VERSION ""

NS_ :

BS_:
BU_: GW IP HU TBOX AVM
BO_ 839 GW_347: 8 GW
 SG_ BCM_TirePresureSignalStatus : 55|1@0+ (1.0000000000,0.0000000000) [0.0000000000|1.0000000000] ""  GW,TBOX
 SG_ TPMS_SystemFailureWarning : 56|1@0+ (1.0000000000,0.0000000000) [0.0000000000|1.0000000000] ""  GW,IP
 SG_ TPMS_LRPressureWarning : 60|3@0+ (1.0000000000,0.0000000000) [0.0000000000|7.0000000000] ""  GW,TBOX,IP
 SG_ TPMS_RRPressureWarning : 63|3@0+ (1.0000000000,0.0000000000) [0.0000000000|7.0000000000] ""  GW,TBOX,IP
 SG_ TPMS_RFPressureWarning : 50|3@0+ (1.0000000000,0.0000000000) [0.0000000000|7.0000000000] ""  GW,TBOX,IP
 SG_ TPMS_LFPressureWarning : 54|3@0+ (1.0000000000,0.0000000000) [0.0000000000|7.0000000000] ""  GW,TBOX,IP
 SG_ TPMS_TireTemperature : 47|8@0+ (1.0000000000,-40.0000000000) [-40.0000000000|214.0000000000] "°C"  GW
 SG_ TPMS_LRTyrePressure : 39|8@0+ (1.3730000000,0.0000000000) [0.0000000000|350.0000000000] "KPa"  GW,TBOX,IP
 SG_ TPMS_RRTyrePressure : 31|8@0+ (1.3730000000,0.0000000000) [0.0000000000|350.0000000000] "KPa"  GW,TBOX,IP
 SG_ TPMS_RFTyrePressure : 23|8@0+ (1.3730000000,0.0000000000) [0.0000000000|350.0000000000] "KPa"  GW,TBOX,IP
 SG_ TPMS_LFTyrePressure : 15|8@0+ (1.3730000000,0.0000000000) [0.0000000000|350.0000000000] "KPa"  GW,TBOX,IP
 SG_ TPMS_TirePosition : 2|3@0+ (1.0000000000,0.0000000000) [0.0000000000|3.0000000000] ""  GW
 SG_ TPMS_LRTemperatureWarning : 3|1@0+ (1.0000000000,0.0000000000) [0.0000000000|1.0000000000] ""  GW,IP
 SG_ TPMS_RRTemperatureWarning : 4|1@0+ (1.0000000000,0.0000000000) [0.0000000000|1.0000000000] ""  GW,IP
 SG_ TPMS_RFTemperatureWarning : 5|1@0+ (1.0000000000,0.0000000000) [0.0000000000|1.0000000000] ""  GW,IP
 SG_ TPMS_LFTemperatureWarning : 6|1@0+ (1.0000000000,0.0000000000) [0.0000000000|1.0000000000] ""  GW,IP
 SG_ TPMS_SignalStatus : 7|1@0+ (1.0000000000,0.0000000000) [0.0000000000|1.0000000000] ""  GW,IP
 SG_ BCM_TirePresureSignalStatus : 55|1@0+ (1.0000000000,0.0000000000) [0.0000000000|1.0000000000] ""  IP,GW

BO_ 1025 IP_401: 8 IP

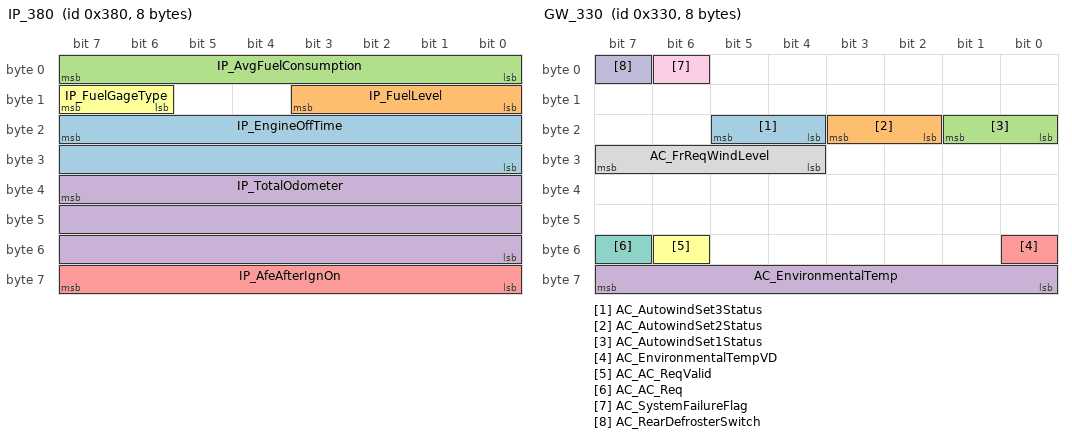
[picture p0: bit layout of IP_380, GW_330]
BO_ 896 IP_380: 8 IP
 SG_ IP_EngineOffTime : 23|16@0+ (1.0000000000,0.0000000000) [0.0000000000|65535.0000000000] "s"  GW,IP
 SG_ IP_FuelLevel : 11|4@0+ (1.0000000000,0.0000000000) [0.0000000000|15.0000000000] ""  HU,GW,IP
 SG_ IP_AvgFuelConsumption : 7|8@0+ (0.1000000000,0.0000000000) [0.0000000000|25.4000000000] "L/100Km"  GW,TBOX,HU,IP
 SG_ IP_TotalOdometer : 39|24@0+ (0.1000000000,0.0000000000) [0.0000000000|999999.0000000000] "Km"  GW,TBOX,HU,IP
 SG_ IP_AfeAfterIgnOn : 63|8@0+ (0.1000000000,0.0000000000) [0.0000000000|25.4000000000] "L/100Km"  GW,TBOX,IP
 SG_ IP_FuelGageType : 15|2@0+ (1.0000000000,0.0000000000) [0.0000000000|3.0000000000] ""  IP,GW

BO_ 614 GW_266: 8 GW
 SG_ PEPS_Easy_open : 48|1@0+ (1.0000000000,0.0000000000) [0.0000000000|1.0000000000] ""  GW
 SG_ PEPS_KeyNumber : 53|3@0+ (1.0000000000,0.0000000000) [0.0000000000|6.0000000000] ""  GW,HU
 SG_ PEPS_PEPSFailStatus : 54|1@0+ (1.0000000000,0.0000000000) [0.0000000000|1.0000000000] ""  GW,TBOX,IP
 SG_ PEPS_PowerDistributionFaultBit : 55|1@0+ (1.0000000000,0.0000000000) [0.0000000000|1.0000000000] ""  IP,GW
 SG_ PEPS_EngineStartupInhibitFb : 42|1@0+ (1.0000000000,0.0000000000) [0.0000000000|1.0000000000] ""  GW,TBOX
 SG_ PEPS_ImmoFeedback : 44|2@0+ (1.0000000000,0.0000000000) [0.0000000000|3.0000000000] ""  GW
 SG_ PEPS_KeyAuthenticationStatus : 47|2@0+ (1.0000000000,0.0000000000) [0.0000000000|3.0000000000] ""  GW
 SG_ PEPS_EngineStartupInhibitSts : 32|1@0+ (1.0000000000,0.0000000000) [0.0000000000|1.0000000000] ""  GW,TBOX
 SG_ PEPS_RemoteStartFeedback : 37|5@0+ (1.0000000000,0.0000000000) [0.0000000000|31.0000000000] ""  GW,TBOX
 SG_ PEPS_RemoteStartReq : 39|2@0+ (1.0000000000,0.0000000000) [0.0000000000|1.0000000000] ""  IP,GW,TBOX,HU
 SG_ PEPS_StartupButtonSignal : 25|2@0+ (1.0000000000,0.0000000000) [0.0000000000|3.0000000000] ""  GW
 SG_ PEPS_TrunkRequestSignal : 28|1@0+ (1.0000000000,0.0000000000) [0.0000000000|1.0000000000] ""  GW
 SG_ PEPS_DoorHandleButtonSignal : 29|1@0+ (1.0000000000,0.0000000000) [0.0000000000|1.0000000000] ""  GW
 SG_ PEPS_PowerDistributionStatus : 31|2@0+ (1.0000000000,0.0000000000) [0.0000000000|3.0000000000] ""  IP,GW
 SG_ PEPS_StartControlsignal : 17|2@0+ (1.0000000000,0.0000000000) [0.0000000000|3.0000000000] ""  GW
 SG_ PEPS_StartIndicatorSignal : 18|1@0+ (1.0000000000,0.0000000000) [0.0000000000|1.0000000000] ""  IP,GW
 SG_ PEPS_UnallowStart_ESCL_Error : 19|1@0+ (1.0000000000,0.0000000000) [0.0000000000|1.0000000000] ""  IP,GW
 SG_ PEPS_UnallowStart_ESCL_LOCK : 20|1@0+ (1.0000000000,0.0000000000) [0.0000000000|1.0000000000] ""  IP,GW
 SG_ PEPS_IMMOFailedAlarmsignal : 21|1@0+ (1.0000000000,0.0000000000) [0.0000000000|1.0000000000] ""  IP,GW
 SG_ PEPS_RemoteFailedAlarmSignal : 22|1@0+ (1.0000000000,0.0000000000) [0.0000000000|1.0000000000] ""  GW
 SG_ PEPS_UnallowStartSignal_Not_PN : 23|1@0+ (1.0000000000,0.0000000000) [0.0000000000|1.0000000000] ""  IP,GW
 SG_ PEPS_KeyUndetectedAlarmSignal : 8|1@0+ (1.0000000000,0.0000000000) [0.0000000000|1.0000000000] ""  IP,GW
 SG_ PEPS_KeyInCarAlarmSignal : 9|1@0+ (1.0000000000,0.0000000000) [0.0000000000|1.0000000000] ""  IP,GW
 SG_ PEPS_UnlockModeTransitionSignal : 10|1@0+ (1.0000000000,0.0000000000) [0.0000000000|1.0000000000] ""  GW
 SG_ PEPS_LuggageUnlockSignal : 12|2@0+ (1.0000000000,0.0000000000) [0.0000000000|3.0000000000] ""  GW
 SG_ PEPS_SearchCarSignal : 13|1@0+ (1.0000000000,0.0000000000) [0.0000000000|1.0000000000] ""  GW
 SG_ PEPS_RemoteWindowDownSignal : 14|1@0+ (1.0000000000,0.0000000000) [0.0000000000|1.0000000000] ""  GW
 SG_ PEPS_RemoteWindowUpSignal : 15|1@0+ (1.0000000000,0.0000000000) [0.0000000000|1.0000000000] ""  GW
 SG_ PEPS_LockSignal : 1|2@0+ (1.0000000000,0.0000000000) [0.0000000000|3.0000000000] ""  GW,HU,IP
 SG_ PEPS_UnlockSignal : 3|2@0+ (1.0000000000,0.0000000000) [0.0000000000|3.0000000000] ""  IP,HU,GW
 SG_ PEPS_KeyBatteryStatus : 4|1@0+ (1.0000000000,0.0000000000) [0.0000000000|1.0000000000] ""  IP,GW
 SG_ PEPS_KeyPositionStatus : 7|3@0+ (1.0000000000,0.0000000000) [0.0000000000|7.0000000000] ""  GW

BO_ 816 GW_330: 8 GW
 SG_ AC_AutowindSet3Status : 21|2@0+ (1.0000000000,0.0000000000) [0.0000000000|3.0000000000] ""  GW,HU
 SG_ AC_AutowindSet2Status : 19|2@0+ (1.0000000000,0.0000000000) [0.0000000000|3.0000000000] ""  GW,HU
 SG_ AC_AutowindSet1Status : 17|2@0+ (1.0000000000,0.0000000000) [0.0000000000|3.0000000000] ""  GW,HU
 SG_ AC_EnvironmentalTemp : 63|8@0+ (0.5000000000,-40.0000000000) [-40.0000000000|87.0000000000] "degree C"  GW,HU,IP
 SG_ AC_EnvironmentalTempVD : 48|1@0+ (1.0000000000,0.0000000000) [0.0000000000|1.0000000000] ""  GW,HU,IP
 SG_ AC_AC_ReqValid : 54|1@0+ (1.0000000000,0.0000000000) [0.0000000000|1.0000000000] ""  GW
 SG_ AC_AC_Req : 55|1@0+ (1.0000000000,0.0000000000) [0.0000000000|1.0000000000] ""  GW
 SG_ AC_FrReqWindLevel : 31|4@0+ (1.0000000000,0.0000000000) [0.0000000000|8.0000000000] ""  GW,HU
 SG_ AC_SystemFailureFlag : 6|1@0+ (1.0000000000,0.0000000000) [0.0000000000|1.0000000000] ""  GW,HU
 SG_ AC_RearDefrosterSwitch : 7|1@0+ (1.0000000000,0.0000000000) [0.0000000000|1.0000000000] ""  GW

BO_ 648 GW_288: 8 GW
 SG_ BCM_DriverDoorStatus : 23|1@0+ (1.0000000000,0.0000000000) [0.0000000000|1.0000000000] ""  GW,TBOX,HU,IP
 SG_ BCM_BuzzerWarningMode : 60|5@0+ (1.0000000000,0.0000000000) [0.0000000000|31.0000000000] ""  GW
 SG_ BCM_SystemFailureFlag : 61|1@0+ (1.0000000000,0.0000000000) [0.0000000000|1.0000000000] ""  GW
 SG_ BCM_LatchOverheatProtect : 62|1@0+ (1.0000000000,0.0000000000) [0.0000000000|1.0000000000] ""  GW
 SG_ BCM_FollowMeTurnon : 63|1@0+ (1.0000000000,0.0000000000) [0.0000000000|1.0000000000] ""  GW
 SG_ BCM_ReversePosition : 48|1@0+ (1.0000000000,0.0000000000) [0.0000000000|1.0000000000] ""  GW,HU
 SG_ BCM_TurnLightSwitchSts : 51|2@0+ (1.0000000000,0.0000000000) [0.0000000000|3.0000000000] ""  GW,HU
 SG_ BCM_KeyAlarmStatus : 53|2@0+ (1.0000000000,0.0000000000) [0.0000000000|3.0000000000] ""  GW,TBOX,HU
 SG_ BCM_Statusrainsensor : 54|1@0+ (1.0000000000,0.0000000000) [0.0000000000|1.0000000000] ""  GW
 SG_ BCM_KeyInSignal : 55|1@0+ (1.0000000000,0.0000000000) [0.0000000000|1.0000000000] ""  GW
 SG_ BCM_DriverDoorLockStatus : 41|2@0+ (1.0000000000,0.0000000000) [0.0000000000|3.0000000000] ""  GW,TBOX
 SG_ BCM_PowerStatusFeedback : 43|2@0+ (1.0000000000,0.0000000000) [0.0000000000|3.0000000000] ""  GW,TBOX,HU
 SG_ BCM_RearWiperStatus : 44|1@0+ (1.0000000000,0.0000000000) [0.0000000000|1.0000000000] ""  GW
 SG_ BCM_Statuslowbeam : 45|1@0+ (1.0000000000,0.0000000000) [0.0000000000|1.0000000000] ""  GW
 SG_ BCM_FrontWiperStatus : 47|2@0+ (1.0000000000,0.0000000000) [0.0000000000|3.0000000000] ""  GW
 SG_ BCM_RearDefrosterstatus : 33|2@0+ (1.0000000000,0.0000000000) [0.0000000000|3.0000000000] ""  GW,HU
 SG_ BCM_emergencylightstatus : 37|2@0+ (1.0000000000,0.0000000000) [0.0000000000|3.0000000000] ""  GW
 SG_ BCM_SunroofMotor : 39|2@0+ (1.0000000000,0.0000000000) [0.0000000000|3.0000000000] ""  GW
 SG_ BCM_RightRearWinMotor : 25|2@0+ (1.0000000000,0.0000000000) [0.0000000000|3.0000000000] ""  GW
 SG_ BCM_LeftRearWinMotor : 27|2@0+ (1.0000000000,0.0000000000) [0.0000000000|3.0000000000] ""  GW
 SG_ BCM_PassengerWinMotor : 29|2@0+ (1.0000000000,0.0000000000) [0.0000000000|3.0000000000] ""  GW
 SG_ BCM_DriverWinMotor : 31|2@0+ (1.0000000000,0.0000000000) [0.0000000000|3.0000000000] ""  GW
 SG_ BCM_AutoHeadlightSts : 16|1@0+ (1.0000000000,0.0000000000) [0.0000000000|1.0000000000] ""  GW
 SG_ BCM_SunroofStatus : 17|1@0+ (1.0000000000,0.0000000000) [0.0000000000|1.0000000000] ""  GW,TBOX
 SG_ BCM_HoodStatus : 18|1@0+ (1.0000000000,0.0000000000) [0.0000000000|1.0000000000] ""  GW,TBOX,HU
 SG_ BCM_TrunkDoorStatus : 19|1@0+ (1.0000000000,0.0000000000) [0.0000000000|1.0000000000] ""  GW,TBOX,HU
 SG_ BCM_RightRearDoorStatus : 20|1@0+ (1.0000000000,0.0000000000) [0.0000000000|1.0000000000] ""  GW,TBOX,HU
 SG_ BCM_LeftRearDoorStatus : 21|1@0+ (1.0000000000,0.0000000000) [0.0000000000|1.0000000000] ""  GW,TBOX,HU
 SG_ BCM_PassengerDoorStatus : 22|1@0+ (1.0000000000,0.0000000000) [0.0000000000|1.0000000000] ""  GW,TBOX,HU
 SG_ BCM_DriverDoorStatus : 23|1@0+ (1.0000000000,0.0000000000) [0.0000000000|1.0000000000] ""  GW,TBOX,HU
 SG_ BCM_FrontWashStatus : 9|2@0+ (1.0000000000,0.0000000000) [0.0000000000|3.0000000000] ""  GW
 SG_ BCM_PositionLampStatus : 11|2@0+ (1.0000000000,0.0000000000) [0.0000000000|3.0000000000] ""  GW,TBOX
 SG_ BCM_TurnIndicatorRight : 13|2@0+ (1.0000000000,0.0000000000) [0.0000000000|3.0000000000] ""  GW,TBOX
 SG_ BCM_TurnIndicatorLeft : 15|2@0+ (1.0000000000,0.0000000000) [0.0000000000|3.0000000000] ""  GW,TBOX
 SG_ BCM_RearFoglampStatus : 1|2@0+ (1.0000000000,0.0000000000) [0.0000000000|3.0000000000] ""  GW,TBOX
 SG_ BCM_FrontFoglampStatus : 3|2@0+ (1.0000000000,0.0000000000) [0.0000000000|3.0000000000] ""  GW,TBOX
 SG_ BCM_HighBeamStatus : 5|2@0+ (1.0000000000,0.0000000000) [0.0000000000|3.0000000000] ""  GW,TBOX,HU
 SG_ BCM_LowBeamStatus : 7|2@0+ (1.0000000000,0.0000000000) [0.0000000000|3.0000000000] ""  GW,TBOX,HU
 SG_ BCM_BuzzerWarningMode : 60|5@0+ (1.0000000000,0.0000000000) [0.0000000000|31.0000000000] ""  IP,GW
 SG_ BCM_FollowMeTurnon : 63|1@0+ (1.0000000000,0.0000000000) [0.0000000000|1.0000000000] ""  IP,GW
 SG_ BCM_ReversePosition : 48|1@0+ (1.0000000000,0.0000000000) [0.0000000000|1.0000000000] ""  GW,IP
 SG_ BCM_TurnLightSwitchSts : 51|2@0+ (1.0000000000,0.0000000000) [0.0000000000|3.0000000000] ""  GW,AVM,IP
 SG_ BCM_KeyAlarmStatus : 53|2@0+ (1.0000000000,0.0000000000) [0.0000000000|3.0000000000] ""  GW,IP
 SG_ BCM_Statusrainsensor : 54|1@0+ (1.0000000000,0.0000000000) [0.0000000000|1.0000000000] ""  IP,GW
 SG_ BCM_KeyInSignal : 55|1@0+ (1.0000000000,0.0000000000) [0.0000000000|1.0000000000] ""  IP,GW
 SG_ BCM_PowerStatusFeedback : 43|2@0+ (1.0000000000,0.0000000000) [0.0000000000|3.0000000000] ""  GW,IP,AVM
 SG_ BCM_Statuslowbeam : 45|1@0+ (1.0000000000,0.0000000000) [0.0000000000|1.0000000000] ""  IP,GW
 SG_ BCM_RearWiperStatus : 44|1@0+ (1.0000000000,0.0000000000) [0.0000000000|1.0000000000] ""  IP,GW
 SG_ BCM_SunroofStatus : 17|1@0+ (1.0000000000,0.0000000000) [0.0000000000|1.0000000000] ""  IP,GW
 SG_ BCM_HoodStatus : 18|1@0+ (1.0000000000,0.0000000000) [0.0000000000|1.0000000000] ""  GW,IP
 SG_ BCM_TrunkDoorStatus : 19|1@0+ (1.0000000000,0.0000000000) [0.0000000000|1.0000000000] ""  IP,GW
 SG_ BCM_RightRearDoorStatus : 20|1@0+ (1.0000000000,0.0000000000) [0.0000000000|1.0000000000] ""  IP,GW
 SG_ BCM_LeftRearDoorStatus : 21|1@0+ (1.0000000000,0.0000000000) [0.0000000000|1.0000000000] ""  IP,GW
 SG_ BCM_PassengerDoorStatus : 22|1@0+ (1.0000000000,0.0000000000) [0.0000000000|1.0000000000] ""  IP,GW
 SG_ BCM_DriverDoorStatus : 23|1@0+ (1.0000000000,0.0000000000) [0.0000000000|1.0000000000] ""  IP,GW
 SG_ BCM_PositionLampStatus : 11|2@0+ (1.0000000000,0.0000000000) [0.0000000000|3.0000000000] ""  IP,GW
 SG_ BCM_TurnIndicatorRight : 13|2@0+ (1.0000000000,0.0000000000) [0.0000000000|3.0000000000] ""  IP,GW,AVM
 SG_ BCM_TurnIndicatorLeft : 15|2@0+ (1.0000000000,0.0000000000) [0.0000000000|3.0000000000] ""  IP,GW,AVM
 SG_ BCM_RearFoglampStatus : 1|2@0+ (1.0000000000,0.0000000000) [0.0000000000|3.0000000000] ""  GW,IP
 SG_ BCM_FrontFoglampStatus : 3|2@0+ (1.0000000000,0.0000000000) [0.0000000000|3.0000000000] ""  GW,IP
 SG_ BCM_HighBeamStatus : 5|2@0+ (1.0000000000,0.0000000000) [0.0000000000|3.0000000000] ""  GW,IP
 SG_ BCM_LowBeamStatus : 7|2@0+ (1.0000000000,0.0000000000) [0.0000000000|3.0000000000] ""  GW,IP

BO_ 841 GW_349: 8 GW
 SG_ BCM_CarMode : 11|2@0+ (1.0000000000,0.0000000000) [0.0000000000|3.0000000000] ""  GW,HU
 SG_ BCM_PMSErrorFlag : 13|2@0+ (1.0000000000,0.0000000000) [0.0000000000|3.0000000000] ""  GW
 SG_ BCM_LowPowerWarning : 2|3@0+ (1.0000000000,0.0000000000) [0.0000000000|7.0000000000] ""  GW,HU
 SG_ BCM_PMSLevel : 5|3@0+ (1.0000000000,0.0000000000) [0.0000000000|7.0000000000] ""  GW,HU
 SG_ BCM_CarMode : 11|2@0+ (1.0000000000,0.0000000000) [0.0000000000|3.0000000000] ""  GW,IP
 SG_ BCM_LowPowerWarning : 2|3@0+ (1.0000000000,0.0000000000) [0.0000000000|7.0000000000] ""  GW,IP
 SG_ BCM_PMSLevel : 5|3@0+ (1.0000000000,0.0000000000) [0.0000000000|7.0000000000] ""  GW,IP

BO_ 640 IP_280: 8 IP
 SG_ IP_FuelLowVoiceAlarm : 8|1@0+ (1.0000000000,0.0000000000) [0.0000000000|1.0000000000] ""  IP,HU
 SG_ IP_WelcomeSoundAlarm : 22|1@0+ (1.0000000000,0.0000000000) [0.0000000000|1.0000000000] ""  IP,HU
 SG_ IP_SteeringReturnVoiceAlarm : 63|1@0+ (1.0000000000,0.0000000000) [0.0000000000|1.0000000000] ""  IP,HU
 SG_ IP_120kmVoiceAlarm : 32|1@0+ (1.0000000000,0.0000000000) [0.0000000000|1.0000000000] ""  IP,HU
 SG_ IP_DisAfterIgnOn : 21|14@0+ (0.1000000000,0.0000000000) [0.0000000000|999.9000000000] "Km"  GW,TBOX,IP
 SG_ IP_FuelLevelPercent : 62|7@0+ (1.0000000000,0.0000000000) [0.0000000000|100.0000000000] ""  GW,TBOX,IP
 SG_ IP_MaintainReset : 23|1@0+ (1.0000000000,0.0000000000) [0.0000000000|1.0000000000] ""  GW,HU,IP
 SG_ IP_FuelLeftover : 47|7@0+ (1.0000000000,0.0000000000) [0.0000000000|127.0000000000] "L"  GW,TBOX,HU,IP
 SG_ IP_FuelLow : 11|1@0+ (1.0000000000,0.0000000000) [0.0000000000|1.0000000000] ""  GW,TBOX,IP
 SG_ IP_ModeSeting : 39|2@0+ (1.0000000000,0.0000000000) [0.0000000000|3.0000000000] ""  GW,IP
 SG_ IP_FuelLeftover_AD : 40|9@0+ (1.0000000000,0.0000000000) [0.0000000000|300.0000000000] "欧姆"  IP,GW
 SG_ IP_PassengerLCDALEDSts : 34|1@0+ (1.0000000000,0.0000000000) [0.0000000000|1.0000000000] ""  IP,GW
 SG_ IP_DriverLCDALEDSts : 35|1@0+ (1.0000000000,0.0000000000) [0.0000000000|1.0000000000] ""  IP,GW
 SG_ EngineCoolanTemperatureHigh : 9|1@0+ (1.0000000000,0.0000000000) [0.0000000000|1.0000000000] ""  IP,GW
 SG_ IP_EngineOilPressureLowSts : 10|1@0+ (1.0000000000,0.0000000000) [0.0000000000|1.0000000000] ""  IP,GW
 SG_ IP_AirBagSysWarningLampSts : 15|2@0+ (1.0000000000,0.0000000000) [0.0000000000|3.0000000000] ""  IP,GW
 SG_ IP_DISFail : 2|1@0+ (1.0000000000,0.0000000000) [0.0000000000|1.0000000000] ""  IP,GW
 SG_ IP_QDashACCFail : 1|2@0+ (1.0000000000,0.0000000000) [0.0000000000|3.0000000000] ""  IP,GW

BO_ 608 IP_260: 8 IP
 SG_ IP_DTE : 25|10@0+ (1.0000000000,0.0000000000) [0.0000000000|999.0000000000] "KM"  HU,GW,TBOX,IP

BO_ 901 IP_385: 8 IP
 SG_ IP_RearSeatbeltWarningEnableFB : 9|2@0+ (1.0000000000,0.0000000000) [0.0000000000|3.0000000000] ""  HU,GW,IP
 SG_ IP_WarningVolumeSettingFB : 12|3@0+ (1.0000000000,0.0000000000) [0.0000000000|7.0000000000] ""  HU,GW,IP

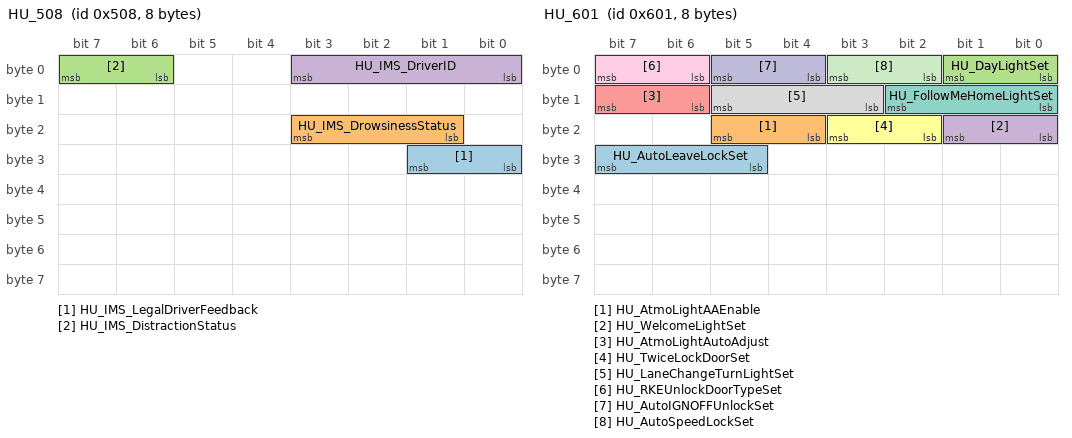
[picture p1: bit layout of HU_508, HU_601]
BO_ 1288 HU_508: 8 HU
 SG_ HU_IMS_LegalDriverFeedback : 25|2@0+ (1.0000000000,0.0000000000) [0.0000000000|3.0000000000] ""  HU,GW
 SG_ HU_IMS_DrowsinessStatus : 19|3@0+ (1.0000000000,0.0000000000) [0.0000000000|7.0000000000] ""  HU,GW,IP
 SG_ HU_IMS_DistractionStatus : 7|2@0+ (1.0000000000,0.0000000000) [0.0000000000|3.0000000000] ""  HU,GW,IP
 SG_ HU_IMS_DriverID : 3|4@0+ (1.0000000000,0.0000000000) [0.0000000000|15.0000000000] ""  HU,GW

BO_ 1537 HU_601: 8 HU
 SG_ HU_AutoLeaveLockSet : 31|3@0+ (1.0000000000,0.0000000000) [0.0000000000|7.0000000000] ""  HU,GW
 SG_ HU_AtmoLightAAEnable : 21|2@0+ (1.0000000000,0.0000000000) [0.0000000000|3.0000000000] ""  HU,GW
 SG_ HU_DayLightSet : 1|2@0+ (1.0000000000,0.0000000000) [0.0000000000|3.0000000000] ""  HU,GW
 SG_ HU_WelcomeLightSet : 17|2@0+ (1.0000000000,0.0000000000) [0.0000000000|3.0000000000] ""  HU,GW
 SG_ HU_AtmoLightAutoAdjust : 15|2@0+ (1.0000000000,0.0000000000) [0.0000000000|3.0000000000] ""  HU,GW
 SG_ HU_TwiceLockDoorSet : 19|2@0+ (1.0000000000,0.0000000000) [0.0000000000|3.0000000000] ""  HU,GW
 SG_ HU_FollowMeHomeLightSet : 10|3@0+ (1.0000000000,0.0000000000) [0.0000000000|7.0000000000] ""  HU,GW
 SG_ HU_LaneChangeTurnLightSet : 13|3@0+ (1.0000000000,0.0000000000) [0.0000000000|7.0000000000] ""  HU,GW
 SG_ HU_RKEUnlockDoorTypeSet : 7|2@0+ (1.0000000000,0.0000000000) [0.0000000000|3.0000000000] ""  HU,GW
 SG_ HU_AutoIGNOFFUnlockSet : 5|2@0+ (1.0000000000,0.0000000000) [0.0000000000|3.0000000000] ""  HU,GW
 SG_ HU_AutoSpeedLockSet : 3|2@0+ (1.0000000000,0.0000000000) [0.0000000000|3.0000000000] ""  HU,GW

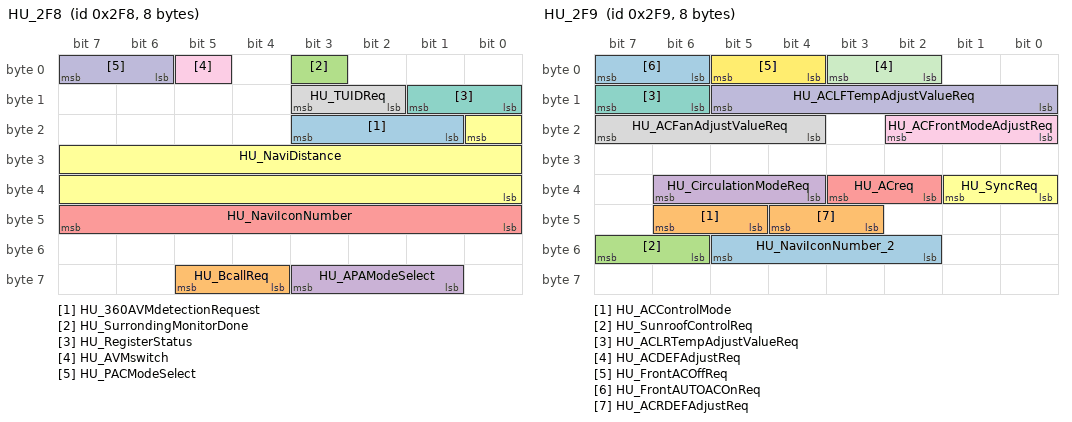
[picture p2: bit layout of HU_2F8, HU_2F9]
BO_ 760 HU_2F8: 8 HU
 SG_ HU_360AVMdetectionRequest : 19|3@0+ (1.0000000000,0.0000000000) [0.0000000000|7.0000000000] ""  HU,GW
 SG_ HU_BcallReq : 61|2@0+ (1.0000000000,0.0000000000) [0.0000000000|3.0000000000] ""  HU,TBOX,GW
 SG_ HU_SurrondingMonitorDone : 3|1@0+ (1.0000000000,0.0000000000) [0.0000000000|1.0000000000] ""  TBOX,HU,GW
 SG_ HU_APAModeSelect : 59|3@0+ (1.0000000000,0.0000000000) [0.0000000000|7.0000000000] ""  HU,GW
 SG_ HU_NaviIconNumber : 47|8@0+ (1.0000000000,0.0000000000) [0.0000000000|255.0000000000] ""  HU,GW
 SG_ HU_NaviDistance : 16|17@0+ (1.0000000000,0.0000000000) [0.0000000000|131070.0000000000] "m"  HU,GW
 SG_ HU_RegisterStatus : 9|2@0+ (1.0000000000,0.0000000000) [0.0000000000|3.0000000000] ""  HU,GW
 SG_ HU_TUIDReq : 11|2@0+ (1.0000000000,0.0000000000) [0.0000000000|3.0000000000] ""  HU,GW
 SG_ HU_AVMswitch : 5|1@0+ (1.0000000000,0.0000000000) [0.0000000000|1.0000000000] ""  HU,GW
 SG_ HU_PACModeSelect : 7|2@0+ (1.0000000000,0.0000000000) [0.0000000000|3.0000000000] ""  HU,GW

BO_ 761 HU_2F9: 8 HU
 SG_ HU_NaviIconNumber_2 : 53|4@0+ (1.0000000000,0.0000000000) [0.0000000000|15.0000000000] ""  HU,GW
 SG_ HU_ACControlMode : 46|2@0+ (1.0000000000,0.0000000000) [0.0000000000|3.0000000000] ""  HU,GW
 SG_ HU_SunroofControlReq : 55|2@0+ (1.0000000000,0.0000000000) [0.0000000000|3.0000000000] ""  HU,GW
 SG_ HU_CirculationModeReq : 38|3@0+ (1.0000000000,0.0000000000) [0.0000000000|7.0000000000] ""  HU,GW
 SG_ HU_ACreq : 35|2@0+ (1.0000000000,0.0000000000) [0.0000000000|3.0000000000] ""  HU,GW
 SG_ HU_SyncReq : 33|2@0+ (1.0000000000,0.0000000000) [0.0000000000|3.0000000000] ""  HU,GW
 SG_ HU_ACLRTempAdjustValueReq : 15|2@0+ (1.0000000000,0.0000000000) [0.0000000000|3.0000000000] "degree"  HU,GW
 SG_ HU_ACFanAdjustValueReq : 23|4@0+ (1.0000000000,0.0000000000) [0.0000000000|15.0000000000] ""  HU,GW
 SG_ HU_ACFrontModeAdjustReq : 18|3@0+ (1.0000000000,0.0000000000) [0.0000000000|7.0000000000] ""  HU,GW
 SG_ HU_ACLFTempAdjustValueReq : 13|6@0+ (0.5000000000,0.0000000000) [0.0000000000|63.0000000000] "degree"  HU,GW
 SG_ HU_ACDEFAdjustReq : 3|2@0+ (1.0000000000,0.0000000000) [0.0000000000|3.0000000000] ""  HU,GW
 SG_ HU_FrontACOffReq : 5|2@0+ (1.0000000000,0.0000000000) [0.0000000000|3.0000000000] ""  HU,GW
 SG_ HU_FrontAUTOACOnReq : 7|2@0+ (1.0000000000,0.0000000000) [0.0000000000|3.0000000000] ""  HU,GW
 SG_ HU_ACRDEFAdjustReq : 44|2@0+ (1.0000000000,1.0000000000) [0.0000000000|3.0000000000] ""  HU,GW

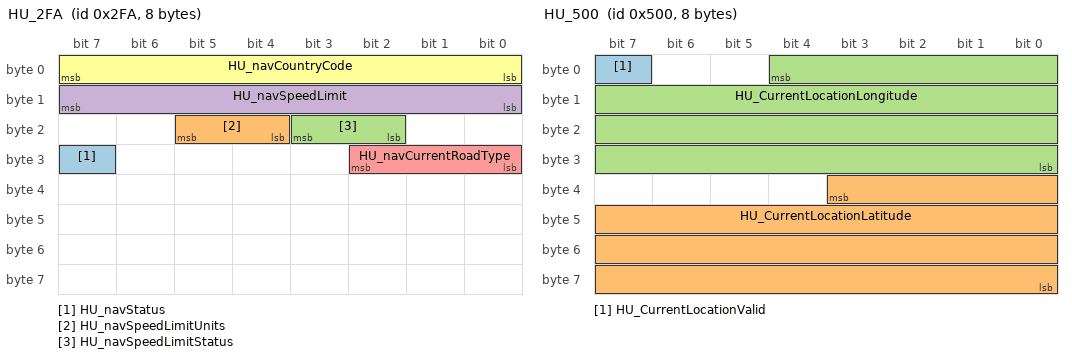
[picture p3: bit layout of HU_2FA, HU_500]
BO_ 762 HU_2FA: 8 HU
 SG_ HU_navStatus : 31|1@0+ (1.0000000000,1.0000000000) [0.0000000000|0.0000000000] ""  HU,GW
 SG_ HU_navSpeedLimitUnits : 21|2@0+ (1.0000000000,0.0000000000) [0.0000000000|3.0000000000] ""  HU,GW
 SG_ HU_navSpeedLimitStatus : 19|2@0+ (1.0000000000,0.0000000000) [0.0000000000|3.0000000000] ""  HU,GW
 SG_ HU_navSpeedLimit : 15|8@0+ (1.0000000000,0.0000000000) [0.0000000000|255.0000000000] ""  HU,GW
 SG_ HU_navCurrentRoadType : 26|3@0+ (1.0000000000,0.0000000000) [0.0000000000|8.0000000000] ""  HU,GW
 SG_ HU_navCountryCode : 7|8@0+ (1.0000000000,0.0000000000) [0.0000000000|255.0000000000] ""  HU,GW

BO_ 1041 HU_411: 8 HU

BO_ 1280 HU_500: 8 HU
 SG_ HU_CurrentLocationValid : 7|1@0+ (1.0000000000,0.0000000000) [0.0000000000|1.0000000000] ""  HU
 SG_ HU_CurrentLocationLatitude : 35|28@0+ (0.0000010000,0.0000000000) [-90.0000000000|90.0000000000] "degree"  HU
 SG_ HU_CurrentLocationLongitude : 4|29@0+ (0.0000010000,0.0000000000) [-180.0000000000|180.0000000000] "degree"  HU

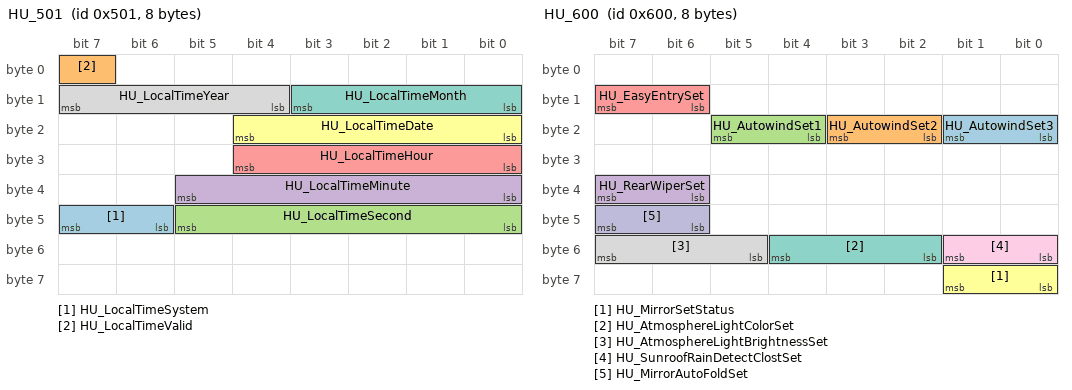
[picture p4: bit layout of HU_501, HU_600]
BO_ 1281 HU_501: 8 HU
 SG_ HU_LocalTimeSystem : 47|2@0+ (1.0000000000,0.0000000000) [0.0000000000|3.0000000000] ""  HU,GW
 SG_ HU_LocalTimeValid : 7|1@0+ (1.0000000000,0.0000000000) [0.0000000000|1.0000000000] ""  HU,GW
 SG_ HU_LocalTimeSecond : 45|6@0+ (1.0000000000,0.0000000000) [0.0000000000|59.0000000000] "second"  HU,GW
 SG_ HU_LocalTimeMinute : 37|6@0+ (1.0000000000,0.0000000000) [0.0000000000|59.0000000000] "minute"  HU,GW
 SG_ HU_LocalTimeHour : 28|5@0+ (1.0000000000,0.0000000000) [0.0000000000|23.0000000000] "hour"  HU,GW
 SG_ HU_LocalTimeDate : 20|5@0+ (1.0000000000,0.0000000000) [1.0000000000|31.0000000000] "day"  HU,GW
 SG_ HU_LocalTimeMonth : 11|4@0+ (1.0000000000,0.0000000000) [1.0000000000|12.0000000000] "month"  HU,GW
 SG_ HU_LocalTimeYear : 15|4@0+ (1.0000000000,2013.0000000000) [2013.0000000000|2028.0000000000] "year"  HU,GW

BO_ 1536 HU_600: 8 HU
 SG_ HU_AutowindSet3 : 17|2@0+ (1.0000000000,0.0000000000) [0.0000000000|3.0000000000] ""  HU,GW
 SG_ HU_AutowindSet2 : 19|2@0+ (1.0000000000,0.0000000000) [0.0000000000|3.0000000000] ""  HU,GW
 SG_ HU_AutowindSet1 : 21|2@0+ (1.0000000000,0.0000000000) [0.0000000000|3.0000000000] ""  HU,GW
 SG_ HU_RearWiperSet : 39|2@0+ (1.0000000000,0.0000000000) [0.0000000000|3.0000000000] ""  HU,GW
 SG_ HU_EasyEntrySet : 15|2@0+ (1.0000000000,0.0000000000) [0.0000000000|3.0000000000] ""  HU,GW
 SG_ HU_MirrorSetStatus : 57|2@0+ (1.0000000000,0.0000000000) [0.0000000000|3.0000000000] ""  HU,GW
 SG_ HU_AtmosphereLightColorSet : 52|3@0+ (1.0000000000,0.0000000000) [0.0000000000|7.0000000000] ""  HU,GW
 SG_ HU_AtmosphereLightBrightnessSet : 55|3@0+ (1.0000000000,0.0000000000) [0.0000000000|7.0000000000] ""  HU,GW
 SG_ HU_SunroofRainDetectClostSet : 49|2@0+ (1.0000000000,0.0000000000) [0.0000000000|3.0000000000] ""  HU,GW
 SG_ HU_MirrorAutoFoldSet : 47|2@0+ (1.0000000000,0.0000000000) [0.0000000000|3.0000000000] ""  HU,GW

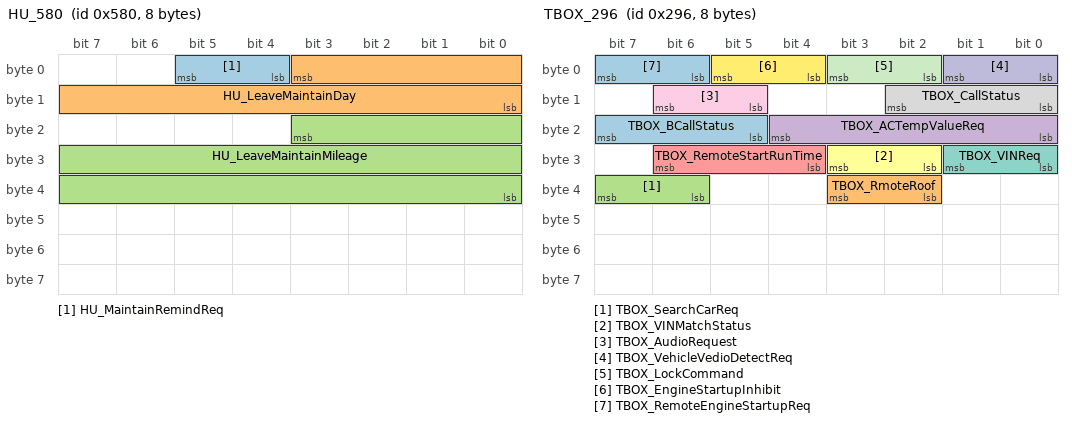
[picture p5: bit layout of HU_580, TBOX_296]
BO_ 1408 HU_580: 8 HU
 SG_ HU_MaintainRemindReq : 5|2@0+ (1.0000000000,0.0000000000) [0.0000000000|3.0000000000] ""  HU,GW
 SG_ HU_LeaveMaintainDay : 3|12@0+ (1.0000000000,0.0000000000) [0.0000000000|3100.0000000000] ""  HU,GW
 SG_ HU_LeaveMaintainMileage : 19|20@0+ (1.0000000000,0.0000000000) [0.0000000000|100000.0000000000] ""  HU,TBOX,GW

BO_ 1031 TBOX_407: 8 TBOX

BO_ 662 TBOX_296: 8 TBOX
 SG_ TBOX_BCallStatus : 23|3@0+ (1.0000000000,0.0000000000) [0.0000000000|7.0000000000] ""  TBOX,HU,GW
 SG_ TBOX_RmoteRoof : 35|2@0+ (1.0000000000,0.0000000000) [0.0000000000|3.0000000000] ""  TBOX,GW
 SG_ TBOX_SearchCarReq : 39|2@0+ (1.0000000000,0.0000000000) [0.0000000000|3.0000000000] ""  TBOX,GW
 SG_ TBOX_ACTempValueReq : 20|5@0+ (0.5000000000,17.5000000000) [18.0000000000|32.0000000000] "degree C"  TBOX,GW
 SG_ TBOX_RemoteStartRunTime : 30|3@0+ (1.0000000000,0.0000000000) [0.0000000000|7.0000000000] ""  TBOX,GW
 SG_ TBOX_VINMatchStatus : 27|2@0+ (1.0000000000,0.0000000000) [0.0000000000|3.0000000000] ""  TBOX,GW
 SG_ TBOX_VINReq : 25|2@0+ (1.0000000000,0.0000000000) [0.0000000000|3.0000000000] ""  TBOX,GW
 SG_ TBOX_CallStatus : 10|3@0+ (1.0000000000,0.0000000000) [0.0000000000|7.0000000000] ""  TBOX,HU,GW
 SG_ TBOX_AudioRequest : 14|2@0+ (1.0000000000,0.0000000000) [0.0000000000|3.0000000000] ""  TBOX,HU,GW
 SG_ TBOX_VehicleVedioDetectReq : 1|2@0+ (1.0000000000,0.0000000000) [0.0000000000|3.0000000000] ""  TBOX,GW,HU
 SG_ TBOX_LockCommand : 3|2@0+ (1.0000000000,0.0000000000) [0.0000000000|3.0000000000] ""  TBOX,GW
 SG_ TBOX_EngineStartupInhibit : 5|2@0+ (1.0000000000,0.0000000000) [0.0000000000|3.0000000000] ""  TBOX,GW
 SG_ TBOX_RemoteEngineStartupReq : 7|2@0+ (1.0000000000,0.0000000000) [0.0000000000|3.0000000000] ""  TBOX,GW

BO_ 1365 TBOX_555: 8 TBOX
 SG_ TBOX_CheckSum : 63|8@0+ (1.0000000000,0.0000000000) [0.0000000000|255.0000000000] ""  TBOX,HU

BO_ 992 GW_3E0: 8 GW
 SG_ AVM_OverspeedWarning : 8|1@0+ (1.0000000000,0.0000000000) [0.0000000000|1.0000000000] ""  HU,AVM,GW
 SG_ AVM_VisionAngle : 13|2@0+ (1.0000000000,0.0000000000) [0.0000000000|3.0000000000] ""  HU,AVM,GW
 SG_ AVM_DisplayForm : 3|4@0+ (1.0000000000,0.0000000000) [0.0000000000|15.0000000000] ""  HU,AVM,GW
 SG_ AVM_LineOnOff : 15|2@0+ (1.0000000000,0.0000000000) [0.0000000000|1.0000000000] ""  HU,AVM,GW
 SG_ AVM_DisplayReq : 7|2@0+ (1.0000000000,0.0000000000) [0.0000000000|3.0000000000] ""  HU,AVM,GW

BO_ 1535 GW_5FF: 8 GW
 SG_ BCM_MusicPlayRequestSignal : 47|2@0+ (1.0000000000,0.0000000000) [0.0000000000|3.0000000000] ""  GW,HU
 SG_ BCM_Musiclightfeedback : 55|2@0+ (1.0000000000,0.0000000000) [0.0000000000|3.0000000000] ""  GW,HU
 SG_ BCM_MusicPlayRequestSignal : 53|1@0+ (1.0000000000,0.0000000000) [0.0000000000|2.0000000000] ""  GW,HU
 SG_ BCM_OutWelcomeSoundFeedback : 52|3@0+ (1.0000000000,0.0000000000) [0.0000000000|7.0000000000] ""  GW,HU
 SG_ BCM_AutoLeaveLockSetStatus : 27|3@0+ (1.0000000000,0.0000000000) [0.0000000000|7.0000000000] ""  HU,GW
 SG_ BCM_AutoLockFeedback : 21|2@0+ (1.0000000000,0.0000000000) [0.0000000000|3.0000000000] ""  GW,TBOX
 SG_ BCM_WinOpenWarn : 19|1@0+ (1.0000000000,0.0000000000) [0.0000000000|1.0000000000] ""  GW,TBOX
 SG_ BCM_TwiceLockDoorSetStatus : 29|2@0+ (1.0000000000,0.0000000000) [0.0000000000|3.0000000000] ""  GW,HU
 SG_ BCM_RearWiperSetStatus : 7|2@0+ (1.0000000000,0.0000000000) [0.0000000000|3.0000000000] ""  GW,HU
 SG_ BCM_RemoteWindowDownSetStaus : 31|2@0+ (1.0000000000,0.0000000000) [0.0000000000|3.0000000000] ""  HU,GW
 SG_ BCM_SunroofRainSetStatus : 23|2@0+ (1.0000000000,0.0000000000) [0.0000000000|3.0000000000] ""  HU,GW
 SG_ BCM_MirrorAutoFoldSetStatus : 12|2@0+ (1.0000000000,0.0000000000) [0.0000000000|3.0000000000] ""  HU,GW
 SG_ BCM_FollowMeHomeLightSetStatus : 10|3@0+ (1.0000000000,0.0000000000) [0.0000000000|7.0000000000] ""  GW,HU
 SG_ BCM_LaneChangeTurnLightSetStatus : 18|3@0+ (1.0000000000,0.0000000000) [0.0000000000|7.0000000000] ""  GW,HU
 SG_ BCM_RKEUnlockDoorTypeSetStatus : 5|2@0+ (1.0000000000,0.0000000000) [0.0000000000|3.0000000000] ""  GW,HU
 SG_ BCM_AutoIGNOFFUnlockSetStatus : 3|2@0+ (1.0000000000,0.0000000000) [0.0000000000|3.0000000000] ""  GW,HU
 SG_ BCM_AutoSpeedLockSetStatus : 1|2@0+ (1.0000000000,0.0000000000) [0.0000000000|3.0000000000] ""  GW,HU

BO_ 1520 GW_5F0: 8 GW
 SG_ LCM_AtmoLightAutoAdjustSts : 21|2@0+ (1.0000000000,0.0000000000) [0.0000000000|3.0000000000] ""  GW,HU
 SG_ LCM_AtmoLightAAEnableSts : 23|2@0+ (1.0000000000,0.0000000000) [0.0000000000|3.0000000000] ""  GW,HU
 SG_ LCM_DRLSetFB : 1|2@0+ (1.0000000000,0.0000000000) [0.0000000000|3.0000000000] ""  GW,HU
 SG_ LCM_Dimmerlevel : 15|5@0+ (1.0000000000,0.0000000000) [0.0000000000|31.0000000000] ""  GW,HU,IP
 SG_ LCM_AmbientLightColorSetStas : 7|3@0+ (1.0000000000,0.0000000000) [0.0000000000|7.0000000000] ""  GW,HU
 SG_ LCM_AmbientLightBrightSetStas : 4|3@0+ (1.0000000000,0.0000000000) [0.0000000000|7.0000000000] ""  GW,HU

BO_ 614 GW_266: 8 GW
 SG_ PEPS_Easy_open : 48|1@0+ (1.0000000000,0.0000000000) [0.0000000000|1.0000000000] ""  GW
 SG_ PEPS_KeyNumber : 53|3@0+ (1.0000000000,0.0000000000) [0.0000000000|6.0000000000] ""  GW,HU
 SG_ PEPS_PEPSFailStatus : 54|1@0+ (1.0000000000,0.0000000000) [0.0000000000|1.0000000000] ""  GW,TBOX,IP
 SG_ PEPS_PowerDistributionFaultBit : 55|1@0+ (1.0000000000,0.0000000000) [0.0000000000|1.0000000000] ""  IP,GW
 SG_ PEPS_EngineStartupInhibitFb : 42|1@0+ (1.0000000000,0.0000000000) [0.0000000000|1.0000000000] ""  GW,TBOX
 SG_ PEPS_ImmoFeedback : 44|2@0+ (1.0000000000,0.0000000000) [0.0000000000|3.0000000000] ""  GW
 SG_ PEPS_KeyAuthenticationStatus : 47|2@0+ (1.0000000000,0.0000000000) [0.0000000000|3.0000000000] ""  GW
 SG_ PEPS_EngineStartupInhibitSts : 32|1@0+ (1.0000000000,0.0000000000) [0.0000000000|1.0000000000] ""  GW,TBOX
 SG_ PEPS_RemoteStartFeedback : 37|5@0+ (1.0000000000,0.0000000000) [0.0000000000|31.0000000000] ""  GW,TBOX
 SG_ PEPS_RemoteStartReq : 39|2@0+ (1.0000000000,0.0000000000) [0.0000000000|1.0000000000] ""  IP,GW,TBOX,HU
 SG_ PEPS_StartupButtonSignal : 25|2@0+ (1.0000000000,0.0000000000) [0.0000000000|3.0000000000] ""  GW
 SG_ PEPS_TrunkRequestSignal : 28|1@0+ (1.0000000000,0.0000000000) [0.0000000000|1.0000000000] ""  GW
 SG_ PEPS_DoorHandleButtonSignal : 29|1@0+ (1.0000000000,0.0000000000) [0.0000000000|1.0000000000] ""  GW
 SG_ PEPS_PowerDistributionStatus : 31|2@0+ (1.0000000000,0.0000000000) [0.0000000000|3.0000000000] ""  IP,GW
 SG_ PEPS_StartControlsignal : 17|2@0+ (1.0000000000,0.0000000000) [0.0000000000|3.0000000000] ""  GW
 SG_ PEPS_StartIndicatorSignal : 18|1@0+ (1.0000000000,0.0000000000) [0.0000000000|1.0000000000] ""  IP,GW
 SG_ PEPS_UnallowStart_ESCL_Error : 19|1@0+ (1.0000000000,0.0000000000) [0.0000000000|1.0000000000] ""  IP,GW
 SG_ PEPS_UnallowStart_ESCL_LOCK : 20|1@0+ (1.0000000000,0.0000000000) [0.0000000000|1.0000000000] ""  IP,GW
 SG_ PEPS_IMMOFailedAlarmsignal : 21|1@0+ (1.0000000000,0.0000000000) [0.0000000000|1.0000000000] ""  IP,GW
 SG_ PEPS_RemoteFailedAlarmSignal : 22|1@0+ (1.0000000000,0.0000000000) [0.0000000000|1.0000000000] ""  GW
 SG_ PEPS_UnallowStartSignal_Not_PN : 23|1@0+ (1.0000000000,0.0000000000) [0.0000000000|1.0000000000] ""  IP,GW
 SG_ PEPS_KeyUndetectedAlarmSignal : 8|1@0+ (1.0000000000,0.0000000000) [0.0000000000|1.0000000000] ""  IP,GW
 SG_ PEPS_KeyInCarAlarmSignal : 9|1@0+ (1.0000000000,0.0000000000) [0.0000000000|1.0000000000] ""  IP,GW
 SG_ PEPS_UnlockModeTransitionSignal : 10|1@0+ (1.0000000000,0.0000000000) [0.0000000000|1.0000000000] ""  GW
 SG_ PEPS_LuggageUnlockSignal : 12|2@0+ (1.0000000000,0.0000000000) [0.0000000000|3.0000000000] ""  GW
 SG_ PEPS_SearchCarSignal : 13|1@0+ (1.0000000000,0.0000000000) [0.0000000000|1.0000000000] ""  GW
 SG_ PEPS_RemoteWindowDownSignal : 14|1@0+ (1.0000000000,0.0000000000) [0.0000000000|1.0000000000] ""  GW
 SG_ PEPS_RemoteWindowUpSignal : 15|1@0+ (1.0000000000,0.0000000000) [0.0000000000|1.0000000000] ""  GW
 SG_ PEPS_LockSignal : 1|2@0+ (1.0000000000,0.0000000000) [0.0000000000|3.0000000000] ""  GW,HU,IP
 SG_ PEPS_UnlockSignal : 3|2@0+ (1.0000000000,0.0000000000) [0.0000000000|3.0000000000] ""  IP,HU,GW
 SG_ PEPS_KeyBatteryStatus : 4|1@0+ (1.0000000000,0.0000000000) [0.0000000000|1.0000000000] ""  IP,GW
 SG_ PEPS_KeyPositionStatus : 7|3@0+ (1.0000000000,0.0000000000) [0.0000000000|7.0000000000] ""  GW

BO_ 816 GW_330: 8 GW
 SG_ AC_AutowindSet3Status : 21|2@0+ (1.0000000000,0.0000000000) [0.0000000000|3.0000000000] ""  GW,HU
 SG_ AC_AutowindSet2Status : 19|2@0+ (1.0000000000,0.0000000000) [0.0000000000|3.0000000000] ""  GW,HU
 SG_ AC_AutowindSet1Status : 17|2@0+ (1.0000000000,0.0000000000) [0.0000000000|3.0000000000] ""  GW,HU
 SG_ AC_EnvironmentalTemp : 63|8@0+ (0.5000000000,-40.0000000000) [-40.0000000000|87.0000000000] "degree C"  GW,HU,IP
 SG_ AC_EnvironmentalTempVD : 48|1@0+ (1.0000000000,0.0000000000) [0.0000000000|1.0000000000] ""  GW,HU,IP
 SG_ AC_AC_ReqValid : 54|1@0+ (1.0000000000,0.0000000000) [0.0000000000|1.0000000000] ""  GW
 SG_ AC_AC_Req : 55|1@0+ (1.0000000000,0.0000000000) [0.0000000000|1.0000000000] ""  GW
 SG_ AC_FrReqWindLevel : 31|4@0+ (1.0000000000,0.0000000000) [0.0000000000|8.0000000000] ""  GW,HU
 SG_ AC_SystemFailureFlag : 6|1@0+ (1.0000000000,0.0000000000) [0.0000000000|1.0000000000] ""  GW,HU
 SG_ AC_RearDefrosterSwitch : 7|1@0+ (1.0000000000,0.0000000000) [0.0000000000|1.0000000000] ""  GW

BO_ 832 GW_340: 8 GW
 SG_ AC_ACOnOff : 47|2@0+ (1.0000000000,0.0000000000) [0.0000000000|3.0000000000] ""  GW
 SG_ AC_EnvironmentalTemp_RAW : 63|8@0+ (0.5000000000,-40.0000000000) [-40.0000000000|87.0000000000] "degree C"  GW
 SG_ AC_PlasmaSt : 53|1@0+ (1.0000000000,0.0000000000) [0.0000000000|1.0000000000] ""  GW,HU
 SG_ AC_AQSSt : 54|1@0+ (1.0000000000,0.0000000000) [0.0000000000|1.0000000000] ""  GW,HU
 SG_ AC_RecycleType : 42|3@0+ (1.0000000000,0.0000000000) [0.0000000000|7.0000000000] ""  GW,HU
 SG_ AC_ClimateDisplayReq : 45|1@0+ (1.0000000000,0.0000000000) [0.0000000000|1.0000000000] ""  GW,HU
 SG_ AC_PaReqTemp : 36|5@0+ (0.5000000000,17.5000000000) [18.0000000000|32.0000000000] "℃"  GW,HU
 SG_ AC_DriverReqTemp : 25|5@0+ (0.5000000000,17.5000000000) [18.0000000000|32.0000000000] "℃"  GW,HU
 SG_ AC_DriverReqTempModel : 23|5@0+ (1.0000000000,1.0000000000) [1.0000000000|16.0000000000] "档"  GW,HU
 SG_ AC_AutoWorkStatus : 4|2@0+ (1.0000000000,0.0000000000) [0.0000000000|3.0000000000] ""  HU,GW
 SG_ AC_FrAutoSts : 6|2@0+ (1.0000000000,0.0000000000) [0.0000000000|1.0000000000] ""  HU,GW
 SG_ AC_ACSt : 7|1@0+ (1.0000000000,0.0000000000) [0.0000000000|1.0000000000] ""  HU,GW
 SG_ AC_FrBlowType : 2|3@0+ (1.0000000000,0.0000000000) [0.0000000000|4.0000000000] ""  GW,HU

BO_ 896 GW_380: 8 GW
 SG_ IP_EngineOffTime : 23|16@0+ (1.0000000000,0.0000000000) [0.0000000000|65535.0000000000] "s"  GW,IP
 SG_ IP_FuelLevel : 11|4@0+ (1.0000000000,0.0000000000) [0.0000000000|15.0000000000] ""  HU,GW,IP
 SG_ IP_AvgFuelConsumption : 7|8@0+ (0.1000000000,0.0000000000) [0.0000000000|25.4000000000] "L/100Km"  GW,TBOX,HU,IP
 SG_ IP_TotalOdometer : 39|24@0+ (0.1000000000,0.0000000000) [0.0000000000|999999.0000000000] "Km"  GW,TBOX,HU,IP
 SG_ IP_AfeAfterIgnOn : 63|8@0+ (0.1000000000,0.0000000000) [0.0000000000|25.4000000000] "L/100Km"  GW,TBOX,IP
 SG_ IP_FuelGageType : 15|2@0+ (1.0000000000,0.0000000000) [0.0000000000|3.0000000000] ""  IP,GW

BO_ 688 GW_2B0: 8 GW
 SG_ EMS_SartPrompt : 53|2@0+ (1.0000000000,0.0000000000) [0.0000000000|3.0000000000] ""  GW
 SG_ EMS_ImmoConfiguration : 63|2@0+ (1.0000000000,0.0000000000) [0.0000000000|3.0000000000] ""  GW
 SG_ EPB_Status : 55|2@0+ (1.0000000000,0.0000000000) [0.0000000000|3.0000000000] ""  GW
 SG_ EPB_BrakeLightOnRequest : 42|2@0+ (1.0000000000,0.0000000000) [0.0000000000|3.0000000000] ""  GW
 SG_ TCU_GearShiftPositon : 46|4@0+ (1.0000000000,0.0000000000) [0.0000000000|15.0000000000] ""  GW,HU
 SG_ TCU_ShiftPostionValid : 47|1@0+ (1.0000000000,0.0000000000) [0.0000000000|1.0000000000] ""  GW,HU
 SG_ SAS_SteeringAngle : 31|16@0- (0.1000000000,0.0000000000) [-780.0000000000|779.9000000000] "degree"  GW,HU
 SG_ SRS_CrashOutputStatusCheckSum : 19|4@0+ (1.0000000000,0.0000000000) [0.0000000000|15.0000000000] ""  GW,TBOX
 SG_ SRS_CrashOutputStatus : 23|4@0+ (1.0000000000,0.0000000000) [0.0000000000|15.0000000000] ""  GW,TBOX
 SG_ EMS_ImmoFeedback : 9|2@0+ (1.0000000000,0.0000000000) [0.0000000000|3.0000000000] ""  GW
 SG_ TCU_STLKfailure : 11|2@0+ (1.0000000000,0.0000000000) [0.0000000000|3.0000000000] ""  GW
 SG_ EMS_EngineStartupEnd : 13|2@0+ (1.0000000000,0.0000000000) [0.0000000000|3.0000000000] ""  GW
 SG_ EMS_CompressorStatus : 15|2@0+ (1.0000000000,0.0000000000) [0.0000000000|3.0000000000] ""  GW
 SG_ SAS_SteeringAngleValid : 0|1@0+ (1.0000000000,0.0000000000) [0.0000000000|1.0000000000] ""  GW,HU
 SG_ SAS_Calibrated : 1|1@0+ (1.0000000000,0.0000000000) [0.0000000000|1.0000000000] ""  GW
 SG_ ESP_BrakeLightOnRequest : 3|2@0+ (1.0000000000,0.0000000000) [0.0000000000|3.0000000000] ""  GW
 SG_ EMS_EngineStatus : 5|2@0+ (1.0000000000,0.0000000000) [0.0000000000|3.0000000000] ""  GW,HU,TBOX
 SG_ EMS_BrakePedalStatus : 7|2@0+ (1.0000000000,0.0000000000) [0.0000000000|3.0000000000] ""  GW,HU

BO_ 800 GW_320: 8 GW
 SG_ EMS_EngineSpeed : 47|16@0+ (0.2500000000,0.0000000000) [0.0000000000|16383.5000000000] "Rpm"  GW,HU
 SG_ EPB_FailureLamp : 33|2@0+ (1.0000000000,0.0000000000) [0.0000000000|3.0000000000] ""  GW
 SG_ EMS_EngineSpeedError : 34|1@0+ (1.0000000000,0.0000000000) [0.0000000000|1.0000000000] ""  GW
 SG_ SAS_SASFailure : 36|1@0+ (1.0000000000,0.0000000000) [0.0000000000|1.0000000000] ""  GW
 SG_ ESP_ABSFailStatus : 37|1@0+ (1.0000000000,0.0000000000) [0.0000000000|1.0000000000] ""  GW,TBOX
 SG_ ESP_TCSFailStatus : 38|1@0+ (1.0000000000,0.0000000000) [0.0000000000|1.0000000000] ""  GW,TBOX
 SG_ EMS_CoolanTemperatureError : 39|1@0+ (1.0000000000,0.0000000000) [0.0000000000|1.0000000000] ""  GW
 SG_ EMS_MIL : 25|2@0+ (1.0000000000,0.0000000000) [0.0000000000|3.0000000000] ""  GW,TBOX
 SG_ SRS_WarningLampStatus : 27|2@0+ (1.0000000000,0.0000000000) [0.0000000000|3.0000000000] ""  GW,TBOX
 SG_ SRS_PassengerBuckleSwitchStatus : 29|2@0+ (1.0000000000,0.0000000000) [0.0000000000|3.0000000000] ""  GW
 SG_ SRS_DriverBuckleSwitchStatus : 31|2@0+ (1.0000000000,0.0000000000) [0.0000000000|3.0000000000] ""  GW
 SG_ ESP_VehicleSpeed : 12|13@0+ (0.0562500000,0.0000000000) [0.0000000000|360.0000000000] "km/h"  GW,HU,TBOX
 SG_ ESP_VehicleSpeedValid : 14|1@0+ (1.0000000000,0.0000000000) [0.0000000000|1.0000000000] ""  GW,HU,TBOX
 SG_ EMS_EngineCoolanTemperature : 7|8@0+ (0.7500000000,-48.0000000000) [-48.0000000000|142.5000000000] "degreeC"  GW

BO_ 806 GW_326: 8 GW
 SG_ EMS_TargetCruiseSpeed : 55|8@0+ (1.0000000000,0.0000000000) [0.0000000000|254.0000000000] "Km/h"  GW
 SG_ EMS_TotalOdometer : 31|24@0+ (0.1000000000,0.0000000000) [0.0000000000|999999.0000000000] "Km"  GW
 SG_ EMS_BatteryVoltage : 23|8@0+ (0.1000000000,0.0000000000) [0.0000000000|25.4000000000] "V"  GW
 SG_ EMS_FuelConsumption : 15|8@0+ (0.0150000000,0.0000000000) [0.0000000000|3.8100000000] "ml"  GW,HU
 SG_ EMS_SSMWarningLampCtrol : 0|1@0+ (1.0000000000,0.0000000000) [0.0000000000|1.0000000000] ""  GW
 SG_ EMS_CruiseUnavailDisplay : 1|1@0+ (1.0000000000,0.0000000000) [0.0000000000|1.0000000000] ""  GW
 SG_ EMS_IdleStopStatus : 2|1@0+ (1.0000000000,0.0000000000) [0.0000000000|1.0000000000] ""  GW,HU,TBOX
 SG_ EMS_CruiseIndicate : 3|1@0+ (1.0000000000,0.0000000000) [0.0000000000|1.0000000000] ""  GW
 SG_ EMS_CruiseControlStatus : 5|2@0+ (1.0000000000,0.0000000000) [0.0000000000|3.0000000000] ""  GW
 SG_ EMS_CruiseActiveIndicate : 7|1@0+ (1.0000000000,0.0000000000) [0.0000000000|1.0000000000] ""  GW

BO_ 810 GW_32A: 8 GW
 SG_ EMS_RemindGear : 6|3@0+ (1.0000000000,0.0000000000) [0.0000000000|7.0000000000] ""  GW
 SG_ ESP_HBBFunctionStatus : 58|2@0+ (1.0000000000,0.0000000000) [0.0000000000|3.0000000000] ""  GW
 SG_ EMS_RemindShiftGear : 63|2@0+ (1.0000000000,0.0000000000) [0.0000000000|3.0000000000] ""  GW
 SG_ ESP_AutoHoldAvailable : 48|1@0+ (1.0000000000,0.0000000000) [0.0000000000|1.0000000000] ""  GW
 SG_ ESP_HHC_Active : 49|1@0+ (1.0000000000,0.0000000000) [0.0000000000|1.0000000000] ""  GW
 SG_ ESP_AutoHoldActive : 50|1@0+ (1.0000000000,0.0000000000) [0.0000000000|1.0000000000] ""  GW
 SG_ ESP_HHC_Available : 51|1@0+ (1.0000000000,0.0000000000) [0.0000000000|1.0000000000] ""  GW
 SG_ TCU_GearForDisplay : 55|4@0+ (1.0000000000,0.0000000000) [0.0000000000|15.0000000000] ""  GW,HU
 SG_ ESP_HDC_STATUS : 41|2@0+ (1.0000000000,0.0000000000) [0.0000000000|3.0000000000] ""  GW
 SG_ EPB_FunctionLamp : 36|2@0+ (1.0000000000,0.0000000000) [0.0000000000|3.0000000000] ""  GW
 SG_ EPB_SwitchPosition : 38|2@0+ (1.0000000000,0.0000000000) [0.0000000000|3.0000000000] ""  GW
 SG_ EPB_SwitchPositionValid : 39|1@0+ (1.0000000000,0.0000000000) [0.0000000000|1.0000000000] ""  GW
 SG_ EPB_TextDisplay : 27|4@0+ (1.0000000000,0.0000000000) [0.0000000000|15.0000000000] ""  GW
 SG_ ESP_ESPActiveStatus : 29|1@0+ (1.0000000000,0.0000000000) [0.0000000000|1.0000000000] ""  GW
 SG_ EPS_EPSFailed : 33|1@0+ (1.0000000000,0.0000000000) [0.0000000000|1.0000000000] ""  GW,TBOX
 SG_ ESP_ESPFunctionStatus : 30|1@0+ (1.0000000000,0.0000000000) [0.0000000000|1.0000000000] ""  GW
 SG_ ESP_EBDFailStatus : 31|1@0+ (1.0000000000,0.0000000000) [0.0000000000|1.0000000000] ""  GW
 SG_ ACC_ACCMode : 10|3@0+ (1.0000000000,0.0000000000) [0.0000000000|7.0000000000] ""  GW
 SG_ AT_FailureLamp : 7|1@0+ (1.0000000000,0.0000000000) [0.0000000000|1.0000000000] ""  GW,TBOX

BO_ 883 GW_373: 8 GW
 SG_ EMS_AccPedal : 63|8@0+ (0.3920000000,0.0000000000) [0.0000000000|99.6000000000] ""  GW
 SG_ EMS_EngineThrottlePosition : 55|8@0+ (0.3920000000,0.0000000000) [0.0000000000|99.5680000000] "%"  GW
 SG_ EMS_IndicatedRealEngTorq : 23|16@0+ (0.0015260000,0.0000000000) [0.0000000000|100.0000000000] "%"  GW
 SG_ EMS_IndicatedDriverReqTorq : 7|16@0+ (0.0015260000,0.0000000000) [0.0000000000|100.0000000000] "%"  GW,HU

BO_ 839 GW_347: 8 GW
 SG_ BCM_TirePresureSignalStatus : 55|1@0+ (1.0000000000,0.0000000000) [0.0000000000|1.0000000000] ""  GW,TBOX
 SG_ TPMS_SystemFailureWarning : 56|1@0+ (1.0000000000,0.0000000000) [0.0000000000|1.0000000000] ""  GW,IP
 SG_ TPMS_LRPressureWarning : 60|3@0+ (1.0000000000,0.0000000000) [0.0000000000|7.0000000000] ""  GW,TBOX,IP
 SG_ TPMS_RRPressureWarning : 63|3@0+ (1.0000000000,0.0000000000) [0.0000000000|7.0000000000] ""  GW,TBOX,IP
 SG_ TPMS_RFPressureWarning : 50|3@0+ (1.0000000000,0.0000000000) [0.0000000000|7.0000000000] ""  GW,TBOX,IP
 SG_ TPMS_LFPressureWarning : 54|3@0+ (1.0000000000,0.0000000000) [0.0000000000|7.0000000000] ""  GW,TBOX,IP
 SG_ TPMS_TireTemperature : 47|8@0+ (1.0000000000,-40.0000000000) [-40.0000000000|214.0000000000] "°C"  GW
 SG_ TPMS_LRTyrePressure : 39|8@0+ (1.3730000000,0.0000000000) [0.0000000000|350.0000000000] "KPa"  GW,TBOX,IP
 SG_ TPMS_RRTyrePressure : 31|8@0+ (1.3730000000,0.0000000000) [0.0000000000|350.0000000000] "KPa"  GW,TBOX,IP
 SG_ TPMS_RFTyrePressure : 23|8@0+ (1.3730000000,0.0000000000) [0.0000000000|350.0000000000] "KPa"  GW,TBOX,IP
 SG_ TPMS_LFTyrePressure : 15|8@0+ (1.3730000000,0.0000000000) [0.0000000000|350.0000000000] "KPa"  GW,TBOX,IP
 SG_ TPMS_TirePosition : 2|3@0+ (1.0000000000,0.0000000000) [0.0000000000|3.0000000000] ""  GW
 SG_ TPMS_LRTemperatureWarning : 3|1@0+ (1.0000000000,0.0000000000) [0.0000000000|1.0000000000] ""  GW,IP
 SG_ TPMS_RRTemperatureWarning : 4|1@0+ (1.0000000000,0.0000000000) [0.0000000000|1.0000000000] ""  GW,IP
 SG_ TPMS_RFTemperatureWarning : 5|1@0+ (1.0000000000,0.0000000000) [0.0000000000|1.0000000000] ""  GW,IP
 SG_ TPMS_LFTemperatureWarning : 6|1@0+ (1.0000000000,0.0000000000) [0.0000000000|1.0000000000] ""  GW,IP
 SG_ TPMS_SignalStatus : 7|1@0+ (1.0000000000,0.0000000000) [0.0000000000|1.0000000000] ""  GW,IP
 SG_ BCM_TirePresureSignalStatus : 55|1@0+ (1.0000000000,0.0000000000) [0.0000000000|1.0000000000] ""  IP,GW

BO_ 886 GW_376: 8 GW
 SG_ SAS_SteeringAngleSpeed : 39|8@0+ (4.0000000000,0.0000000000) [0.0000000000|1016.0000000000] "deg/s"  GW
 SG_ EMS_EngineFuelCutOff : 28|1@0+ (1.0000000000,0.0000000000) [0.0000000000|1.0000000000] ""  GW
 SG_ EMS_ClutchPedalStatus : 30|2@0+ (1.0000000000,0.0000000000) [0.0000000000|3.0000000000] ""  GW
 SG_ EMS_ConditionIdle : 31|1@0+ (1.0000000000,0.0000000000) [0.0000000000|1.0000000000] ""  GW
 SG_ EMS_FrictionalTorq : 15|16@0+ (0.0015260000,0.0000000000) [0.0000000000|99.9987800000] "%"  GW
 SG_ EMS_TorqueConstant : 7|8@0+ (10.0000000000,0.0000000000) [0.0000000000|2540.0000000000] "NM"  GW

BO_ 900 GW_384: 8 GW
 SG_ BCM_LightSensor : 32|1@0+ (1.0000000000,0.0000000000) [0.0000000000|1.0000000000] ""  GW
 SG_ BCM_LockSignal : 44|2@0+ (1.0000000000,0.0000000000) [0.0000000000|3.0000000000] ""  GW,HU
 SG_ BCM_UnlockSignal : 46|2@0+ (1.0000000000,0.0000000000) [0.0000000000|3.0000000000] ""  GW,HU
 SG_ BCM_RemoteWindowDownSignal : 47|1@0+ (1.0000000000,0.0000000000) [0.0000000000|1.0000000000] ""  GW
 SG_ BCM_RmoteUnLockFeedback : 34|2@0+ (1.0000000000,0.0000000000) [0.0000000000|3.0000000000] ""  GW,TBOX
 SG_ BCM_RmoteLockeFeedback : 37|3@0+ (1.0000000000,0.0000000000) [0.0000000000|7.0000000000] ""  GW,TBOX
 SG_ BCM_CarRemindFeedback : 39|2@0+ (1.0000000000,0.0000000000) [0.0000000000|3.0000000000] ""  GW,TBOX
 SG_ BCM_RightRearWindowStatus : 31|8@0+ (0.5000000000,0.0000000000) [0.0000000000|100.0000000000] "%"  GW,TBOX
 SG_ BCM_LeftRearWindowStatus : 23|8@0+ (0.5000000000,0.0000000000) [0.0000000000|100.0000000000] "%"  GW,TBOX
 SG_ BCM_PassengerWindowStatus : 15|8@0+ (0.5000000000,0.0000000000) [0.0000000000|100.0000000000] "%"  GW,TBOX
 SG_ BCM_DriverWindowStatus : 7|8@0+ (0.5000000000,0.0000000000) [0.0000000000|100.0000000000] "%"  GW,TBOX
 SG_ BCM_LockSignal : 44|2@0+ (1.0000000000,0.0000000000) [0.0000000000|3.0000000000] ""  GW,IP
 SG_ BCM_UnlockSignal : 46|2@0+ (1.0000000000,0.0000000000) [0.0000000000|3.0000000000] ""  GW,IP

BO_ 1298 GW_512: 8 GW
 SG_ PEPS_VIN : 15|56@0+ (1.0000000000,0.0000000000) [0.0000000000|1.0000000000] ""  TBOX,GW
 SG_ PEPS_VINFrameNumber : 7|8@0+ (1.0000000000,0.0000000000) [0.0000000000|255.0000000000] ""  TBOX,GW

BO_ 630 GW_276: 2 GW
 SG_ ESCL_SteeringLockError : 15|1@0+ (1.0000000000,0.0000000000) [0.0000000000|1.0000000000] ""  GW
 SG_ ESCL_SteeringLockStuck : 4|1@0+ (1.0000000000,0.0000000000) [0.0000000000|1.0000000000] ""  GW
 SG_ ESCL_SteeringLockWait : 3|1@0+ (1.0000000000,0.0000000000) [0.0000000000|1.0000000000] ""  GW
 SG_ ESCL_SteeringLockStatusS301 : 2|3@0+ (1.0000000000,0.0000000000) [0.0000000000|7.0000000000] ""  GW
 SG_ ESCL_SteeringLockStatusReserve : 7|3@0+ (1.0000000000,0.0000000000) [0.0000000000|7.0000000000] ""  GW

BO_ 728 GW_2D8: 8 GW
 SG_ LAS_CheckSum : 63|8@0+ (1.0000000000,0.0000000000) [0.0000000000|255.0000000000] ""  GW
 SG_ LAS_AliveCounter : 51|4@0+ (1.0000000000,0.0000000000) [0.0000000000|15.0000000000] ""  GW
 SG_ LAS_HMALightDistribution : 47|1@0+ (1.0000000000,0.0000000000) [0.0000000000|1.0000000000] ""  GW
 SG_ LAS_HMAStatus : 13|2@0+ (1.0000000000,0.0000000000) [0.0000000000|3.0000000000] ""  GW
 SG_ LAS_SLASpdLimitUnits : 3|2@0+ (1.0000000000,0.0000000000) [0.0000000000|3.0000000000] ""  GW
 SG_ LAS_SLASpdLimit : 23|8@0+ (1.0000000000,0.0000000000) [0.0000000000|255.0000000000] ""  GW
 SG_ LAS_SLAState : 36|3@0+ (1.0000000000,0.0000000000) [0.0000000000|7.0000000000] ""  GW
 SG_ LAS_LKSStatus : 39|3@0+ (1.0000000000,0.0000000000) [0.0000000000|7.0000000000] ""  GW
 SG_ LAS_CalibrationStatus : 9|2@0+ (1.0000000000,0.0000000000) [0.0000000000|3.0000000000] ""  GW
 SG_ LAS_LDWReminder : 33|2@0+ (1.0000000000,0.0000000000) [0.0000000000|3.0000000000] ""  GW
 SG_ LAS_LASFailure : 27|2@0+ (1.0000000000,0.0000000000) [0.0000000000|3.0000000000] ""  GW
 SG_ LAS_SteeringTorqueReq : 46|11@0+ (0.0100000000,-8.0000000000) [-8.0000000000|8.0000000000] "Nm"  GW
 SG_ LAS_TakeoverReq : 10|1@0+ (1.0000000000,0.0000000000) [0.0000000000|1.0000000000] ""  GW
 SG_ LAS_LDWStatus : 5|2@0+ (1.0000000000,0.0000000000) [0.0000000000|3.0000000000] ""  GW
 SG_ LDW_VibrationWarning : 7|2@0+ (1.0000000000,0.0000000000) [0.0000000000|3.0000000000] ""  GW

BO_ 736 GW_2E0: 8 GW
 SG_ RRS_SystemFailureFlag : 59|1@0+ (1.0000000000,0.0000000000) [0.0000000000|1.0000000000] ""  GW,HU,IP
 SG_ RRS_WarningFrequency : 41|2@0+ (1.0000000000,0.0000000000) [0.0000000000|3.0000000000] ""  HU,GW,IP
 SG_ RRS_WarningType : 47|4@0+ (1.0000000000,0.0000000000) [0.0000000000|15.0000000000] ""  HU,GW,IP
 SG_ RRS_SwitchIndicatorError : 60|1@0+ (1.0000000000,0.0000000000) [0.0000000000|1.0000000000] ""  GW
 SG_ RRS_SpkErrFlag : 56|1@0+ (1.0000000000,0.0000000000) [0.0000000000|1.0000000000] ""  GW
 SG_ RRS_ctrlModulErrFlag : 48|1@0+ (1.0000000000,0.0000000000) [0.0000000000|1.0000000000] ""  GW
 SG_ RRS_BattVoltErrFlag : 49|1@0+ (1.0000000000,0.0000000000) [0.0000000000|1.0000000000] ""  GW
 SG_ RRS_RFMSnsErrFlag : 57|1@0+ (1.0000000000,0.0000000000) [0.0000000000|1.0000000000] ""  GW
 SG_ RRS_LFMSnsErrFlag : 58|1@0+ (1.0000000000,0.0000000000) [0.0000000000|1.0000000000] ""  GW
 SG_ RRS_RRMidSnsErrFlag : 50|1@0+ (1.0000000000,0.0000000000) [0.0000000000|1.0000000000] ""  IP,GW
 SG_ RRS_LRMidSnsErrFlag : 51|1@0+ (1.0000000000,0.0000000000) [0.0000000000|1.0000000000] ""  IP,GW
 SG_ RRS_RRCSnsErrFlag : 52|1@0+ (1.0000000000,0.0000000000) [0.0000000000|1.0000000000] ""  IP,GW
 SG_ RRS_LRCSnsErrFlag : 53|1@0+ (1.0000000000,0.0000000000) [0.0000000000|1.0000000000] ""  IP,GW
 SG_ RRS_RFCSnsErrFlag : 54|1@0+ (1.0000000000,0.0000000000) [0.0000000000|1.0000000000] ""  IP,GW
 SG_ RRS_LFCSnsErrFlag : 55|1@0+ (1.0000000000,0.0000000000) [0.0000000000|1.0000000000] ""  IP,GW
 SG_ RRS_RFMDistance : 27|4@0+ (1.0000000000,0.0000000000) [0.0000000000|15.0000000000] ""  IP,GW,HU
 SG_ RRS_LFMDistance : 31|4@0+ (1.0000000000,0.0000000000) [0.0000000000|15.0000000000] ""  IP,GW,HU
 SG_ RRS_LFCDistance : 19|4@0+ (1.0000000000,0.0000000000) [0.0000000000|15.0000000000] ""  GW,HU,IP
 SG_ RRS_RFCDistance : 23|4@0+ (1.0000000000,0.0000000000) [0.0000000000|15.0000000000] ""  IP,GW,HU
 SG_ RRS_LRCDistance : 11|4@0+ (1.0000000000,0.0000000000) [0.0000000000|15.0000000000] ""  IP,GW,HU
 SG_ RRS_RRCDistance : 15|4@0+ (1.0000000000,0.0000000000) [0.0000000000|15.0000000000] ""  IP,GW,HU
 SG_ RRS_LRMDistance : 3|4@0+ (1.0000000000,0.0000000000) [0.0000000000|15.0000000000] ""  IP,GW,HU
 SG_ RRS_RRMDistance : 7|4@0+ (1.0000000000,0.0000000000) [0.0000000000|15.0000000000] ""  IP,GW,HU

BO_ 608 GW_260: 8 GW
 SG_ IP_DTE : 25|10@0+ (1.0000000000,0.0000000000) [0.0000000000|999.0000000000] "KM"  HU,GW,TBOX,IP

BO_ 1300 HU_514: 8 HU
 SG_ HU_DSMMemoryPositionFeedback : 49|2@0+ (1.0000000000,0.0000000000) [0.0000000000|3.0000000000] ""  HU,GW
 SG_ HU_OverspeedWarningOffset : 38|5@0+ (1.0000000000,-10.0000000000) [-10.0000000000|10.0000000000] ""  GW,HU
 SG_ HU_OverspeedWarningEnable : 33|2@0+ (1.0000000000,0.0000000000) [0.0000000000|3.0000000000] ""  GW,HU
 SG_ HU_OverspeedSoundWarningEnable : 31|2@0+ (1.0000000000,0.0000000000) [0.0000000000|3.0000000000] ""  GW,HU
 SG_ HU_SEWEnable : 17|2@0+ (1.0000000000,0.0000000000) [0.0000000000|3.0000000000] ""  GW,HU
 SG_ HU_RCWSoundEnable : 19|2@0+ (1.0000000000,0.0000000000) [0.0000000000|3.0000000000] ""  GW,HU
 SG_ HU_LDWShakeLev : 23|2@0+ (1.0000000000,0.0000000000) [0.0000000000|3.0000000000] ""  GW,HU
 SG_ HU_LASWarningModeSelection : 10|3@0+ (1.0000000000,0.0000000000) [0.0000000000|7.0000000000] ""  GW,HU
 SG_ HU_SLASwitch : 11|1@0+ (1.0000000000,0.0000000000) [0.0000000000|1.0000000000] ""  GW,HU
 SG_ HU_HMAEnable : 12|1@0+ (1.0000000000,0.0000000000) [0.0000000000|1.0000000000] ""  GW,HU
 SG_ HU_RCWEnable : 14|2@0+ (1.0000000000,0.0000000000) [0.0000000000|3.0000000000] ""  GW,HU
 SG_ HU_CTAEnable : 0|2@0+ (1.0000000000,0.0000000000) [0.0000000000|3.0000000000] ""  GW,HU
 SG_ HU_BSDLCAEnable : 2|2@0+ (1.0000000000,0.0000000000) [0.0000000000|3.0000000000] ""  GW,HU
 SG_ HU_LASModeSelection : 5|3@0+ (1.0000000000,0.0000000000) [0.0000000000|7.0000000000] ""  GW,HU
 SG_ HU_LdwSensitivity : 7|2@0+ (1.0000000000,0.0000000000) [0.0000000000|3.0000000000] ""  GW,HU

BO_ 1301 HU_515: 8 HU
 SG_ HU_DistanceAlertEnable : 14|2@0+ (1.0000000000,0.0000000000) [0.0000000000|3.0000000000] ""  HU,GW
 SG_ HU_ACCObjEnable : 0|2@0+ (1.0000000000,0.0000000000) [0.0000000000|3.0000000000] ""  HU,GW
 SG_ HU_FCWSensitivity : 2|2@0+ (1.0000000000,0.0000000000) [0.0000000000|3.0000000000] ""  HU,GW
 SG_ HU_AutoBrakeEnable : 3|1@0+ (1.0000000000,0.0000000000) [0.0000000000|1.0000000000] ""  HU,GW
 SG_ HU_FCWEnable : 4|1@0+ (1.0000000000,0.0000000000) [0.0000000000|1.0000000000] ""  HU,GW
 SG_ HU_CruiseControlSet : 7|3@0+ (1.0000000000,0.0000000000) [0.0000000000|7.0000000000] ""  HU,GW

BO_ 729 GW_2D9: 8 GW
 SG_ LAS_CheckSum_idxxE : 63|8@0+ (1.0000000000,0.0000000000) [0.0000000000|254.0000000000] ""  GW
 SG_ LAS_RollingCounter_idxxE : 51|4@0+ (1.0000000000,0.0000000000) [0.0000000000|15.0000000000] ""  GW
 SG_ LDW_VoiceWarning : 37|2@0+ (1.0000000000,0.0000000000) [0.0000000000|3.0000000000] ""  GW
 SG_ LAS_OverspeedSoundWarning : 31|2@0+ (1.0000000000,0.0000000000) [0.0000000000|3.0000000000] ""  GW
 SG_ LAS_OverspeedVisualWarning : 17|2@0+ (1.0000000000,0.0000000000) [0.0000000000|3.0000000000] ""  GW
 SG_ LAS_OverspeedWarningOffset : 27|5@0+ (1.0000000000,-10.0000000000) [-10.0000000000|10.0000000000] "km/h"  GW,HU
 SG_ LAS_OverspeedWarningEnableStatus : 29|2@0+ (1.0000000000,0.0000000000) [0.0000000000|3.0000000000] ""  GW,HU
 SG_ LAS_RLaneMarkerType : 32|3@0+ (1.0000000000,0.0000000000) [0.0000000000|7.0000000000] ""  GW
 SG_ LAS_LLaneMarkerType : 35|3@0+ (1.0000000000,0.0000000000) [0.0000000000|7.0000000000] ""  GW
 SG_ LAS_HostLaneRightStatus : 20|3@0+ (1.0000000000,0.0000000000) [0.0000000000|7.0000000000] ""  GW
 SG_ LAS_HostLaneLeftStatus : 23|3@0+ (1.0000000000,0.0000000000) [0.0000000000|7.0000000000] ""  GW
 SG_ LAS_OverspeedSoundWarnEnaSts : 9|2@0+ (1.0000000000,0.0000000000) [0.0000000000|3.0000000000] ""  GW,HU
 SG_ LAS_LDWShakeLevStatus : 13|2@0+ (1.0000000000,0.0000000000) [0.0000000000|3.0000000000] ""  GW,HU
 SG_ LAS_LASWarningModeSelectStas : 0|3@0+ (1.0000000000,0.0000000000) [0.0000000000|7.0000000000] ""  GW,HU
 SG_ LAS_SLASwitchStatus : 1|1@0+ (1.0000000000,0.0000000000) [0.0000000000|1.0000000000] ""  GW,HU
 SG_ LAS_HMAEnableStatus : 2|1@0+ (1.0000000000,0.0000000000) [0.0000000000|1.0000000000] ""  GW,HU
 SG_ LAS_LASModeSelectionStatus : 5|3@0+ (1.0000000000,0.0000000000) [0.0000000000|7.0000000000] ""  GW,HU
 SG_ LAS_LdwSensitivityStatus : 7|2@0+ (1.0000000000,0.0000000000) [0.0000000000|3.0000000000] ""  GW,HU

BO_ 862 GW_35E: 8 GW
 SG_ ACC_CheckSum_id35E : 63|8@0+ (1.0000000000,0.0000000000) [0.0000000000|254.0000000000] ""  GW
 SG_ ACC_RollingCounter_id35E : 51|4@0+ (1.0000000000,0.0000000000) [0.0000000000|15.0000000000] ""  GW
 SG_ ACC_CruiseControlSetStatus : 47|3@0+ (1.0000000000,0.0000000000) [0.0000000000|7.0000000000] ""  HU,GW
 SG_ ACC_DistanceAlertEnableStatus : 33|2@0+ (1.0000000000,0.0000000000) [0.0000000000|3.0000000000] ""  HU,GW
 SG_ ACC_ACCObjEnableStatus : 35|2@0+ (1.0000000000,0.0000000000) [0.0000000000|3.0000000000] ""  HU,GW
 SG_ ACC_FCWSensitivityStatus : 37|2@0+ (1.0000000000,0.0000000000) [0.0000000000|3.0000000000] ""  HU,GW
 SG_ ACC_AutoBrakeEnableStatus : 38|1@0+ (1.0000000000,0.0000000000) [0.0000000000|1.0000000000] ""  HU,GW
 SG_ ACC_FCWEnableStatus : 39|1@0+ (1.0000000000,0.0000000000) [0.0000000000|1.0000000000] ""  HU,GW
 SG_ ACC_ACCFailInfo : 23|1@0+ (1.0000000000,0.0000000000) [0.0000000000|1.0000000000] ""  GW
 SG_ ACC_TakeOverReq : 8|1@0+ (1.0000000000,0.0000000000) [0.0000000000|1.0000000000] ""  GW
 SG_ ACC_ObjValid : 9|1@0+ (1.0000000000,0.0000000000) [0.0000000000|1.0000000000] ""  GW
 SG_ ACC_TimeGapSet : 12|3@0+ (1.0000000000,0.0000000000) [0.0000000000|7.0000000000] ""  GW
 SG_ ACC_DistanceTarObj : 15|3@0+ (1.0000000000,0.0000000000) [0.0000000000|7.0000000000] ""  GW
 SG_ ACC_SetSpeedDis : 7|8@0+ (1.0000000000,0.0000000000) [0.0000000000|254.0000000000] "Km/h"  GW

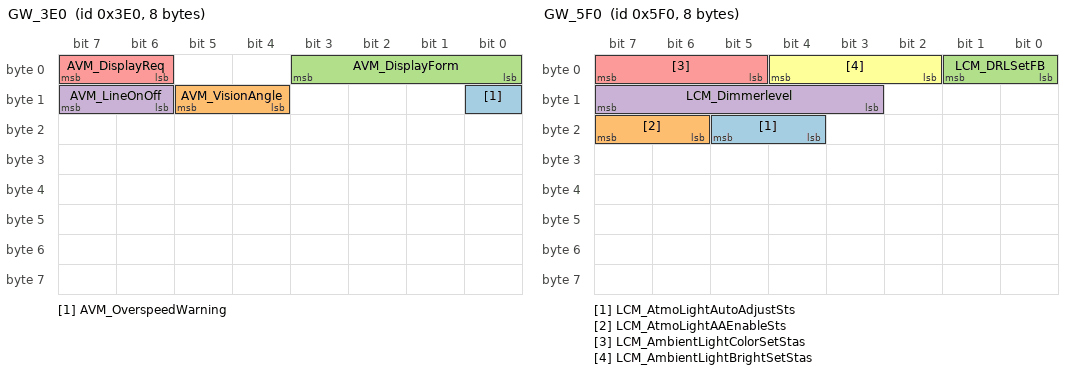
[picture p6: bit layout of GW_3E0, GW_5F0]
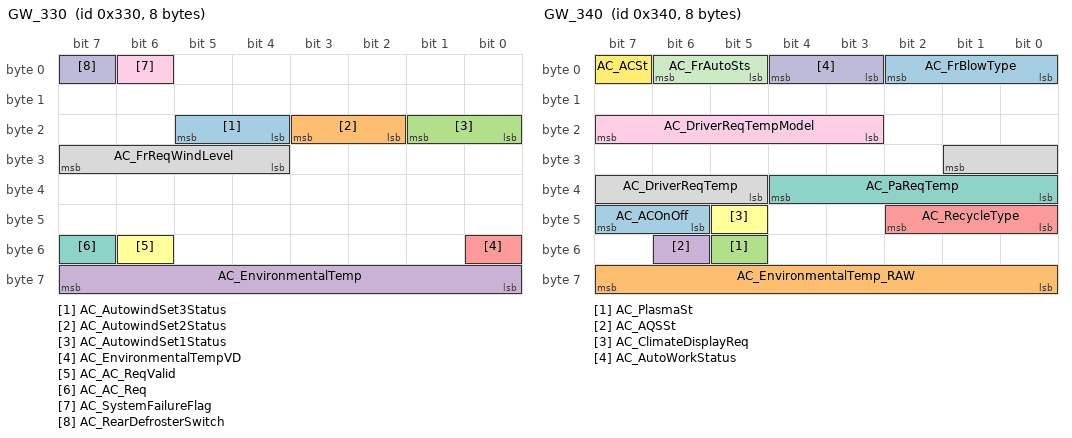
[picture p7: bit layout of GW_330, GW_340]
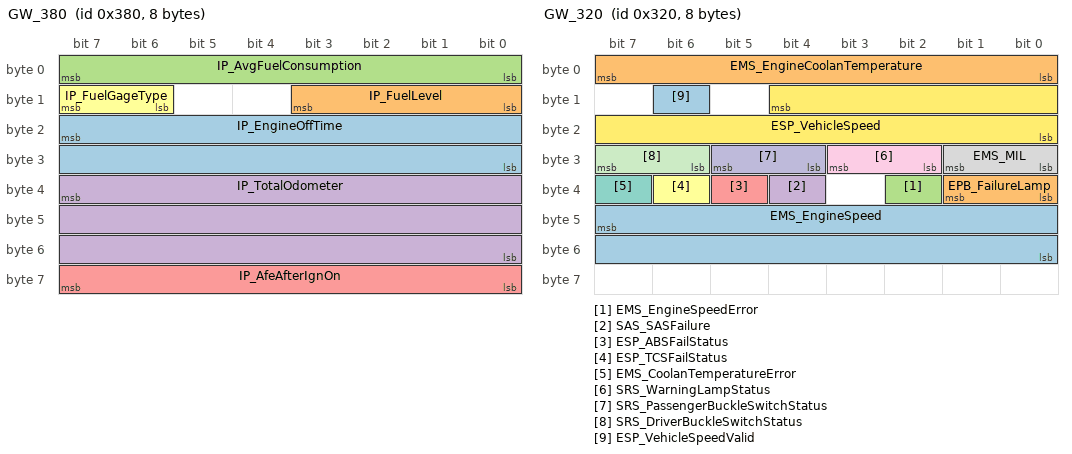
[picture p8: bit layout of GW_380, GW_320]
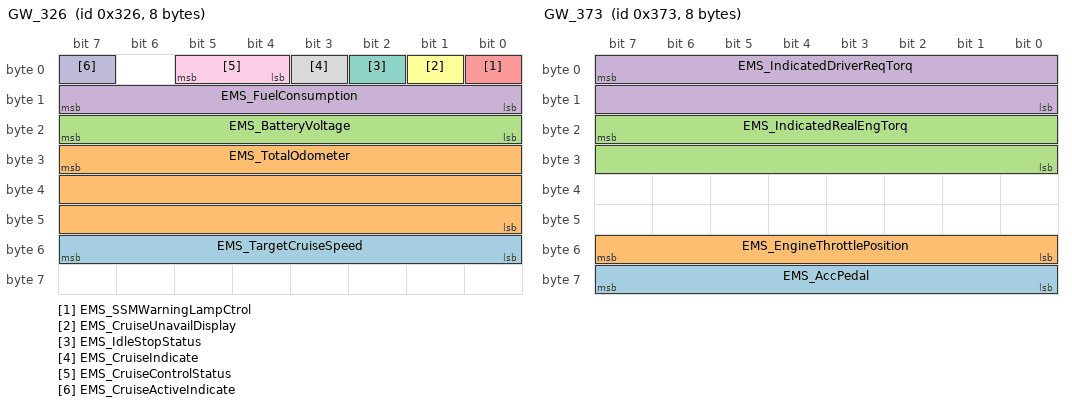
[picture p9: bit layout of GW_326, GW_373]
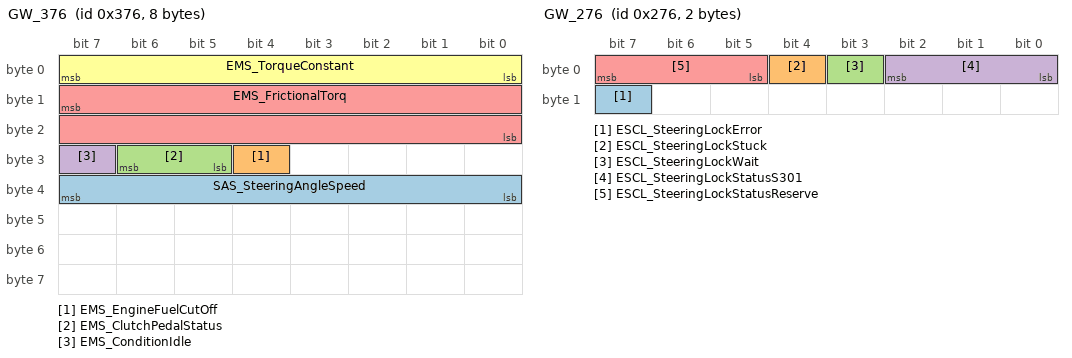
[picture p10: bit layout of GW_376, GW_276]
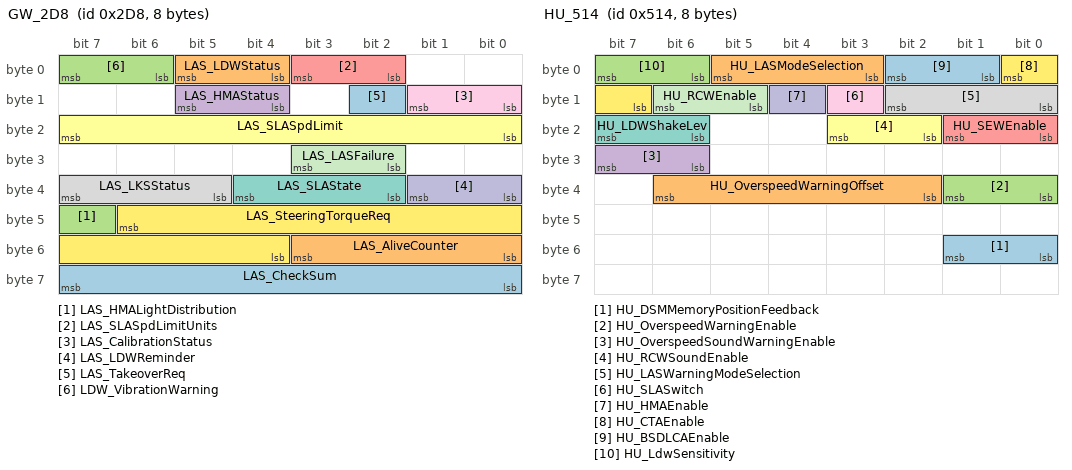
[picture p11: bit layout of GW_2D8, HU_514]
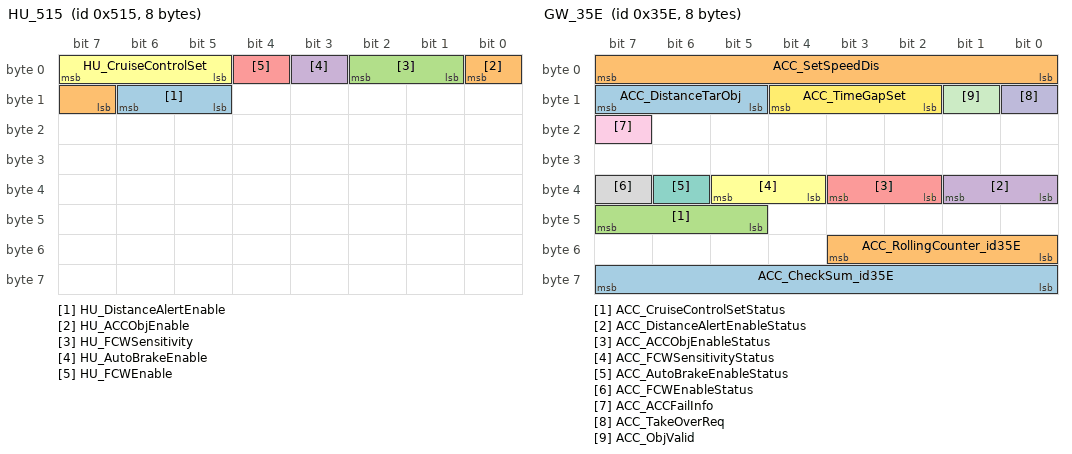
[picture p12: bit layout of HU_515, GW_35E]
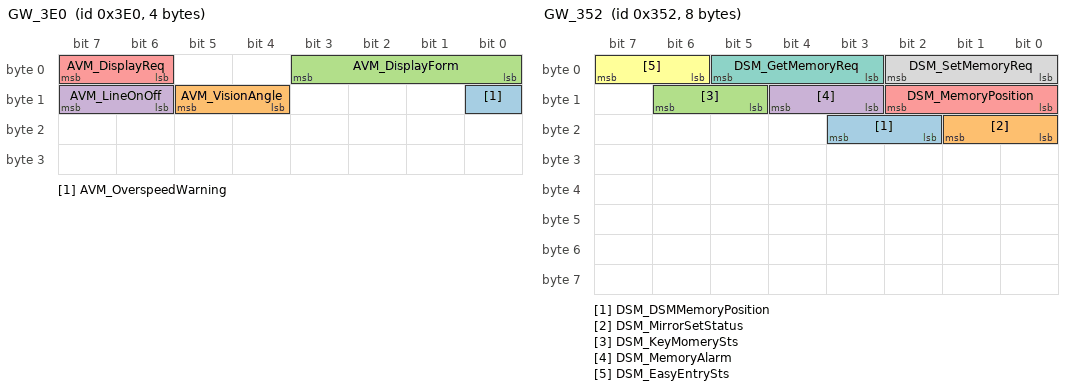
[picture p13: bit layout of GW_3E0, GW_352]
BO_ 992 GW_3E0: 4 GW
 SG_ AVM_OverspeedWarning : 8|1@0+ (1.0000000000,0.0000000000) [0.0000000000|1.0000000000] ""  HU,AVM,GW
 SG_ AVM_VisionAngle : 13|2@0+ (1.0000000000,0.0000000000) [0.0000000000|3.0000000000] ""  HU,AVM,GW
 SG_ AVM_DisplayForm : 3|4@0+ (1.0000000000,0.0000000000) [0.0000000000|15.0000000000] ""  HU,AVM,GW
 SG_ AVM_LineOnOff : 15|2@0+ (1.0000000000,0.0000000000) [0.0000000000|1.0000000000] ""  HU,AVM,GW
 SG_ AVM_DisplayReq : 7|2@0+ (1.0000000000,0.0000000000) [0.0000000000|3.0000000000] ""  HU,AVM,GW

BO_ 850 GW_352: 8 GW
 SG_ DSM_DSMMemoryPosition : 19|2@0+ (1.0000000000,0.0000000000) [0.0000000000|3.0000000000] ""  GW,HU
 SG_ DSM_MirrorSetStatus : 17|2@0+ (1.0000000000,0.0000000000) [0.0000000000|3.0000000000] ""  GW,HU
 SG_ DSM_KeyMomerySts : 14|2@0+ (1.0000000000,0.0000000000) [0.0000000000|3.0000000000] ""  GW
 SG_ DSM_MemoryAlarm : 12|2@0+ (1.0000000000,0.0000000000) [0.0000000000|3.0000000000] ""  IP,GW,HU
 SG_ DSM_MemoryPosition : 10|3@0+ (1.0000000000,0.0000000000) [0.0000000000|7.0000000000] ""  GW
 SG_ DSM_EasyEntrySts : 7|2@0+ (1.0000000000,0.0000000000) [0.0000000000|3.0000000000] ""  GW,HU
 SG_ DSM_GetMemoryReq : 5|3@0+ (1.0000000000,0.0000000000) [0.0000000000|7.0000000000] ""  GW
 SG_ DSM_SetMemoryReq : 2|3@0+ (1.0000000000,0.0000000000) [0.0000000000|7.0000000000] ""  GW

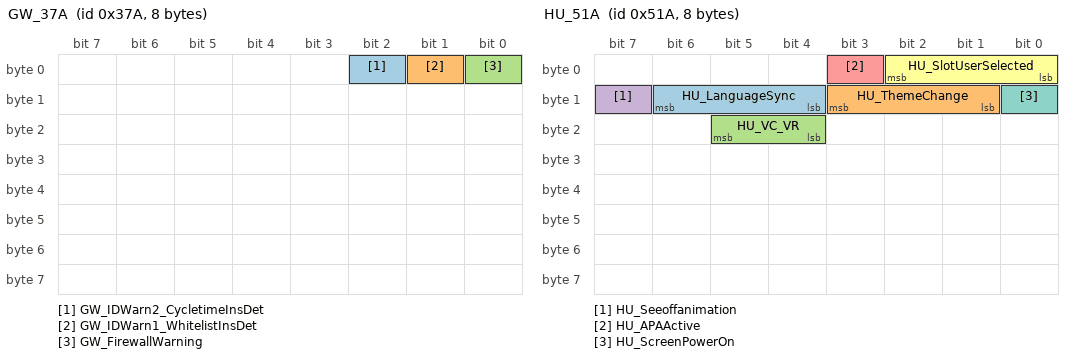
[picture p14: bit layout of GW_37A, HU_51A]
BO_ 890 GW_37A: 8 GW
 SG_ GW_IDWarn2_CycletimeInsDet : 2|1@0+ (1.0000000000,0.0000000000) [0.0000000000|1.0000000000] ""  GW
 SG_ GW_IDWarn1_WhitelistInsDet : 1|1@0+ (1.0000000000,0.0000000000) [0.0000000000|1.0000000000] ""  GW
 SG_ GW_FirewallWarning : 0|1@0+ (1.0000000000,0.0000000000) [0.0000000000|1.0000000000] ""  GW

BO_ 1306 HU_51A: 8 HU
 SG_ HU_LanguageSync : 14|3@0+ (1.0000000000,0.0000000000) [0.0000000000|7.0000000000] ""  HU,GW
 SG_ HU_ThemeChange : 11|3@0+ (1.0000000000,0.0000000000) [0.0000000000|7.0000000000] ""  HU,GW
 SG_ HU_VC_VR : 21|2@0+ (1.0000000000,0.0000000000) [0.0000000000|3.0000000000] ""  HU,GW
 SG_ HU_Seeoffanimation : 15|1@0+ (1.0000000000,0.0000000000) [0.0000000000|1.0000000000] ""  HU,GW
 SG_ HU_APAActive : 3|1@0+ (1.0000000000,0.0000000000) [0.0000000000|1.0000000000] ""  HU,GW
 SG_ HU_SlotUserSelected : 2|3@0+ (1.0000000000,0.0000000000) [0.0000000000|7.0000000000] ""  HU,GW
 SG_ HU_ScreenPowerOn : 8|1@0+ (1.0000000000,0.0000000000) [0.0000000000|1.0000000000] ""  HU,GW

BO_ 808 GW_328: 8 GW
 SG_ LCM_LASSwitch : 17|2@0+ (1.0000000000,0.0000000000) [0.0000000000|3.0000000000] ""  HU,GW

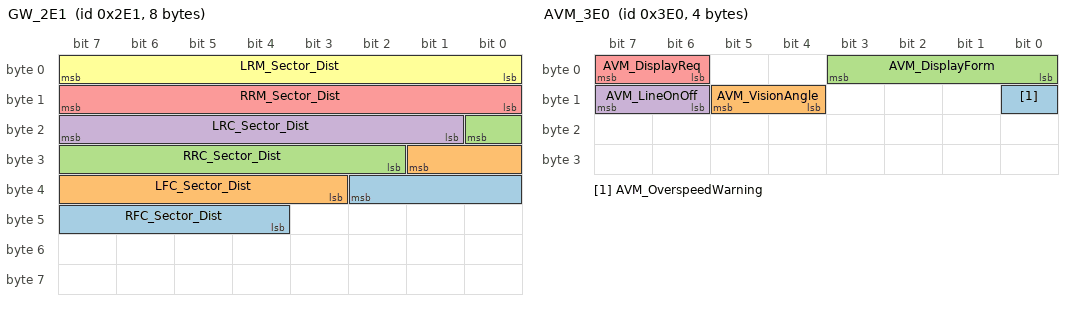
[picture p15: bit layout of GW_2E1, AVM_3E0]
BO_ 737 GW_2E1: 8 GW
 SG_ RFC_Sector_Dist : 34|7@0+ (1.0000000000,0.0000000000) [0.0000000000|127.0000000000] "cm"  HU,GW,IP
 SG_ LFC_Sector_Dist : 25|7@0+ (1.0000000000,0.0000000000) [0.0000000000|127.0000000000] "cm"  HU,GW,IP
 SG_ RRC_Sector_Dist : 16|7@0+ (1.0000000000,0.0000000000) [0.0000000000|127.0000000000] "cm"  HU,GW,IP
 SG_ LRC_Sector_Dist : 23|7@0+ (1.0000000000,0.0000000000) [0.0000000000|127.0000000000] "cm"  HU,GW,IP
 SG_ RRM_Sector_Dist : 15|8@0+ (1.0000000000,0.0000000000) [0.0000000000|255.0000000000] "cm"  HU,GW,IP
 SG_ LRM_Sector_Dist : 7|8@0+ (1.0000000000,0.0000000000) [0.0000000000|255.0000000000] "cm"  HU,GW,IP

BO_ 1043 AVM_413: 8 AVM

BO_ 992 AVM_3E0: 4 AVM
 SG_ AVM_OverspeedWarning : 8|1@0+ (1.0000000000,0.0000000000) [0.0000000000|1.0000000000] ""  HU,AVM,GW
 SG_ AVM_VisionAngle : 13|2@0+ (1.0000000000,0.0000000000) [0.0000000000|3.0000000000] ""  HU,AVM,GW
 SG_ AVM_DisplayForm : 3|4@0+ (1.0000000000,0.0000000000) [0.0000000000|15.0000000000] ""  HU,AVM,GW
 SG_ AVM_LineOnOff : 15|2@0+ (1.0000000000,0.0000000000) [0.0000000000|1.0000000000] ""  HU,AVM,GW
 SG_ AVM_DisplayReq : 7|2@0+ (1.0000000000,0.0000000000) [0.0000000000|3.0000000000] ""  HU,AVM,GW

BO_ 1717 AVM_6B5: 8 AVM

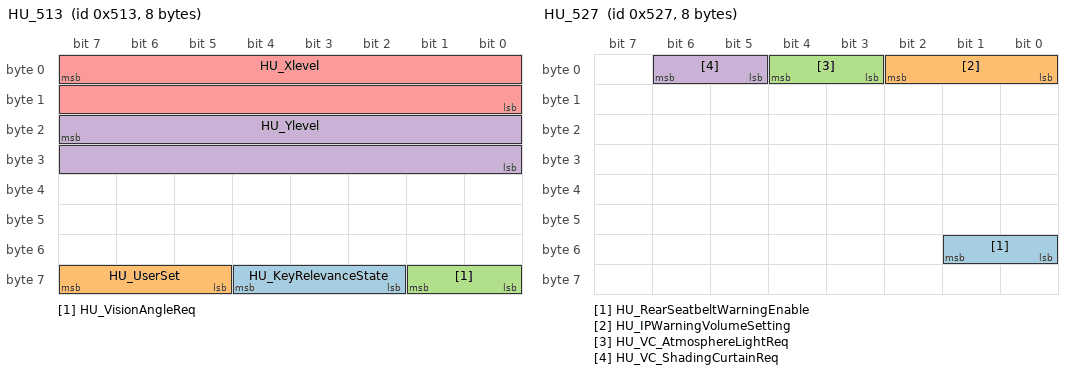
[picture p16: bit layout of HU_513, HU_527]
BO_ 1299 HU_513: 8 HU
 SG_ HU_KeyRelevanceState : 60|3@0+ (1.0000000000,0.0000000000) [0.0000000000|7.0000000000] ""  HU,GW
 SG_ HU_UserSet : 63|3@0+ (1.0000000000,0.0000000000) [0.0000000000|7.0000000000] ""  HU,GW
 SG_ HU_VisionAngleReq : 57|2@0+ (1.0000000000,0.0000000000) [0.0000000000|3.0000000000] ""  HU,GW
 SG_ HU_Ylevel : 23|16@0+ (1.0000000000,0.0000000000) [0.0000000000|480.0000000000] ""  HU,GW
 SG_ HU_Xlevel : 7|16@0+ (1.0000000000,0.0000000000) [0.0000000000|800.0000000000] ""  HU,GW

BO_ 610 GW_262: 8 GW
 SG_ PEPS_WelcomeLightStaus : 15|2@0+ (1.0000000000,0.0000000000) [0.0000000000|3.0000000000] ""  GW,HU

BO_ 1319 HU_527: 8 HU
 SG_ HU_RearSeatbeltWarningEnable : 49|2@0+ (1.0000000000,0.0000000000) [0.0000000000|3.0000000000] ""  HU,GW
 SG_ HU_IPWarningVolumeSetting : 2|3@0+ (1.0000000000,0.0000000000) [0.0000000000|7.0000000000] ""  HU,GW
 SG_ HU_VC_AtmosphereLightReq : 4|2@0+ (1.0000000000,0.0000000000) [0.0000000000|3.0000000000] ""  HU,GW
 SG_ HU_VC_ShadingCurtainReq : 6|2@0+ (1.0000000000,0.0000000000) [0.0000000000|3.0000000000] ""  HU,GW

BO_ 901 GW_385: 8 GW
 SG_ IP_RearSeatbeltWarningEnableFB : 9|2@0+ (1.0000000000,0.0000000000) [0.0000000000|3.0000000000] ""  HU,GW,IP
 SG_ IP_WarningVolumeSettingFB : 12|3@0+ (1.0000000000,0.0000000000) [0.0000000000|7.0000000000] ""  HU,GW,IP

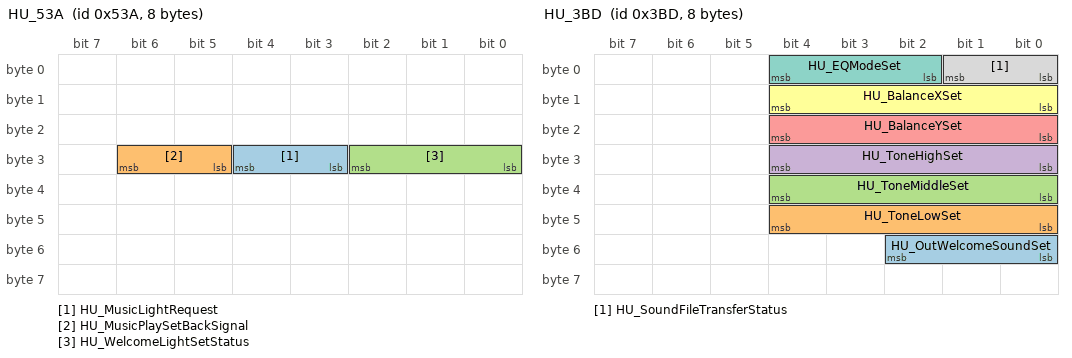
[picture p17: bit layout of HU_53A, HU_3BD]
BO_ 1338 HU_53A: 8 HU
 SG_ HU_MusicLightRequest : 28|2@0+ (1.0000000000,0.0000000000) [0.0000000000|3.0000000000] ""  HU,GW
 SG_ HU_MusicPlaySetBackSignal : 30|2@0+ (1.0000000000,0.0000000000) [0.0000000000|3.0000000000] ""  HU,GW
 SG_ HU_WelcomeLightSetStatus : 26|3@0+ (1.0000000000,0.0000000000) [0.0000000000|7.0000000000] ""  HU,GW

BO_ 957 HU_3BD: 8 HU
 SG_ HU_OutWelcomeSoundSet : 50|3@0+ (1.0000000000,0.0000000000) [0.0000000000|7.0000000000] ""  HU,AMP
 SG_ HU_ToneLowSet : 44|5@0+ (1.0000000000,0.0000000000) [0.0000000000|31.0000000000] ""  HU,AMP
 SG_ HU_ToneMiddleSet : 36|5@0+ (1.0000000000,0.0000000000) [0.0000000000|31.0000000000] ""  HU,AMP
 SG_ HU_ToneHighSet : 28|5@0+ (1.0000000000,0.0000000000) [0.0000000000|31.0000000000] ""  HU,AMP
 SG_ HU_BalanceYSet : 20|5@0+ (1.0000000000,0.0000000000) [0.0000000000|31.0000000000] ""  HU,AMP
 SG_ HU_BalanceXSet : 12|5@0+ (1.0000000000,0.0000000000) [0.0000000000|31.0000000000] ""  HU,AMP
 SG_ HU_EQModeSet : 4|3@0+ (1.0000000000,0.0000000000) [0.0000000000|7.0000000000] ""  HU,AMP
 SG_ HU_SoundFileTransferStatus : 1|2@0+ (1.0000000000,0.0000000000) [0.0000000000|3.0000000000] ""  HU,AMP

BO_ 958 HU_3BE: 8 HU
 SG_ AMP_MusicPlaySetBackSignal : 17|2@0+ (1.0000000000,0.0000000000) [0.0000000000|3.0000000000] ""  AMP,HU,GW
 SG_ HU_OutWelcomeSoundFeedback : 10|3@0+ (1.0000000000,0.0000000000) [0.0000000000|7.0000000000] ""  AMP,HU
 SG_ AMP_MuteFeedback : 5|2@0+ (1.0000000000,0.0000000000) [0.0000000000|3.0000000000] ""  AMP,HU
 SG_ AMP_EQModeFeedback : 4|3@0+ (1.0000000000,0.0000000000) [0.0000000000|7.0000000000] ""  AMP,HU
 SG_ AMP_SoundFileTransferFeedback : 1|2@0+ (1.0000000000,0.0000000000) [0.0000000000|3.0000000000] ""  AMP,HU

CM_ SG_ 839 BCM_TirePresureSignalStatus  "报文转发 ";
CM_ SG_ 839 TPMS_SystemFailureWarning  "报文转发 ";
CM_ SG_ 839 TPMS_LRPressureWarning  "报文转发 ";
CM_ SG_ 839 TPMS_RRPressureWarning  "报文转发 ";
CM_ SG_ 839 TPMS_RFPressureWarning  "报文转发 ";
CM_ SG_ 839 TPMS_LFPressureWarning  "报文转发 ";
CM_ SG_ 839 TPMS_TireTemperature  "报文转发 ";
CM_ SG_ 839 TPMS_LRTyrePressure  "报文转发 ";
CM_ SG_ 839 TPMS_RRTyrePressure  "报文转发 ";
CM_ SG_ 839 TPMS_RFTyrePressure  "报文转发 ";
CM_ SG_ 839 TPMS_LFTyrePressure  "报文转发 ";
CM_ SG_ 839 TPMS_TirePosition  "报文转发 ";
CM_ SG_ 839 TPMS_LRTemperatureWarning  "报文转发 ";
CM_ SG_ 839 TPMS_RRTemperatureWarning  "报文转发 ";
CM_ SG_ 839 TPMS_RFTemperatureWarning  "报文转发 ";
CM_ SG_ 839 TPMS_LFTemperatureWarning  "报文转发 ";
CM_ SG_ 839 TPMS_SignalStatus  "报文转发 ";

CM_ SG_ 896 IP_EngineOffTime  "报文转发 ";
CM_ SG_ 896 IP_FuelLevel  "报文转发 ";
CM_ SG_ 896 IP_AvgFuelConsumption  "报文转发 ";
CM_ SG_ 896 IP_TotalOdometer  "报文转发 ";
CM_ SG_ 896 IP_AfeAfterIgnOn  "报文转发 ";

CM_ SG_ 614 PEPS_Easy_open  "报文转发 ";
CM_ SG_ 614 PEPS_KeyNumber  "报文转发 ";
CM_ SG_ 614 PEPS_PEPSFailStatus  "报文转发 ";
CM_ SG_ 614 PEPS_PowerDistributionFaultBit  "报文转发 ";
CM_ SG_ 614 PEPS_EngineStartupInhibitFb  "报文转发 ";
CM_ SG_ 614 PEPS_ImmoFeedback  "报文转发 ";
CM_ SG_ 614 PEPS_KeyAuthenticationStatus  "报文转发 ";
CM_ SG_ 614 PEPS_EngineStartupInhibitSts  "报文转发 ";
CM_ SG_ 614 PEPS_RemoteStartFeedback  "报文转发 ";
CM_ SG_ 614 PEPS_RemoteStartReq  "报文转发 ";
CM_ SG_ 614 PEPS_StartupButtonSignal  "报文转发 ";
CM_ SG_ 614 PEPS_TrunkRequestSignal  "报文转发 ";
CM_ SG_ 614 PEPS_DoorHandleButtonSignal  "报文转发 ";
CM_ SG_ 614 PEPS_PowerDistributionStatus  "报文转发 ";
CM_ SG_ 614 PEPS_StartControlsignal  "报文转发 ";
CM_ SG_ 614 PEPS_StartIndicatorSignal  "报文转发 ";
CM_ SG_ 614 PEPS_UnallowStart_ESCL_Error  "报文转发 ";
CM_ SG_ 614 PEPS_UnallowStart_ESCL_LOCK  "报文转发 ";
CM_ SG_ 614 PEPS_IMMOFailedAlarmsignal  "报文转发 ";
CM_ SG_ 614 PEPS_RemoteFailedAlarmSignal  "报文转发 ";
CM_ SG_ 614 PEPS_UnallowStartSignal_Not_PN  "报文转发 ";
CM_ SG_ 614 PEPS_KeyUndetectedAlarmSignal  "报文转发 ";
CM_ SG_ 614 PEPS_KeyInCarAlarmSignal  "报文转发 ";
CM_ SG_ 614 PEPS_UnlockModeTransitionSignal  "报文转发 ";
CM_ SG_ 614 PEPS_LuggageUnlockSignal  "报文转发 ";
CM_ SG_ 614 PEPS_SearchCarSignal  "报文转发 ";
CM_ SG_ 614 PEPS_RemoteWindowDownSignal  "报文转发 ";
CM_ SG_ 614 PEPS_RemoteWindowUpSignal  "报文转发 ";
CM_ SG_ 614 PEPS_LockSignal  "报文转发 ";
CM_ SG_ 614 PEPS_UnlockSignal  "报文转发 ";
CM_ SG_ 614 PEPS_KeyBatteryStatus  "报文转发 ";
CM_ SG_ 614 PEPS_KeyPositionStatus  "报文转发 ";

CM_ SG_ 816 AC_AutowindSet3Status  "报文转发 ";
CM_ SG_ 816 AC_AutowindSet2Status  "报文转发 ";
CM_ SG_ 816 AC_AutowindSet1Status  "报文转发 ";
CM_ SG_ 816 AC_EnvironmentalTemp  "报文转发 ";
CM_ SG_ 816 AC_EnvironmentalTempVD  "报文转发 ";
CM_ SG_ 816 AC_AC_ReqValid  "报文转发 ";
CM_ SG_ 816 AC_AC_Req  "报文转发 ";
CM_ SG_ 816 AC_FrReqWindLevel  "报文转发 ";
CM_ SG_ 816 AC_SystemFailureFlag  "报文转发 ";
CM_ SG_ 816 AC_RearDefrosterSwitch  "报文转发 ";

CM_ SG_ 648 BCM_DriverDoorStatus  "GW报文转发 ";
CM_ SG_ 648 BCM_BuzzerWarningMode  "报文转发 ";
CM_ SG_ 648 BCM_SystemFailureFlag  "报文转发 ";
CM_ SG_ 648 BCM_LatchOverheatProtect  "报文转发 ";
CM_ SG_ 648 BCM_FollowMeTurnon  "报文转发 ";
CM_ SG_ 648 BCM_ReversePosition  "报文转发 ";
CM_ SG_ 648 BCM_TurnLightSwitchSts  "报文转发 ";
CM_ SG_ 648 BCM_KeyAlarmStatus  "报文转发 ";
CM_ SG_ 648 BCM_Statusrainsensor  "报文转发 ";
CM_ SG_ 648 BCM_KeyInSignal  "报文转发 ";
CM_ SG_ 648 BCM_DriverDoorLockStatus  "报文转发 ";
CM_ SG_ 648 BCM_PowerStatusFeedback  "报文转发 ";
CM_ SG_ 648 BCM_RearWiperStatus  "报文转发 ";
CM_ SG_ 648 BCM_Statuslowbeam  "报文转发 ";
CM_ SG_ 648 BCM_FrontWiperStatus  "报文转发 ";
CM_ SG_ 648 BCM_RearDefrosterstatus  "报文转发 ";
CM_ SG_ 648 BCM_emergencylightstatus  "报文转发 ";
CM_ SG_ 648 BCM_SunroofMotor  "报文转发 ";
CM_ SG_ 648 BCM_RightRearWinMotor  "报文转发 ";
CM_ SG_ 648 BCM_LeftRearWinMotor  "报文转发 ";
CM_ SG_ 648 BCM_PassengerWinMotor  "报文转发 ";
CM_ SG_ 648 BCM_DriverWinMotor  "报文转发 ";
CM_ SG_ 648 BCM_AutoHeadlightSts  "报文转发 ";
CM_ SG_ 648 BCM_SunroofStatus  "报文转发 ";
CM_ SG_ 648 BCM_HoodStatus  "报文转发 ";
CM_ SG_ 648 BCM_TrunkDoorStatus  "报文转发 ";
CM_ SG_ 648 BCM_RightRearDoorStatus  "报文转发 ";
CM_ SG_ 648 BCM_LeftRearDoorStatus  "报文转发 ";
CM_ SG_ 648 BCM_PassengerDoorStatus  "报文转发 ";
CM_ SG_ 648 BCM_DriverDoorStatus  "报文转发 ";
CM_ SG_ 648 BCM_FrontWashStatus  "报文转发 ";
CM_ SG_ 648 BCM_PositionLampStatus  "报文转发 ";
CM_ SG_ 648 BCM_TurnIndicatorRight  "报文转发 ";
CM_ SG_ 648 BCM_TurnIndicatorLeft  "报文转发 ";
CM_ SG_ 648 BCM_RearFoglampStatus  "报文转发 ";
CM_ SG_ 648 BCM_FrontFoglampStatus  "报文转发 ";
CM_ SG_ 648 BCM_HighBeamStatus  "报文转发 ";
CM_ SG_ 648 BCM_LowBeamStatus  "报文转发 ";

CM_ SG_ 841 BCM_CarMode  "报文转发 ";
CM_ SG_ 841 BCM_PMSErrorFlag  "报文转发 ";
CM_ SG_ 841 BCM_LowPowerWarning  "报文转发 ";
CM_ SG_ 841 BCM_PMSLevel  "报文转发 ";

CM_ SG_ 640 IP_DisAfterIgnOn  "报文转发 ";
CM_ SG_ 640 IP_FuelLevelPercent  "报文转发 ";
CM_ SG_ 640 IP_MaintainReset  "报文转发 ";
CM_ SG_ 640 IP_FuelLeftover  "报文转发 ";
CM_ SG_ 640 IP_FuelLow  "报文转发 ";

CM_ SG_ 608 IP_DTE  "报文转发 ";

CM_ SG_ 901 IP_RearSeatbeltWarningEnableFB  "GW报文转发 ";
CM_ SG_ 901 IP_WarningVolumeSettingFB  "GW报文转发 ";

CM_ BO_ 1288  "ICAR 2.0杂合车临时使用 ";
CM_ SG_ 1288 HU_IMS_LegalDriverFeedback  " ";
CM_ SG_ 1288 HU_IMS_DrowsinessStatus  " ";
CM_ SG_ 1288 HU_IMS_DistractionStatus  " ";
CM_ SG_ 1288 HU_IMS_DriverID  " ";

CM_ BO_ 1537  "详细描述请见《功能定义文件》 ";

CM_ SG_ 760 HU_PACModeSelect  "带全景功能的车型配置不发0x1 ";

CM_ BO_ 1536  "详细描述请见《功能定义文件》 ";

CM_ BO_ 1535  "详细描述请见《功能定义文件》 ";
CM_ SG_ 1535 BCM_OutWelcomeSoundFeedback  " ";

CM_ BO_ 1520  "详细描述请见《功能定义文件》 ";
CM_ SG_ 1520 LCM_AtmoLightAutoAdjustSts  "GW报文转发 ";
CM_ SG_ 1520 LCM_AtmoLightAAEnableSts  "报文转发 ";
CM_ SG_ 1520 LCM_DRLSetFB  "报文转发 ";
CM_ SG_ 1520 LCM_Dimmerlevel  "报文转发 ";
CM_ SG_ 1520 LCM_AmbientLightColorSetStas  "报文转发 ";
CM_ SG_ 1520 LCM_AmbientLightBrightSetStas  "报文转发 ";

CM_ SG_ 614 PEPS_Easy_open  "报文转发 ";
CM_ SG_ 614 PEPS_KeyNumber  "报文转发 ";
CM_ SG_ 614 PEPS_PEPSFailStatus  "报文转发 ";
CM_ SG_ 614 PEPS_PowerDistributionFaultBit  "报文转发 ";
CM_ SG_ 614 PEPS_EngineStartupInhibitFb  "报文转发 ";
CM_ SG_ 614 PEPS_ImmoFeedback  "报文转发 ";
CM_ SG_ 614 PEPS_KeyAuthenticationStatus  "报文转发 ";
CM_ SG_ 614 PEPS_EngineStartupInhibitSts  "报文转发 ";
CM_ SG_ 614 PEPS_RemoteStartFeedback  "报文转发 ";
CM_ SG_ 614 PEPS_RemoteStartReq  "报文转发 ";
CM_ SG_ 614 PEPS_StartupButtonSignal  "报文转发 ";
CM_ SG_ 614 PEPS_TrunkRequestSignal  "报文转发 ";
CM_ SG_ 614 PEPS_DoorHandleButtonSignal  "报文转发 ";
CM_ SG_ 614 PEPS_PowerDistributionStatus  "报文转发 ";
CM_ SG_ 614 PEPS_StartControlsignal  "报文转发 ";
CM_ SG_ 614 PEPS_StartIndicatorSignal  "报文转发 ";
CM_ SG_ 614 PEPS_UnallowStart_ESCL_Error  "报文转发 ";
CM_ SG_ 614 PEPS_UnallowStart_ESCL_LOCK  "报文转发 ";
CM_ SG_ 614 PEPS_IMMOFailedAlarmsignal  "报文转发 ";
CM_ SG_ 614 PEPS_RemoteFailedAlarmSignal  "报文转发 ";
CM_ SG_ 614 PEPS_UnallowStartSignal_Not_PN  "报文转发 ";
CM_ SG_ 614 PEPS_KeyUndetectedAlarmSignal  "报文转发 ";
CM_ SG_ 614 PEPS_KeyInCarAlarmSignal  "报文转发 ";
CM_ SG_ 614 PEPS_UnlockModeTransitionSignal  "报文转发 ";
CM_ SG_ 614 PEPS_LuggageUnlockSignal  "报文转发 ";
CM_ SG_ 614 PEPS_SearchCarSignal  "报文转发 ";
CM_ SG_ 614 PEPS_RemoteWindowDownSignal  "报文转发 ";
CM_ SG_ 614 PEPS_RemoteWindowUpSignal  "报文转发 ";
CM_ SG_ 614 PEPS_LockSignal  "报文转发 ";
CM_ SG_ 614 PEPS_UnlockSignal  "报文转发 ";
CM_ SG_ 614 PEPS_KeyBatteryStatus  "报文转发 ";
CM_ SG_ 614 PEPS_KeyPositionStatus  "报文转发 ";

CM_ SG_ 816 AC_AutowindSet3Status  "报文转发 ";
CM_ SG_ 816 AC_AutowindSet2Status  "报文转发 ";
CM_ SG_ 816 AC_AutowindSet1Status  "报文转发 ";
CM_ SG_ 816 AC_EnvironmentalTemp  "报文转发 ";
CM_ SG_ 816 AC_EnvironmentalTempVD  "报文转发 ";
CM_ SG_ 816 AC_AC_ReqValid  "报文转发 ";
CM_ SG_ 816 AC_AC_Req  "报文转发 ";
CM_ SG_ 816 AC_FrReqWindLevel  "报文转发 ";
CM_ SG_ 816 AC_SystemFailureFlag  "报文转发 ";
CM_ SG_ 816 AC_RearDefrosterSwitch  "报文转发 ";

CM_ SG_ 832 AC_ACOnOff  "报文转发 ";
CM_ SG_ 832 AC_EnvironmentalTemp_RAW  "报文转发 ";
CM_ SG_ 832 AC_PlasmaSt  "报文转发 ";
CM_ SG_ 832 AC_AQSSt  "报文转发 ";
CM_ SG_ 832 AC_RecycleType  "报文转发 ";
CM_ SG_ 832 AC_ClimateDisplayReq  "报文转发 ";
CM_ SG_ 832 AC_PaReqTemp  "报文转发 ";
CM_ SG_ 832 AC_DriverReqTemp  "报文转发 ";
CM_ SG_ 832 AC_DriverReqTempModel  "报文转发 ";
CM_ SG_ 832 AC_AutoWorkStatus  "报文转发 ";
CM_ SG_ 832 AC_FrAutoSts  "报文转发 ";
CM_ SG_ 832 AC_ACSt  "报文转发 ";
CM_ SG_ 832 AC_FrBlowType  "报文转发 ";

CM_ SG_ 896 IP_EngineOffTime  "报文转发 ";
CM_ SG_ 896 IP_FuelLevel  "报文转发 ";
CM_ SG_ 896 IP_AvgFuelConsumption  "报文转发 ";
CM_ SG_ 896 IP_TotalOdometer  "报文转发 ";
CM_ SG_ 896 IP_AfeAfterIgnOn  "报文转发 ";

CM_ SG_ 688 EMS_SartPrompt  "MT车型发送 ";

CM_ SG_ 810 EMS_RemindGear  "MT车型发送，AT车型默认发0x0 ";

CM_ SG_ 839 BCM_TirePresureSignalStatus  "报文转发 ";
CM_ SG_ 839 TPMS_SystemFailureWarning  "报文转发 ";
CM_ SG_ 839 TPMS_LRPressureWarning  "报文转发 ";
CM_ SG_ 839 TPMS_RRPressureWarning  "报文转发 ";
CM_ SG_ 839 TPMS_RFPressureWarning  "报文转发 ";
CM_ SG_ 839 TPMS_LFPressureWarning  "报文转发 ";
CM_ SG_ 839 TPMS_TireTemperature  "报文转发 ";
CM_ SG_ 839 TPMS_LRTyrePressure  "报文转发 ";
CM_ SG_ 839 TPMS_RRTyrePressure  "报文转发 ";
CM_ SG_ 839 TPMS_RFTyrePressure  "报文转发 ";
CM_ SG_ 839 TPMS_LFTyrePressure  "报文转发 ";
CM_ SG_ 839 TPMS_TirePosition  "报文转发 ";
CM_ SG_ 839 TPMS_LRTemperatureWarning  "报文转发 ";
CM_ SG_ 839 TPMS_RRTemperatureWarning  "报文转发 ";
CM_ SG_ 839 TPMS_RFTemperatureWarning  "报文转发 ";
CM_ SG_ 839 TPMS_LFTemperatureWarning  "报文转发 ";
CM_ SG_ 839 TPMS_SignalStatus  "报文转发 ";

CM_ SG_ 900 BCM_LightSensor  "报文转发 ";
CM_ SG_ 900 BCM_LockSignal  "报文转发 ";
CM_ SG_ 900 BCM_UnlockSignal  "报文转发 ";
CM_ SG_ 900 BCM_RemoteWindowDownSignal  "报文转发 ";
CM_ SG_ 900 BCM_RmoteUnLockFeedback  "报文转发 ";
CM_ SG_ 900 BCM_RmoteLockeFeedback  "报文转发 ";
CM_ SG_ 900 BCM_CarRemindFeedback  "报文转发 ";
CM_ SG_ 900 BCM_RightRearWindowStatus  "Relative position of window in percent
0表示全关、200表示全开
报文转发 ";
CM_ SG_ 900 BCM_LeftRearWindowStatus  "Relative position of window in percent
0表示全关、200表示全开
报文转发 ";
CM_ SG_ 900 BCM_PassengerWindowStatus  "Relative position of window in percent
0表示全关、200表示全开
报文转发 ";
CM_ SG_ 900 BCM_DriverWindowStatus  "Relative position of window in percent
0表示全关、200表示全开
报文转发 ";

CM_ BO_ 1298  "详细描述请见《功能定义文件》 ";
CM_ SG_ 1298 PEPS_VIN  "报文转发 ";
CM_ SG_ 1298 PEPS_VINFrameNumber  "报文转发 ";

CM_ SG_ 630 ESCL_SteeringLockError  "报文转发 ";
CM_ SG_ 630 ESCL_SteeringLockStuck  "报文转发 ";
CM_ SG_ 630 ESCL_SteeringLockWait  "报文转发 ";
CM_ SG_ 630 ESCL_SteeringLockStatusS301  "报文转发 ";
CM_ SG_ 630 ESCL_SteeringLockStatusReserve  "报文转发 ";

CM_ SG_ 728 LAS_CheckSum  "报文转发 ";
CM_ SG_ 728 LAS_AliveCounter  "报文转发 ";
CM_ SG_ 728 LAS_HMALightDistribution  "报文转发 ";
CM_ SG_ 728 LAS_HMAStatus  "报文转发 ";
CM_ SG_ 728 LAS_SLASpdLimitUnits  "报文转发 ";
CM_ SG_ 728 LAS_SLASpdLimit  "报文转发 ";
CM_ SG_ 728 LAS_SLAState  "报文转发 ";
CM_ SG_ 728 LAS_LKSStatus  "报文转发 ";
CM_ SG_ 728 LAS_CalibrationStatus  "报文转发 ";
CM_ SG_ 728 LAS_LDWReminder  "报文转发 ";
CM_ SG_ 728 LAS_LASFailure  "报文转发 ";
CM_ SG_ 728 LAS_SteeringTorqueReq  "报文转发 ";
CM_ SG_ 728 LAS_TakeoverReq  "报文转发 ";
CM_ SG_ 728 LAS_LDWStatus  "报文转发 ";
CM_ SG_ 728 LDW_VibrationWarning  "报文转发 ";

CM_ SG_ 736 RRS_SystemFailureFlag  "报文转发 ";
CM_ SG_ 736 RRS_WarningFrequency  "报文转发 ";
CM_ SG_ 736 RRS_WarningType  "报文转发 ";
CM_ SG_ 736 RRS_SwitchIndicatorError  "报文转发 ";
CM_ SG_ 736 RRS_SpkErrFlag  "报文转发 ";
CM_ SG_ 736 RRS_ctrlModulErrFlag  "报文转发 ";
CM_ SG_ 736 RRS_BattVoltErrFlag  "报文转发 ";
CM_ SG_ 736 RRS_RFMSnsErrFlag  "报文转发 ";
CM_ SG_ 736 RRS_LFMSnsErrFlag  "报文转发 ";
CM_ SG_ 736 RRS_RRMidSnsErrFlag  "报文转发 ";
CM_ SG_ 736 RRS_LRMidSnsErrFlag  "报文转发 ";
CM_ SG_ 736 RRS_RRCSnsErrFlag  "报文转发 ";
CM_ SG_ 736 RRS_LRCSnsErrFlag  "报文转发 ";
CM_ SG_ 736 RRS_RFCSnsErrFlag  "报文转发 ";
CM_ SG_ 736 RRS_LFCSnsErrFlag  "报文转发 ";
CM_ SG_ 736 RRS_RFMDistance  "报文转发 ";
CM_ SG_ 736 RRS_LFMDistance  "报文转发 ";
CM_ SG_ 736 RRS_LFCDistance  "报文转发 ";
CM_ SG_ 736 RRS_RFCDistance  "报文转发 ";
CM_ SG_ 736 RRS_LRCDistance  "报文转发 ";
CM_ SG_ 736 RRS_RRCDistance  "报文转发 ";
CM_ SG_ 736 RRS_LRMDistance  "报文转发 ";
CM_ SG_ 736 RRS_RRMDistance  "报文转发 ";

CM_ SG_ 608 IP_DTE  "报文转发 ";

CM_ BO_ 1300  "详细描述请见《功能定义文件》 ";

CM_ BO_ 1301  "详细描述请见《功能定义文件》 ";

CM_ SG_ 729 LAS_CheckSum_idxxE  "报文转发 ";
CM_ SG_ 729 LAS_RollingCounter_idxxE  "报文转发 ";
CM_ SG_ 729 LDW_VoiceWarning  "报文转发 ";
CM_ SG_ 729 LAS_OverspeedSoundWarning  "报文转发 ";
CM_ SG_ 729 LAS_OverspeedVisualWarning  "报文转发 ";
CM_ SG_ 729 LAS_OverspeedWarningOffset  "报文转发 ";
CM_ SG_ 729 LAS_OverspeedWarningEnableStatus  "报文转发 ";
CM_ SG_ 729 LAS_RLaneMarkerType  "报文转发 ";
CM_ SG_ 729 LAS_LLaneMarkerType  "报文转发 ";
CM_ SG_ 729 LAS_HostLaneRightStatus  "报文转发 ";
CM_ SG_ 729 LAS_HostLaneLeftStatus  "报文转发 ";
CM_ SG_ 729 LAS_OverspeedSoundWarnEnaSts  "报文转发 ";
CM_ SG_ 729 LAS_LDWShakeLevStatus  "报文转发 ";
CM_ SG_ 729 LAS_LASWarningModeSelectStas  "报文转发 ";
CM_ SG_ 729 LAS_SLASwitchStatus  "报文转发 ";
CM_ SG_ 729 LAS_HMAEnableStatus  "报文转发 ";
CM_ SG_ 729 LAS_LASModeSelectionStatus  "报文转发 ";
CM_ SG_ 729 LAS_LdwSensitivityStatus  "报文转发 ";

CM_ SG_ 862 ACC_CheckSum_id35E  "报文转发 ";
CM_ SG_ 862 ACC_RollingCounter_id35E  "报文转发 ";
CM_ SG_ 862 ACC_CruiseControlSetStatus  "报文转发 ";
CM_ SG_ 862 ACC_DistanceAlertEnableStatus  "报文转发 ";
CM_ SG_ 862 ACC_ACCObjEnableStatus  "报文转发 ";
CM_ SG_ 862 ACC_FCWSensitivityStatus  "报文转发 ";
CM_ SG_ 862 ACC_AutoBrakeEnableStatus  "报文转发 ";
CM_ SG_ 862 ACC_FCWEnableStatus  "报文转发 ";
CM_ SG_ 862 ACC_ACCFailInfo  "报文转发 ";
CM_ SG_ 862 ACC_TakeOverReq  "报文转发 ";
CM_ SG_ 862 ACC_ObjValid  "报文转发 ";
CM_ SG_ 862 ACC_TimeGapSet  "报文转发 ";
CM_ SG_ 862 ACC_DistanceTarObj  "报文转发 ";
CM_ SG_ 862 ACC_SetSpeedDis  "报文转发 ";

CM_ SG_ 850 DSM_DSMMemoryPosition  "报文转发 ";
CM_ SG_ 850 DSM_MirrorSetStatus  "报文转发 ";
CM_ SG_ 850 DSM_KeyMomerySts  "报文转发 ";
CM_ SG_ 850 DSM_MemoryAlarm  "报文转发 ";
CM_ SG_ 850 DSM_MemoryPosition  "报文转发 ";
CM_ SG_ 850 DSM_EasyEntrySts  "报文转发 ";
CM_ SG_ 850 DSM_GetMemoryReq  "报文转发 ";
CM_ SG_ 850 DSM_SetMemoryReq  "报文转发 ";

CM_ SG_ 808 LCM_LASSwitch  "报文转发 ";

CM_ SG_ 737 RFC_Sector_Dist  "报文转发 ";
CM_ SG_ 737 LFC_Sector_Dist  "报文转发 ";
CM_ SG_ 737 RRC_Sector_Dist  "报文转发 ";
CM_ SG_ 737 LRC_Sector_Dist  "报文转发 ";
CM_ SG_ 737 RRM_Sector_Dist  "报文转发 ";
CM_ SG_ 737 LRM_Sector_Dist  "报文转发 ";

CM_ BO_ 1717  "AVM发给Tester（报文转发） ";

CM_ BO_ 1299  "详细描述请见《功能定义文件》 ";

CM_ SG_ 610 PEPS_WelcomeLightStaus  "报文转发 ";

CM_ SG_ 901 IP_RearSeatbeltWarningEnableFB  "GW报文转发 ";
CM_ SG_ 901 IP_WarningVolumeSettingFB  "GW报文转发 ";

CM_ SG_ 1338 HU_WelcomeLightSetStatus  "音乐灯光秀和律动迎宾都在用，用于设置模式 ";

CM_ SG_ 957 HU_OutWelcomeSoundSet  "告诉AMP和BCM播放什么音乐。BCM根据音乐执行编排好的灯光。功能激活时，AMP播放相应音乐。 ";
CM_ SG_ 957 HU_ToneLowSet  " ";
CM_ SG_ 957 HU_ToneMiddleSet  " ";
CM_ SG_ 957 HU_ToneHighSet  " ";
CM_ SG_ 957 HU_BalanceYSet  " ";
CM_ SG_ 957 HU_BalanceXSet  " ";
CM_ SG_ 957 HU_EQModeSet  " ";
CM_ SG_ 957 HU_SoundFileTransferStatus  "传输68种报警音和迎宾声音 ";

CM_ SG_ 958 AMP_MusicPlaySetBackSignal  " ";
CM_ SG_ 958 HU_OutWelcomeSoundFeedback  " ";
CM_ SG_ 958 AMP_MuteFeedback  " ";
CM_ SG_ 958 AMP_EQModeFeedback  " ";
CM_ SG_ 958 AMP_SoundFileTransferFeedback  " ";

BA_DEF_ SG_  "GenSigStartValue" INT 0 0;
BA_DEF_ SG_  "GenSigInvalidValue" STRING  ;
BA_DEF_ SG_  "GenSigCycleTime" INT 0 0;
BA_DEF_ SG_  "GenSigSendType" ENUM  "Cyclic","OnWrite","OnWriteWithRepetition","OnChange","OnChangeWithRepetition","IfActive","IfActiveWithRepetition","NoSigSendType","NotUsed","NotUsed","NotUsed","NotUsed","NotUsed";
BA_DEF_  "Baudrate" INT 0 1000000;
BA_DEF_  "BusType" STRING ;
BA_DEF_  "NmType" STRING ;
BA_DEF_  "Manufacturer" STRING ;
BA_DEF_  "VersionYear" INT 2009 2210;
BA_DEF_  "VersionNumber" INT 0 65535;
BA_DEF_  "VersionMonth" INT 0 18;
BA_DEF_  "VersionDay" INT 0 49;
BA_DEF_ BU_  "NodeLayerModules" STRING ;
BA_DEF_ BU_  "ILUsed" ENUM  "No","Yes";
BA_DEF_  "GenNWMTalkNM" STRING ;
BA_DEF_  "GenNWMGotoMode_BusSleep" STRING ;
BA_DEF_  "GenNWMGotoMode_Awake" STRING ;
BA_DEF_  "GenNWMApCanWakeUp" STRING ;
BA_DEF_  "GenNWMApCanSleep" STRING ;
BA_DEF_  "GenNWMApCanOn" STRING ;
BA_DEF_  "GenNWMApCanOff" STRING ;
BA_DEF_  "GenNWMApCanNormal" STRING ;
BA_DEF_  "GenNWMApBusSleep" STRING ;
BA_DEF_ BO_  "GenMsgSendType" ENUM  "Cyclic","Event","NotUsed","NotUsed","NotUsed","Cyclic","NotUsed","IfActive","NoMsgSendType","NotUsed";
BA_DEF_ BO_  "GenMsgILSupport" ENUM  "No","Yes";
BA_DEF_ BO_  "GenMsgCycleTime" INT 0 65535;
BA_DEF_DEF_  "GenSigStartValue" 0;
BA_DEF_DEF_  "GenSigInvalidValue" "/";
BA_DEF_DEF_  "GenSigCycleTime" 0;
BA_DEF_DEF_  "GenSigSendType" "Cyclic";
BA_DEF_DEF_  "Baudrate" 500000;
BA_DEF_DEF_  "BusType" "";
BA_DEF_DEF_  "NmType" "";
BA_DEF_DEF_  "Manufacturer" "CHANA";
BA_DEF_DEF_  "VersionYear" 2010;
BA_DEF_DEF_  "VersionNumber" 0;
BA_DEF_DEF_  "VersionMonth" 11;
BA_DEF_DEF_  "VersionDay" 0;
BA_DEF_DEF_  "NodeLayerModules" "OSEKNM01.dll,CANoeILNLVector.dll";
BA_DEF_DEF_  "ILUsed" "Yes";
BA_DEF_DEF_  "GenNWMTalkNM" "TalkNM()";
BA_DEF_DEF_  "GenNWMGotoMode_BusSleep" "GotoMode_BusSleep()";
BA_DEF_DEF_  "GenNWMGotoMode_Awake" "GotoMode_Awake()";
BA_DEF_DEF_  "GenNWMApCanWakeUp" "apCanWakeUp()";
BA_DEF_DEF_  "GenNWMApCanSleep" "apCanSleep()";
BA_DEF_DEF_  "GenNWMApCanOn" "apCanOn()";
BA_DEF_DEF_  "GenNWMApCanOff" "apCanOff()";
BA_DEF_DEF_  "GenNWMApCanNormal" "apCanNormal()";
BA_DEF_DEF_  "GenNWMApBusSleep" "apBusSleep()";
BA_DEF_DEF_  "GenMsgSendType" "NoMsgSendType";
BA_DEF_DEF_  "GenMsgILSupport" "Yes";
BA_DEF_DEF_  "GenMsgCycleTime" 0;
BA_ "VersionYear" 2018;
BA_ "VersionNumber" 11;
BA_ "VersionMonth" 06;
BA_ "VersionDay" 26;
BA_ "BusType" "CAN";
BA_ "NmType" "OSEK";
BA_ "GenMsgCycleTime" BO_ 839 500;
BA_ "GenMsgSendType" BO_ 839 0;
BA_ "GenMsgSendType" BO_ 1025 1;
BA_ "GenMsgCycleTime" BO_ 896 500;
BA_ "GenMsgSendType" BO_ 896 0;
BA_ "GenMsgCycleTime" BO_ 614 40;
BA_ "GenMsgSendType" BO_ 614 0;
BA_ "GenMsgCycleTime" BO_ 816 100;
BA_ "GenMsgSendType" BO_ 816 0;
BA_ "GenMsgCycleTime" BO_ 648 40;
BA_ "GenMsgSendType" BO_ 648 0;
BA_ "GenMsgCycleTime" BO_ 841 500;
BA_ "GenMsgSendType" BO_ 841 0;
BA_ "GenMsgCycleTime" BO_ 640 50;
BA_ "GenMsgSendType" BO_ 640 0;
BA_ "GenMsgCycleTime" BO_ 608 40;
BA_ "GenMsgSendType" BO_ 608 0;
BA_ "GenMsgCycleTime" BO_ 901 50;
BA_ "GenMsgSendType" BO_ 901 0;
BA_ "GenMsgCycleTime" BO_ 1288 100;
BA_ "GenMsgSendType" BO_ 1288 0;
BA_ "GenMsgSendType" BO_ 1537 1;
BA_ "GenMsgCycleTime" BO_ 760 100;
BA_ "GenMsgSendType" BO_ 760 0;
BA_ "GenMsgCycleTime" BO_ 761 100;
BA_ "GenMsgSendType" BO_ 761 0;
BA_ "GenMsgCycleTime" BO_ 762 100;
BA_ "GenMsgSendType" BO_ 762 0;
BA_ "GenMsgSendType" BO_ 1041 1;
BA_ "GenMsgCycleTime" BO_ 1280 1000;
BA_ "GenMsgSendType" BO_ 1280 0;
BA_ "GenMsgCycleTime" BO_ 1281 1000;
BA_ "GenMsgSendType" BO_ 1281 0;
BA_ "GenMsgSendType" BO_ 1536 1;
BA_ "GenMsgCycleTime" BO_ 1408 1000;
BA_ "GenMsgSendType" BO_ 1408 0;
BA_ "GenMsgSendType" BO_ 1031 1;
BA_ "GenMsgCycleTime" BO_ 662 100;
BA_ "GenMsgSendType" BO_ 662 0;
BA_ "GenMsgSendType" BO_ 1365 1;
BA_ "GenMsgCycleTime" BO_ 992 50;
BA_ "GenMsgSendType" BO_ 992 0;
BA_ "GenMsgCycleTime" BO_ 1535 100;
BA_ "GenMsgSendType" BO_ 1535 0;
BA_ "GenMsgCycleTime" BO_ 1520 100;
BA_ "GenMsgSendType" BO_ 1520 0;
BA_ "GenMsgCycleTime" BO_ 614 40;
BA_ "GenMsgSendType" BO_ 614 0;
BA_ "GenMsgCycleTime" BO_ 816 100;
BA_ "GenMsgSendType" BO_ 816 0;
BA_ "GenMsgCycleTime" BO_ 832 100;
BA_ "GenMsgSendType" BO_ 832 0;
BA_ "GenMsgCycleTime" BO_ 896 500;
BA_ "GenMsgSendType" BO_ 896 0;
BA_ "GenMsgCycleTime" BO_ 688 50;
BA_ "GenMsgSendType" BO_ 688 0;
BA_ "GenMsgCycleTime" BO_ 800 100;
BA_ "GenMsgSendType" BO_ 800 0;
BA_ "GenMsgCycleTime" BO_ 806 100;
BA_ "GenMsgSendType" BO_ 806 0;
BA_ "GenMsgCycleTime" BO_ 810 100;
BA_ "GenMsgSendType" BO_ 810 0;
BA_ "GenMsgCycleTime" BO_ 883 300;
BA_ "GenMsgSendType" BO_ 883 0;
BA_ "GenMsgCycleTime" BO_ 839 500;
BA_ "GenMsgSendType" BO_ 839 0;
BA_ "GenMsgCycleTime" BO_ 886 300;
BA_ "GenMsgSendType" BO_ 886 0;
BA_ "GenMsgCycleTime" BO_ 900 200;
BA_ "GenMsgSendType" BO_ 900 0;
BA_ "GenMsgSendType" BO_ 1298 1;
BA_ "GenMsgCycleTime" BO_ 630 40;
BA_ "GenMsgSendType" BO_ 630 0;
BA_ "GenMsgCycleTime" BO_ 728 20;
BA_ "GenMsgSendType" BO_ 728 0;
BA_ "GenMsgCycleTime" BO_ 736 100;
BA_ "GenMsgSendType" BO_ 736 0;
BA_ "GenMsgCycleTime" BO_ 608 40;
BA_ "GenMsgSendType" BO_ 608 0;
BA_ "GenMsgSendType" BO_ 1300 1;
BA_ "GenMsgSendType" BO_ 1301 1;
BA_ "GenMsgCycleTime" BO_ 729 100;
BA_ "GenMsgSendType" BO_ 729 0;
BA_ "GenMsgCycleTime" BO_ 862 100;
BA_ "GenMsgSendType" BO_ 862 0;
BA_ "GenMsgCycleTime" BO_ 992 200;
BA_ "GenMsgSendType" BO_ 992 0;
BA_ "GenMsgCycleTime" BO_ 850 100;
BA_ "GenMsgSendType" BO_ 850 0;
BA_ "GenMsgCycleTime" BO_ 890 200;
BA_ "GenMsgSendType" BO_ 890 0;
BA_ "GenMsgCycleTime" BO_ 1306 100;
BA_ "GenMsgSendType" BO_ 1306 0;
BA_ "GenMsgCycleTime" BO_ 808 200;
BA_ "GenMsgSendType" BO_ 808 0;
BA_ "GenMsgCycleTime" BO_ 737 100;
BA_ "GenMsgSendType" BO_ 737 0;
BA_ "GenMsgSendType" BO_ 1043 1;
BA_ "GenMsgCycleTime" BO_ 992 50;
BA_ "GenMsgSendType" BO_ 992 0;
BA_ "GenMsgSendType" BO_ 1717 1;
BA_ "GenMsgCycleTime" BO_ 1299 100;
BA_ "GenMsgSendType" BO_ 1299 0;
BA_ "GenMsgCycleTime" BO_ 610 40;
BA_ "GenMsgSendType" BO_ 610 0;
BA_ "GenMsgSendType" BO_ 1319 1;
BA_ "GenMsgCycleTime" BO_ 901 50;
BA_ "GenMsgSendType" BO_ 901 0;
BA_ "GenMsgSendType" BO_ 1338 1;
BA_ "GenMsgCycleTime" BO_ 957 100;
BA_ "GenMsgSendType" BO_ 957 0;
BA_ "GenMsgCycleTime" BO_ 958 100;
BA_ "GenMsgSendType" BO_ 958 0;
BA_ "GenSigCycleTime" SG_ 839 BCM_TirePresureSignalStatus 500;
BA_ "GenSigStartValue" SG_ 839 BCM_TirePresureSignalStatus 1.000000;
BA_ "GenSigInvalidValue" SG_ 839 BCM_TirePresureSignalStatus "NA";
BA_ "GenSigCycleTime" SG_ 839 TPMS_SystemFailureWarning 500;
BA_ "GenSigInvalidValue" SG_ 839 TPMS_SystemFailureWarning "NA";
BA_ "GenSigCycleTime" SG_ 839 TPMS_LRPressureWarning 500;
BA_ "GenSigInvalidValue" SG_ 839 TPMS_LRPressureWarning "NA";
BA_ "GenSigCycleTime" SG_ 839 TPMS_RRPressureWarning 500;
BA_ "GenSigInvalidValue" SG_ 839 TPMS_RRPressureWarning "NA";
BA_ "GenSigCycleTime" SG_ 839 TPMS_RFPressureWarning 500;
BA_ "GenSigInvalidValue" SG_ 839 TPMS_RFPressureWarning "NA";
BA_ "GenSigCycleTime" SG_ 839 TPMS_LFPressureWarning 500;
BA_ "GenSigInvalidValue" SG_ 839 TPMS_LFPressureWarning "NA";
BA_ "GenSigCycleTime" SG_ 839 TPMS_TireTemperature 500;
BA_ "GenSigStartValue" SG_ 839 TPMS_TireTemperature 40.000000;
BA_ "GenSigInvalidValue" SG_ 839 TPMS_TireTemperature "255";
BA_ "GenSigCycleTime" SG_ 839 TPMS_LRTyrePressure 500;
BA_ "GenSigInvalidValue" SG_ 839 TPMS_LRTyrePressure "255";
BA_ "GenSigCycleTime" SG_ 839 TPMS_RRTyrePressure 500;
BA_ "GenSigInvalidValue" SG_ 839 TPMS_RRTyrePressure "255";
BA_ "GenSigCycleTime" SG_ 839 TPMS_RFTyrePressure 500;
BA_ "GenSigInvalidValue" SG_ 839 TPMS_RFTyrePressure "255";
BA_ "GenSigCycleTime" SG_ 839 TPMS_LFTyrePressure 500;
BA_ "GenSigInvalidValue" SG_ 839 TPMS_LFTyrePressure "255";
BA_ "GenSigCycleTime" SG_ 839 TPMS_TirePosition 500;
BA_ "GenSigInvalidValue" SG_ 839 TPMS_TirePosition "NA";
BA_ "GenSigCycleTime" SG_ 839 TPMS_LRTemperatureWarning 500;
BA_ "GenSigInvalidValue" SG_ 839 TPMS_LRTemperatureWarning "NA";
BA_ "GenSigCycleTime" SG_ 839 TPMS_RRTemperatureWarning 500;
BA_ "GenSigInvalidValue" SG_ 839 TPMS_RRTemperatureWarning "NA";
BA_ "GenSigCycleTime" SG_ 839 TPMS_RFTemperatureWarning 500;
BA_ "GenSigInvalidValue" SG_ 839 TPMS_RFTemperatureWarning "NA";
BA_ "GenSigCycleTime" SG_ 839 TPMS_LFTemperatureWarning 500;
BA_ "GenSigInvalidValue" SG_ 839 TPMS_LFTemperatureWarning "NA";
BA_ "GenSigCycleTime" SG_ 839 TPMS_SignalStatus 500;
BA_ "GenSigStartValue" SG_ 839 TPMS_SignalStatus 1.000000;
BA_ "GenSigInvalidValue" SG_ 839 TPMS_SignalStatus "NA";
BA_ "GenSigCycleTime" SG_ 839 BCM_TirePresureSignalStatus 500;
BA_ "GenSigStartValue" SG_ 839 BCM_TirePresureSignalStatus 1.000000;
BA_ "GenSigInvalidValue" SG_ 839 BCM_TirePresureSignalStatus "NA";

BA_ "GenSigCycleTime" SG_ 896 IP_EngineOffTime 500;
BA_ "GenSigInvalidValue" SG_ 896 IP_EngineOffTime "65535";
BA_ "GenSigCycleTime" SG_ 896 IP_FuelLevel 500;
BA_ "GenSigInvalidValue" SG_ 896 IP_FuelLevel "NA";
BA_ "GenSigCycleTime" SG_ 896 IP_AvgFuelConsumption 500;
BA_ "GenSigInvalidValue" SG_ 896 IP_AvgFuelConsumption "255";
BA_ "GenSigCycleTime" SG_ 896 IP_TotalOdometer 500;
BA_ "GenSigInvalidValue" SG_ 896 IP_TotalOdometer "16777215";
BA_ "GenSigCycleTime" SG_ 896 IP_AfeAfterIgnOn 500;
BA_ "GenSigInvalidValue" SG_ 896 IP_AfeAfterIgnOn "255";
BA_ "GenSigCycleTime" SG_ 896 IP_FuelGageType 500;
BA_ "GenSigInvalidValue" SG_ 896 IP_FuelGageType "NA";

BA_ "GenSigCycleTime" SG_ 614 PEPS_Easy_open 40;
BA_ "GenSigInvalidValue" SG_ 614 PEPS_Easy_open "NA";
BA_ "GenSigCycleTime" SG_ 614 PEPS_KeyNumber 40;
BA_ "GenSigInvalidValue" SG_ 614 PEPS_KeyNumber "7";
BA_ "GenSigCycleTime" SG_ 614 PEPS_PEPSFailStatus 40;
BA_ "GenSigInvalidValue" SG_ 614 PEPS_PEPSFailStatus "NA";
BA_ "GenSigCycleTime" SG_ 614 PEPS_PowerDistributionFaultBit 40;
BA_ "GenSigInvalidValue" SG_ 614 PEPS_PowerDistributionFaultBit "NA";
BA_ "GenSigCycleTime" SG_ 614 PEPS_EngineStartupInhibitFb 40;
BA_ "GenSigInvalidValue" SG_ 614 PEPS_EngineStartupInhibitFb "NA";
BA_ "GenSigCycleTime" SG_ 614 PEPS_ImmoFeedback 40;
BA_ "GenSigInvalidValue" SG_ 614 PEPS_ImmoFeedback "NA";
BA_ "GenSigCycleTime" SG_ 614 PEPS_KeyAuthenticationStatus 40;
BA_ "GenSigInvalidValue" SG_ 614 PEPS_KeyAuthenticationStatus "NA";
BA_ "GenSigCycleTime" SG_ 614 PEPS_EngineStartupInhibitSts 40;
BA_ "GenSigInvalidValue" SG_ 614 PEPS_EngineStartupInhibitSts "NA";
BA_ "GenSigCycleTime" SG_ 614 PEPS_RemoteStartFeedback 40;
BA_ "GenSigInvalidValue" SG_ 614 PEPS_RemoteStartFeedback "NA";
BA_ "GenSigCycleTime" SG_ 614 PEPS_RemoteStartReq 40;
BA_ "GenSigInvalidValue" SG_ 614 PEPS_RemoteStartReq "3";
BA_ "GenSigCycleTime" SG_ 614 PEPS_StartupButtonSignal 40;
BA_ "GenSigInvalidValue" SG_ 614 PEPS_StartupButtonSignal "3";
BA_ "GenSigCycleTime" SG_ 614 PEPS_TrunkRequestSignal 40;
BA_ "GenSigInvalidValue" SG_ 614 PEPS_TrunkRequestSignal "NA";
BA_ "GenSigCycleTime" SG_ 614 PEPS_DoorHandleButtonSignal 40;
BA_ "GenSigInvalidValue" SG_ 614 PEPS_DoorHandleButtonSignal "NA";
BA_ "GenSigCycleTime" SG_ 614 PEPS_PowerDistributionStatus 40;
BA_ "GenSigInvalidValue" SG_ 614 PEPS_PowerDistributionStatus "3";
BA_ "GenSigCycleTime" SG_ 614 PEPS_StartControlsignal 40;
BA_ "GenSigInvalidValue" SG_ 614 PEPS_StartControlsignal "3";
BA_ "GenSigCycleTime" SG_ 614 PEPS_StartIndicatorSignal 40;
BA_ "GenSigInvalidValue" SG_ 614 PEPS_StartIndicatorSignal "NA";
BA_ "GenSigCycleTime" SG_ 614 PEPS_UnallowStart_ESCL_Error 40;
BA_ "GenSigInvalidValue" SG_ 614 PEPS_UnallowStart_ESCL_Error "NA";
BA_ "GenSigCycleTime" SG_ 614 PEPS_UnallowStart_ESCL_LOCK 40;
BA_ "GenSigInvalidValue" SG_ 614 PEPS_UnallowStart_ESCL_LOCK "NA";
BA_ "GenSigCycleTime" SG_ 614 PEPS_IMMOFailedAlarmsignal 40;
BA_ "GenSigInvalidValue" SG_ 614 PEPS_IMMOFailedAlarmsignal "NA";
BA_ "GenSigCycleTime" SG_ 614 PEPS_RemoteFailedAlarmSignal 40;
BA_ "GenSigInvalidValue" SG_ 614 PEPS_RemoteFailedAlarmSignal "NA";
BA_ "GenSigCycleTime" SG_ 614 PEPS_UnallowStartSignal_Not_PN 40;
BA_ "GenSigInvalidValue" SG_ 614 PEPS_UnallowStartSignal_Not_PN "NA";
BA_ "GenSigCycleTime" SG_ 614 PEPS_KeyUndetectedAlarmSignal 40;
BA_ "GenSigInvalidValue" SG_ 614 PEPS_KeyUndetectedAlarmSignal "NA";
BA_ "GenSigCycleTime" SG_ 614 PEPS_KeyInCarAlarmSignal 40;
BA_ "GenSigInvalidValue" SG_ 614 PEPS_KeyInCarAlarmSignal "NA";
BA_ "GenSigCycleTime" SG_ 614 PEPS_UnlockModeTransitionSignal 40;
BA_ "GenSigInvalidValue" SG_ 614 PEPS_UnlockModeTransitionSignal "NA";
BA_ "GenSigCycleTime" SG_ 614 PEPS_LuggageUnlockSignal 40;
BA_ "GenSigInvalidValue" SG_ 614 PEPS_LuggageUnlockSignal "3";
BA_ "GenSigCycleTime" SG_ 614 PEPS_SearchCarSignal 40;
BA_ "GenSigInvalidValue" SG_ 614 PEPS_SearchCarSignal "NA";
BA_ "GenSigCycleTime" SG_ 614 PEPS_RemoteWindowDownSignal 40;
BA_ "GenSigInvalidValue" SG_ 614 PEPS_RemoteWindowDownSignal "NA";
BA_ "GenSigCycleTime" SG_ 614 PEPS_RemoteWindowUpSignal 40;
BA_ "GenSigInvalidValue" SG_ 614 PEPS_RemoteWindowUpSignal "NA";
BA_ "GenSigCycleTime" SG_ 614 PEPS_LockSignal 40;
BA_ "GenSigInvalidValue" SG_ 614 PEPS_LockSignal "3";
BA_ "GenSigCycleTime" SG_ 614 PEPS_UnlockSignal 40;
BA_ "GenSigInvalidValue" SG_ 614 PEPS_UnlockSignal "3";
BA_ "GenSigCycleTime" SG_ 614 PEPS_KeyBatteryStatus 40;
BA_ "GenSigInvalidValue" SG_ 614 PEPS_KeyBatteryStatus "NA";
BA_ "GenSigCycleTime" SG_ 614 PEPS_KeyPositionStatus 40;
BA_ "GenSigInvalidValue" SG_ 614 PEPS_KeyPositionStatus "NA";

BA_ "GenSigCycleTime" SG_ 816 AC_AutowindSet3Status 100;
BA_ "GenSigInvalidValue" SG_ 816 AC_AutowindSet3Status "0";
BA_ "GenSigCycleTime" SG_ 816 AC_AutowindSet2Status 100;
BA_ "GenSigInvalidValue" SG_ 816 AC_AutowindSet2Status "0";
BA_ "GenSigCycleTime" SG_ 816 AC_AutowindSet1Status 100;
BA_ "GenSigInvalidValue" SG_ 816 AC_AutowindSet1Status "0";
BA_ "GenSigCycleTime" SG_ 816 AC_EnvironmentalTemp 100;
BA_ "GenSigStartValue" SG_ 816 AC_EnvironmentalTemp 255.000000;
BA_ "GenSigInvalidValue" SG_ 816 AC_EnvironmentalTemp "255";
BA_ "GenSigCycleTime" SG_ 816 AC_EnvironmentalTempVD 100;
BA_ "GenSigInvalidValue" SG_ 816 AC_EnvironmentalTempVD "1";
BA_ "GenSigCycleTime" SG_ 816 AC_AC_ReqValid 100;
BA_ "GenSigInvalidValue" SG_ 816 AC_AC_ReqValid "1";
BA_ "GenSigCycleTime" SG_ 816 AC_AC_Req 100;
BA_ "GenSigInvalidValue" SG_ 816 AC_AC_Req "NA";
BA_ "GenSigCycleTime" SG_ 816 AC_FrReqWindLevel 100;
BA_ "GenSigInvalidValue" SG_ 816 AC_FrReqWindLevel "15";
BA_ "GenSigCycleTime" SG_ 816 AC_SystemFailureFlag 100;
BA_ "GenSigInvalidValue" SG_ 816 AC_SystemFailureFlag "NA";
BA_ "GenSigCycleTime" SG_ 816 AC_RearDefrosterSwitch 100;
BA_ "GenSigInvalidValue" SG_ 816 AC_RearDefrosterSwitch "NA";

BA_ "GenSigCycleTime" SG_ 648 BCM_DriverDoorStatus 40;
BA_ "GenSigInvalidValue" SG_ 648 BCM_DriverDoorStatus "0";
BA_ "GenSigCycleTime" SG_ 648 BCM_BuzzerWarningMode 40;
BA_ "GenSigInvalidValue" SG_ 648 BCM_BuzzerWarningMode "NA";
BA_ "GenSigCycleTime" SG_ 648 BCM_SystemFailureFlag 40;
BA_ "GenSigInvalidValue" SG_ 648 BCM_SystemFailureFlag "NA";
BA_ "GenSigCycleTime" SG_ 648 BCM_LatchOverheatProtect 40;
BA_ "GenSigInvalidValue" SG_ 648 BCM_LatchOverheatProtect "NA";
BA_ "GenSigCycleTime" SG_ 648 BCM_FollowMeTurnon 40;
BA_ "GenSigInvalidValue" SG_ 648 BCM_FollowMeTurnon "NA";
BA_ "GenSigCycleTime" SG_ 648 BCM_ReversePosition 40;
BA_ "GenSigInvalidValue" SG_ 648 BCM_ReversePosition "NA";
BA_ "GenSigCycleTime" SG_ 648 BCM_TurnLightSwitchSts 40;
BA_ "GenSigInvalidValue" SG_ 648 BCM_TurnLightSwitchSts "3";
BA_ "GenSigCycleTime" SG_ 648 BCM_KeyAlarmStatus 40;
BA_ "GenSigInvalidValue" SG_ 648 BCM_KeyAlarmStatus "NA";
BA_ "GenSigCycleTime" SG_ 648 BCM_Statusrainsensor 40;
BA_ "GenSigInvalidValue" SG_ 648 BCM_Statusrainsensor "NA";
BA_ "GenSigCycleTime" SG_ 648 BCM_KeyInSignal 40;
BA_ "GenSigInvalidValue" SG_ 648 BCM_KeyInSignal "NA";
BA_ "GenSigCycleTime" SG_ 648 BCM_DriverDoorLockStatus 40;
BA_ "GenSigInvalidValue" SG_ 648 BCM_DriverDoorLockStatus "NA";
BA_ "GenSigCycleTime" SG_ 648 BCM_PowerStatusFeedback 40;
BA_ "GenSigInvalidValue" SG_ 648 BCM_PowerStatusFeedback "NA";
BA_ "GenSigCycleTime" SG_ 648 BCM_RearWiperStatus 40;
BA_ "GenSigInvalidValue" SG_ 648 BCM_RearWiperStatus "NA";
BA_ "GenSigCycleTime" SG_ 648 BCM_Statuslowbeam 40;
BA_ "GenSigInvalidValue" SG_ 648 BCM_Statuslowbeam "NA";
BA_ "GenSigCycleTime" SG_ 648 BCM_FrontWiperStatus 40;
BA_ "GenSigInvalidValue" SG_ 648 BCM_FrontWiperStatus "3";
BA_ "GenSigCycleTime" SG_ 648 BCM_RearDefrosterstatus 40;
BA_ "GenSigInvalidValue" SG_ 648 BCM_RearDefrosterstatus "3";
BA_ "GenSigCycleTime" SG_ 648 BCM_emergencylightstatus 40;
BA_ "GenSigInvalidValue" SG_ 648 BCM_emergencylightstatus "3";
BA_ "GenSigCycleTime" SG_ 648 BCM_SunroofMotor 40;
BA_ "GenSigInvalidValue" SG_ 648 BCM_SunroofMotor "3";
BA_ "GenSigCycleTime" SG_ 648 BCM_RightRearWinMotor 40;
BA_ "GenSigInvalidValue" SG_ 648 BCM_RightRearWinMotor "3";
BA_ "GenSigCycleTime" SG_ 648 BCM_LeftRearWinMotor 40;
BA_ "GenSigInvalidValue" SG_ 648 BCM_LeftRearWinMotor "3";
BA_ "GenSigCycleTime" SG_ 648 BCM_PassengerWinMotor 40;
BA_ "GenSigInvalidValue" SG_ 648 BCM_PassengerWinMotor "3";
BA_ "GenSigCycleTime" SG_ 648 BCM_DriverWinMotor 40;
BA_ "GenSigInvalidValue" SG_ 648 BCM_DriverWinMotor "3";
BA_ "GenSigCycleTime" SG_ 648 BCM_AutoHeadlightSts 40;
BA_ "GenSigInvalidValue" SG_ 648 BCM_AutoHeadlightSts "NA";
BA_ "GenSigCycleTime" SG_ 648 BCM_SunroofStatus 40;
BA_ "GenSigInvalidValue" SG_ 648 BCM_SunroofStatus "NA";
BA_ "GenSigCycleTime" SG_ 648 BCM_HoodStatus 40;
BA_ "GenSigInvalidValue" SG_ 648 BCM_HoodStatus "NA";
BA_ "GenSigCycleTime" SG_ 648 BCM_TrunkDoorStatus 40;
BA_ "GenSigInvalidValue" SG_ 648 BCM_TrunkDoorStatus "NA";
BA_ "GenSigCycleTime" SG_ 648 BCM_RightRearDoorStatus 40;
BA_ "GenSigInvalidValue" SG_ 648 BCM_RightRearDoorStatus "NA";
BA_ "GenSigCycleTime" SG_ 648 BCM_LeftRearDoorStatus 40;
BA_ "GenSigInvalidValue" SG_ 648 BCM_LeftRearDoorStatus "NA";
BA_ "GenSigCycleTime" SG_ 648 BCM_PassengerDoorStatus 40;
BA_ "GenSigInvalidValue" SG_ 648 BCM_PassengerDoorStatus "NA";
BA_ "GenSigCycleTime" SG_ 648 BCM_DriverDoorStatus 40;
BA_ "GenSigInvalidValue" SG_ 648 BCM_DriverDoorStatus "NA";
BA_ "GenSigCycleTime" SG_ 648 BCM_FrontWashStatus 40;
BA_ "GenSigInvalidValue" SG_ 648 BCM_FrontWashStatus "3";
BA_ "GenSigCycleTime" SG_ 648 BCM_PositionLampStatus 40;
BA_ "GenSigInvalidValue" SG_ 648 BCM_PositionLampStatus "3";
BA_ "GenSigCycleTime" SG_ 648 BCM_TurnIndicatorRight 40;
BA_ "GenSigInvalidValue" SG_ 648 BCM_TurnIndicatorRight "3";
BA_ "GenSigCycleTime" SG_ 648 BCM_TurnIndicatorLeft 40;
BA_ "GenSigInvalidValue" SG_ 648 BCM_TurnIndicatorLeft "3";
BA_ "GenSigCycleTime" SG_ 648 BCM_RearFoglampStatus 40;
BA_ "GenSigInvalidValue" SG_ 648 BCM_RearFoglampStatus "3";
BA_ "GenSigCycleTime" SG_ 648 BCM_FrontFoglampStatus 40;
BA_ "GenSigInvalidValue" SG_ 648 BCM_FrontFoglampStatus "3";
BA_ "GenSigCycleTime" SG_ 648 BCM_HighBeamStatus 40;
BA_ "GenSigInvalidValue" SG_ 648 BCM_HighBeamStatus "3";
BA_ "GenSigCycleTime" SG_ 648 BCM_LowBeamStatus 40;
BA_ "GenSigInvalidValue" SG_ 648 BCM_LowBeamStatus "3";
BA_ "GenSigCycleTime" SG_ 648 BCM_BuzzerWarningMode 40;
BA_ "GenSigInvalidValue" SG_ 648 BCM_BuzzerWarningMode "NA";
BA_ "GenSigCycleTime" SG_ 648 BCM_FollowMeTurnon 40;
BA_ "GenSigInvalidValue" SG_ 648 BCM_FollowMeTurnon "NA";
BA_ "GenSigCycleTime" SG_ 648 BCM_ReversePosition 40;
BA_ "GenSigInvalidValue" SG_ 648 BCM_ReversePosition "NA";
BA_ "GenSigCycleTime" SG_ 648 BCM_TurnLightSwitchSts 40;
BA_ "GenSigInvalidValue" SG_ 648 BCM_TurnLightSwitchSts "3";
BA_ "GenSigCycleTime" SG_ 648 BCM_KeyAlarmStatus 40;
BA_ "GenSigInvalidValue" SG_ 648 BCM_KeyAlarmStatus "NA";
BA_ "GenSigCycleTime" SG_ 648 BCM_Statusrainsensor 40;
BA_ "GenSigInvalidValue" SG_ 648 BCM_Statusrainsensor "NA";
BA_ "GenSigCycleTime" SG_ 648 BCM_KeyInSignal 40;
BA_ "GenSigInvalidValue" SG_ 648 BCM_KeyInSignal "NA";
BA_ "GenSigCycleTime" SG_ 648 BCM_PowerStatusFeedback 40;
BA_ "GenSigInvalidValue" SG_ 648 BCM_PowerStatusFeedback "NA";
BA_ "GenSigCycleTime" SG_ 648 BCM_Statuslowbeam 40;
BA_ "GenSigInvalidValue" SG_ 648 BCM_Statuslowbeam "NA";
BA_ "GenSigCycleTime" SG_ 648 BCM_RearWiperStatus 40;
BA_ "GenSigStartValue" SG_ 648 BCM_RearWiperStatus 1.000000;
BA_ "GenSigInvalidValue" SG_ 648 BCM_RearWiperStatus "NA";
BA_ "GenSigCycleTime" SG_ 648 BCM_SunroofStatus 40;
BA_ "GenSigInvalidValue" SG_ 648 BCM_SunroofStatus "NA";
BA_ "GenSigCycleTime" SG_ 648 BCM_HoodStatus 40;
BA_ "GenSigInvalidValue" SG_ 648 BCM_HoodStatus "NA";
BA_ "GenSigCycleTime" SG_ 648 BCM_TrunkDoorStatus 40;
BA_ "GenSigInvalidValue" SG_ 648 BCM_TrunkDoorStatus "NA";
BA_ "GenSigCycleTime" SG_ 648 BCM_RightRearDoorStatus 40;
BA_ "GenSigInvalidValue" SG_ 648 BCM_RightRearDoorStatus "NA";
BA_ "GenSigCycleTime" SG_ 648 BCM_LeftRearDoorStatus 40;
BA_ "GenSigInvalidValue" SG_ 648 BCM_LeftRearDoorStatus "NA";
BA_ "GenSigCycleTime" SG_ 648 BCM_PassengerDoorStatus 40;
BA_ "GenSigInvalidValue" SG_ 648 BCM_PassengerDoorStatus "NA";
BA_ "GenSigCycleTime" SG_ 648 BCM_DriverDoorStatus 40;
BA_ "GenSigInvalidValue" SG_ 648 BCM_DriverDoorStatus "NA";
BA_ "GenSigCycleTime" SG_ 648 BCM_PositionLampStatus 40;
BA_ "GenSigInvalidValue" SG_ 648 BCM_PositionLampStatus "3";
BA_ "GenSigCycleTime" SG_ 648 BCM_TurnIndicatorRight 40;
BA_ "GenSigInvalidValue" SG_ 648 BCM_TurnIndicatorRight "3";
BA_ "GenSigCycleTime" SG_ 648 BCM_TurnIndicatorLeft 40;
BA_ "GenSigInvalidValue" SG_ 648 BCM_TurnIndicatorLeft "3";
BA_ "GenSigCycleTime" SG_ 648 BCM_RearFoglampStatus 40;
BA_ "GenSigInvalidValue" SG_ 648 BCM_RearFoglampStatus "3";
BA_ "GenSigCycleTime" SG_ 648 BCM_FrontFoglampStatus 40;
BA_ "GenSigInvalidValue" SG_ 648 BCM_FrontFoglampStatus "3";
BA_ "GenSigCycleTime" SG_ 648 BCM_HighBeamStatus 40;
BA_ "GenSigInvalidValue" SG_ 648 BCM_HighBeamStatus "3";
BA_ "GenSigCycleTime" SG_ 648 BCM_LowBeamStatus 40;
BA_ "GenSigInvalidValue" SG_ 648 BCM_LowBeamStatus "3";

BA_ "GenSigCycleTime" SG_ 841 BCM_CarMode 500;
BA_ "GenSigInvalidValue" SG_ 841 BCM_CarMode "0";
BA_ "GenSigCycleTime" SG_ 841 BCM_PMSErrorFlag 500;
BA_ "GenSigInvalidValue" SG_ 841 BCM_PMSErrorFlag "NA";
BA_ "GenSigCycleTime" SG_ 841 BCM_LowPowerWarning 500;
BA_ "GenSigInvalidValue" SG_ 841 BCM_LowPowerWarning "NA";
BA_ "GenSigCycleTime" SG_ 841 BCM_PMSLevel 500;
BA_ "GenSigInvalidValue" SG_ 841 BCM_PMSLevel "NA";
BA_ "GenSigCycleTime" SG_ 841 BCM_CarMode 500;
BA_ "GenSigInvalidValue" SG_ 841 BCM_CarMode "0";
BA_ "GenSigCycleTime" SG_ 841 BCM_LowPowerWarning 500;
BA_ "GenSigInvalidValue" SG_ 841 BCM_LowPowerWarning "NA";
BA_ "GenSigCycleTime" SG_ 841 BCM_PMSLevel 500;
BA_ "GenSigInvalidValue" SG_ 841 BCM_PMSLevel "NA";

BA_ "GenSigCycleTime" SG_ 640 IP_FuelLowVoiceAlarm 50;
BA_ "GenSigCycleTime" SG_ 640 IP_WelcomeSoundAlarm 50;
BA_ "GenSigCycleTime" SG_ 640 IP_SteeringReturnVoiceAlarm 50;
BA_ "GenSigCycleTime" SG_ 640 IP_120kmVoiceAlarm 50;
BA_ "GenSigCycleTime" SG_ 640 IP_DisAfterIgnOn 50;
BA_ "GenSigInvalidValue" SG_ 640 IP_DisAfterIgnOn "16383";
BA_ "GenSigCycleTime" SG_ 640 IP_FuelLevelPercent 50;
BA_ "GenSigInvalidValue" SG_ 640 IP_FuelLevelPercent "127";
BA_ "GenSigCycleTime" SG_ 640 IP_MaintainReset 50;
BA_ "GenSigInvalidValue" SG_ 640 IP_MaintainReset "NA";
BA_ "GenSigCycleTime" SG_ 640 IP_FuelLeftover 50;
BA_ "GenSigInvalidValue" SG_ 640 IP_FuelLeftover "127";
BA_ "GenSigCycleTime" SG_ 640 IP_FuelLow 50;
BA_ "GenSigInvalidValue" SG_ 640 IP_FuelLow "NA";
BA_ "GenSigCycleTime" SG_ 640 IP_ModeSeting 50;
BA_ "GenSigInvalidValue" SG_ 640 IP_ModeSeting "3";
BA_ "GenSigCycleTime" SG_ 640 IP_FuelLeftover_AD 50;
BA_ "GenSigInvalidValue" SG_ 640 IP_FuelLeftover_AD "511";
BA_ "GenSigCycleTime" SG_ 640 IP_PassengerLCDALEDSts 50;
BA_ "GenSigInvalidValue" SG_ 640 IP_PassengerLCDALEDSts "NA";
BA_ "GenSigCycleTime" SG_ 640 IP_DriverLCDALEDSts 50;
BA_ "GenSigInvalidValue" SG_ 640 IP_DriverLCDALEDSts "NA";
BA_ "GenSigCycleTime" SG_ 640 EngineCoolanTemperatureHigh 50;
BA_ "GenSigInvalidValue" SG_ 640 EngineCoolanTemperatureHigh "NA";
BA_ "GenSigCycleTime" SG_ 640 IP_EngineOilPressureLowSts 50;
BA_ "GenSigInvalidValue" SG_ 640 IP_EngineOilPressureLowSts "NA";
BA_ "GenSigCycleTime" SG_ 640 IP_AirBagSysWarningLampSts 50;
BA_ "GenSigInvalidValue" SG_ 640 IP_AirBagSysWarningLampSts "3";
BA_ "GenSigCycleTime" SG_ 640 IP_DISFail 50;
BA_ "GenSigInvalidValue" SG_ 640 IP_DISFail "NA";
BA_ "GenSigCycleTime" SG_ 640 IP_QDashACCFail 50;
BA_ "GenSigInvalidValue" SG_ 640 IP_QDashACCFail "NA";

BA_ "GenSigCycleTime" SG_ 608 IP_DTE 40;
BA_ "GenSigInvalidValue" SG_ 608 IP_DTE "1023";

BA_ "GenSigCycleTime" SG_ 901 IP_RearSeatbeltWarningEnableFB 50;
BA_ "GenSigInvalidValue" SG_ 901 IP_RearSeatbeltWarningEnableFB "0";
BA_ "GenSigCycleTime" SG_ 901 IP_WarningVolumeSettingFB 50;
BA_ "GenSigInvalidValue" SG_ 901 IP_WarningVolumeSettingFB "0";

BA_ "GenSigCycleTime" SG_ 1288 HU_IMS_LegalDriverFeedback 100;
BA_ "GenSigInvalidValue" SG_ 1288 HU_IMS_LegalDriverFeedback "0";
BA_ "GenSigCycleTime" SG_ 1288 HU_IMS_DrowsinessStatus 100;
BA_ "GenSigInvalidValue" SG_ 1288 HU_IMS_DrowsinessStatus "7";
BA_ "GenSigCycleTime" SG_ 1288 HU_IMS_DistractionStatus 100;
BA_ "GenSigInvalidValue" SG_ 1288 HU_IMS_DistractionStatus "3";
BA_ "GenSigCycleTime" SG_ 1288 HU_IMS_DriverID 100;
BA_ "GenSigInvalidValue" SG_ 1288 HU_IMS_DriverID "0";

BA_ "GenSigCycleTime" SG_ 760 HU_360AVMdetectionRequest 100;
BA_ "GenSigInvalidValue" SG_ 760 HU_360AVMdetectionRequest "NA";
BA_ "GenSigCycleTime" SG_ 760 HU_BcallReq 100;
BA_ "GenSigInvalidValue" SG_ 760 HU_BcallReq "0";
BA_ "GenSigCycleTime" SG_ 760 HU_SurrondingMonitorDone 100;
BA_ "GenSigInvalidValue" SG_ 760 HU_SurrondingMonitorDone "0";
BA_ "GenSigCycleTime" SG_ 760 HU_APAModeSelect 100;
BA_ "GenSigInvalidValue" SG_ 760 HU_APAModeSelect "3";
BA_ "GenSigCycleTime" SG_ 760 HU_NaviIconNumber 100;
BA_ "GenSigInvalidValue" SG_ 760 HU_NaviIconNumber "NA";
BA_ "GenSigCycleTime" SG_ 760 HU_NaviDistance 100;
BA_ "GenSigInvalidValue" SG_ 760 HU_NaviDistance "131071";
BA_ "GenSigCycleTime" SG_ 760 HU_RegisterStatus 100;
BA_ "GenSigInvalidValue" SG_ 760 HU_RegisterStatus "3";
BA_ "GenSigCycleTime" SG_ 760 HU_TUIDReq 100;
BA_ "GenSigInvalidValue" SG_ 760 HU_TUIDReq "3";
BA_ "GenSigCycleTime" SG_ 760 HU_AVMswitch 100;
BA_ "GenSigInvalidValue" SG_ 760 HU_AVMswitch "0";
BA_ "GenSigCycleTime" SG_ 760 HU_PACModeSelect 100;
BA_ "GenSigInvalidValue" SG_ 760 HU_PACModeSelect "0";

BA_ "GenSigCycleTime" SG_ 761 HU_NaviIconNumber_2 100;
BA_ "GenSigInvalidValue" SG_ 761 HU_NaviIconNumber_2 "0";
BA_ "GenSigCycleTime" SG_ 761 HU_ACControlMode 100;
BA_ "GenSigInvalidValue" SG_ 761 HU_ACControlMode "3";
BA_ "GenSigCycleTime" SG_ 761 HU_SunroofControlReq 100;
BA_ "GenSigInvalidValue" SG_ 761 HU_SunroofControlReq "3";
BA_ "GenSigCycleTime" SG_ 761 HU_CirculationModeReq 100;
BA_ "GenSigInvalidValue" SG_ 761 HU_CirculationModeReq "NA";
BA_ "GenSigCycleTime" SG_ 761 HU_ACreq 100;
BA_ "GenSigInvalidValue" SG_ 761 HU_ACreq "NA";
BA_ "GenSigCycleTime" SG_ 761 HU_SyncReq 100;
BA_ "GenSigInvalidValue" SG_ 761 HU_SyncReq "NA";
BA_ "GenSigCycleTime" SG_ 761 HU_ACLRTempAdjustValueReq 100;
BA_ "GenSigInvalidValue" SG_ 761 HU_ACLRTempAdjustValueReq "NA";
BA_ "GenSigCycleTime" SG_ 761 HU_ACFanAdjustValueReq 100;
BA_ "GenSigInvalidValue" SG_ 761 HU_ACFanAdjustValueReq "NA";
BA_ "GenSigCycleTime" SG_ 761 HU_ACFrontModeAdjustReq 100;
BA_ "GenSigInvalidValue" SG_ 761 HU_ACFrontModeAdjustReq "NA";
BA_ "GenSigCycleTime" SG_ 761 HU_ACLFTempAdjustValueReq 100;
BA_ "GenSigInvalidValue" SG_ 761 HU_ACLFTempAdjustValueReq "NA";
BA_ "GenSigCycleTime" SG_ 761 HU_ACDEFAdjustReq 100;
BA_ "GenSigInvalidValue" SG_ 761 HU_ACDEFAdjustReq "NA";
BA_ "GenSigCycleTime" SG_ 761 HU_FrontACOffReq 100;
BA_ "GenSigInvalidValue" SG_ 761 HU_FrontACOffReq "NA";
BA_ "GenSigCycleTime" SG_ 761 HU_FrontAUTOACOnReq 100;
BA_ "GenSigInvalidValue" SG_ 761 HU_FrontAUTOACOnReq "NA";
BA_ "GenSigCycleTime" SG_ 761 HU_ACRDEFAdjustReq 100;
BA_ "GenSigInvalidValue" SG_ 761 HU_ACRDEFAdjustReq "NA";

BA_ "GenSigCycleTime" SG_ 762 HU_navStatus 100;
BA_ "GenSigInvalidValue" SG_ 762 HU_navStatus "1";
BA_ "GenSigCycleTime" SG_ 762 HU_navSpeedLimitUnits 100;
BA_ "GenSigInvalidValue" SG_ 762 HU_navSpeedLimitUnits "NA";
BA_ "GenSigCycleTime" SG_ 762 HU_navSpeedLimitStatus 100;
BA_ "GenSigInvalidValue" SG_ 762 HU_navSpeedLimitStatus "NA";
BA_ "GenSigCycleTime" SG_ 762 HU_navSpeedLimit 100;
BA_ "GenSigInvalidValue" SG_ 762 HU_navSpeedLimit "NA";
BA_ "GenSigCycleTime" SG_ 762 HU_navCurrentRoadType 100;
BA_ "GenSigInvalidValue" SG_ 762 HU_navCurrentRoadType "7";
BA_ "GenSigCycleTime" SG_ 762 HU_navCountryCode 100;
BA_ "GenSigInvalidValue" SG_ 762 HU_navCountryCode "NA";

BA_ "GenSigCycleTime" SG_ 1280 HU_CurrentLocationValid 1000;
BA_ "GenSigInvalidValue" SG_ 1280 HU_CurrentLocationValid "NA";
BA_ "GenSigCycleTime" SG_ 1280 HU_CurrentLocationLatitude 1000;
BA_ "GenSigInvalidValue" SG_ 1280 HU_CurrentLocationLatitude "268435455";
BA_ "GenSigCycleTime" SG_ 1280 HU_CurrentLocationLongitude 1000;
BA_ "GenSigInvalidValue" SG_ 1280 HU_CurrentLocationLongitude "536870911";

BA_ "GenSigCycleTime" SG_ 1281 HU_LocalTimeSystem 1000;
BA_ "GenSigCycleTime" SG_ 1281 HU_LocalTimeValid 1000;
BA_ "GenSigInvalidValue" SG_ 1281 HU_LocalTimeValid "NA";
BA_ "GenSigCycleTime" SG_ 1281 HU_LocalTimeSecond 1000;
BA_ "GenSigInvalidValue" SG_ 1281 HU_LocalTimeSecond "NA";
BA_ "GenSigCycleTime" SG_ 1281 HU_LocalTimeMinute 1000;
BA_ "GenSigInvalidValue" SG_ 1281 HU_LocalTimeMinute "NA";
BA_ "GenSigCycleTime" SG_ 1281 HU_LocalTimeHour 1000;
BA_ "GenSigInvalidValue" SG_ 1281 HU_LocalTimeHour "NA";
BA_ "GenSigCycleTime" SG_ 1281 HU_LocalTimeDate 1000;
BA_ "GenSigStartValue" SG_ 1281 HU_LocalTimeDate 1.000000;
BA_ "GenSigInvalidValue" SG_ 1281 HU_LocalTimeDate "NA";
BA_ "GenSigCycleTime" SG_ 1281 HU_LocalTimeMonth 1000;
BA_ "GenSigStartValue" SG_ 1281 HU_LocalTimeMonth 1.000000;
BA_ "GenSigInvalidValue" SG_ 1281 HU_LocalTimeMonth "NA";
BA_ "GenSigCycleTime" SG_ 1281 HU_LocalTimeYear 1000;
BA_ "GenSigInvalidValue" SG_ 1281 HU_LocalTimeYear "NA";

BA_ "GenSigCycleTime" SG_ 1408 HU_MaintainRemindReq 1000;
BA_ "GenSigInvalidValue" SG_ 1408 HU_MaintainRemindReq "3";
BA_ "GenSigCycleTime" SG_ 1408 HU_LeaveMaintainDay 1000;
BA_ "GenSigInvalidValue" SG_ 1408 HU_LeaveMaintainDay "4095";
BA_ "GenSigCycleTime" SG_ 1408 HU_LeaveMaintainMileage 1000;
BA_ "GenSigInvalidValue" SG_ 1408 HU_LeaveMaintainMileage "1048575";

BA_ "GenSigCycleTime" SG_ 662 TBOX_BCallStatus 100;
BA_ "GenSigInvalidValue" SG_ 662 TBOX_BCallStatus "7";
BA_ "GenSigCycleTime" SG_ 662 TBOX_RmoteRoof 100;
BA_ "GenSigInvalidValue" SG_ 662 TBOX_RmoteRoof "0";
BA_ "GenSigCycleTime" SG_ 662 TBOX_SearchCarReq 100;
BA_ "GenSigInvalidValue" SG_ 662 TBOX_SearchCarReq "0";
BA_ "GenSigCycleTime" SG_ 662 TBOX_ACTempValueReq 100;
BA_ "GenSigInvalidValue" SG_ 662 TBOX_ACTempValueReq "NA";
BA_ "GenSigCycleTime" SG_ 662 TBOX_RemoteStartRunTime 100;
BA_ "GenSigInvalidValue" SG_ 662 TBOX_RemoteStartRunTime "0";
BA_ "GenSigCycleTime" SG_ 662 TBOX_VINMatchStatus 100;
BA_ "GenSigInvalidValue" SG_ 662 TBOX_VINMatchStatus "NA";
BA_ "GenSigCycleTime" SG_ 662 TBOX_VINReq 100;
BA_ "GenSigInvalidValue" SG_ 662 TBOX_VINReq "NA";
BA_ "GenSigCycleTime" SG_ 662 TBOX_CallStatus 100;
BA_ "GenSigInvalidValue" SG_ 662 TBOX_CallStatus "NA";
BA_ "GenSigCycleTime" SG_ 662 TBOX_AudioRequest 100;
BA_ "GenSigInvalidValue" SG_ 662 TBOX_AudioRequest "NA";
BA_ "GenSigCycleTime" SG_ 662 TBOX_VehicleVedioDetectReq 100;
BA_ "GenSigInvalidValue" SG_ 662 TBOX_VehicleVedioDetectReq "0";
BA_ "GenSigCycleTime" SG_ 662 TBOX_LockCommand 100;
BA_ "GenSigInvalidValue" SG_ 662 TBOX_LockCommand "NA";
BA_ "GenSigCycleTime" SG_ 662 TBOX_EngineStartupInhibit 100;
BA_ "GenSigInvalidValue" SG_ 662 TBOX_EngineStartupInhibit "NA";
BA_ "GenSigCycleTime" SG_ 662 TBOX_RemoteEngineStartupReq 100;
BA_ "GenSigInvalidValue" SG_ 662 TBOX_RemoteEngineStartupReq "NA";

BA_ "GenSigCycleTime" SG_ 992 AVM_OverspeedWarning 50;
BA_ "GenSigInvalidValue" SG_ 992 AVM_OverspeedWarning "0";
BA_ "GenSigCycleTime" SG_ 992 AVM_VisionAngle 50;
BA_ "GenSigInvalidValue" SG_ 992 AVM_VisionAngle "3";
BA_ "GenSigCycleTime" SG_ 992 AVM_DisplayForm 50;
BA_ "GenSigInvalidValue" SG_ 992 AVM_DisplayForm "10";
BA_ "GenSigCycleTime" SG_ 992 AVM_LineOnOff 50;
BA_ "GenSigInvalidValue" SG_ 992 AVM_LineOnOff "3";
BA_ "GenSigCycleTime" SG_ 992 AVM_DisplayReq 50;
BA_ "GenSigInvalidValue" SG_ 992 AVM_DisplayReq "NA";

BA_ "GenSigCycleTime" SG_ 1535 BCM_MusicPlayRequestSignal 100;
BA_ "GenSigCycleTime" SG_ 1535 BCM_Musiclightfeedback 100;
BA_ "GenSigCycleTime" SG_ 1535 BCM_MusicPlayRequestSignal 100;
BA_ "GenSigCycleTime" SG_ 1535 BCM_OutWelcomeSoundFeedback 100;
BA_ "GenSigCycleTime" SG_ 1535 BCM_AutoLeaveLockSetStatus 100;
BA_ "GenSigInvalidValue" SG_ 1535 BCM_AutoLeaveLockSetStatus "0";
BA_ "GenSigCycleTime" SG_ 1535 BCM_AutoLockFeedback 100;
BA_ "GenSigInvalidValue" SG_ 1535 BCM_AutoLockFeedback "0";
BA_ "GenSigCycleTime" SG_ 1535 BCM_WinOpenWarn 100;
BA_ "GenSigInvalidValue" SG_ 1535 BCM_WinOpenWarn "0";
BA_ "GenSigCycleTime" SG_ 1535 BCM_TwiceLockDoorSetStatus 100;
BA_ "GenSigInvalidValue" SG_ 1535 BCM_TwiceLockDoorSetStatus "0";
BA_ "GenSigCycleTime" SG_ 1535 BCM_RearWiperSetStatus 100;
BA_ "GenSigInvalidValue" SG_ 1535 BCM_RearWiperSetStatus "0";
BA_ "GenSigCycleTime" SG_ 1535 BCM_RemoteWindowDownSetStaus 100;
BA_ "GenSigStartValue" SG_ 1535 BCM_RemoteWindowDownSetStaus 1.000000;
BA_ "GenSigInvalidValue" SG_ 1535 BCM_RemoteWindowDownSetStaus "0";
BA_ "GenSigCycleTime" SG_ 1535 BCM_SunroofRainSetStatus 100;
BA_ "GenSigInvalidValue" SG_ 1535 BCM_SunroofRainSetStatus "0";
BA_ "GenSigCycleTime" SG_ 1535 BCM_MirrorAutoFoldSetStatus 100;
BA_ "GenSigInvalidValue" SG_ 1535 BCM_MirrorAutoFoldSetStatus "0";
BA_ "GenSigCycleTime" SG_ 1535 BCM_FollowMeHomeLightSetStatus 100;
BA_ "GenSigInvalidValue" SG_ 1535 BCM_FollowMeHomeLightSetStatus "0";
BA_ "GenSigCycleTime" SG_ 1535 BCM_LaneChangeTurnLightSetStatus 100;
BA_ "GenSigInvalidValue" SG_ 1535 BCM_LaneChangeTurnLightSetStatus "0";
BA_ "GenSigCycleTime" SG_ 1535 BCM_RKEUnlockDoorTypeSetStatus 100;
BA_ "GenSigInvalidValue" SG_ 1535 BCM_RKEUnlockDoorTypeSetStatus "0";
BA_ "GenSigCycleTime" SG_ 1535 BCM_AutoIGNOFFUnlockSetStatus 100;
BA_ "GenSigInvalidValue" SG_ 1535 BCM_AutoIGNOFFUnlockSetStatus "0";
BA_ "GenSigCycleTime" SG_ 1535 BCM_AutoSpeedLockSetStatus 100;
BA_ "GenSigInvalidValue" SG_ 1535 BCM_AutoSpeedLockSetStatus "0";

BA_ "GenSigCycleTime" SG_ 1520 LCM_AtmoLightAutoAdjustSts 100;
BA_ "GenSigInvalidValue" SG_ 1520 LCM_AtmoLightAutoAdjustSts "0";
BA_ "GenSigCycleTime" SG_ 1520 LCM_AtmoLightAAEnableSts 100;
BA_ "GenSigInvalidValue" SG_ 1520 LCM_AtmoLightAAEnableSts "0";
BA_ "GenSigCycleTime" SG_ 1520 LCM_DRLSetFB 100;
BA_ "GenSigStartValue" SG_ 1520 LCM_DRLSetFB 1.000000;
BA_ "GenSigInvalidValue" SG_ 1520 LCM_DRLSetFB "0";
BA_ "GenSigCycleTime" SG_ 1520 LCM_Dimmerlevel 100;
BA_ "GenSigInvalidValue" SG_ 1520 LCM_Dimmerlevel "31";
BA_ "GenSigCycleTime" SG_ 1520 LCM_AmbientLightColorSetStas 100;
BA_ "GenSigInvalidValue" SG_ 1520 LCM_AmbientLightColorSetStas "0";
BA_ "GenSigCycleTime" SG_ 1520 LCM_AmbientLightBrightSetStas 100;
BA_ "GenSigInvalidValue" SG_ 1520 LCM_AmbientLightBrightSetStas "0";

BA_ "GenSigCycleTime" SG_ 614 PEPS_Easy_open 40;
BA_ "GenSigInvalidValue" SG_ 614 PEPS_Easy_open "NA";
BA_ "GenSigCycleTime" SG_ 614 PEPS_KeyNumber 40;
BA_ "GenSigInvalidValue" SG_ 614 PEPS_KeyNumber "7";
BA_ "GenSigCycleTime" SG_ 614 PEPS_PEPSFailStatus 40;
BA_ "GenSigInvalidValue" SG_ 614 PEPS_PEPSFailStatus "NA";
BA_ "GenSigCycleTime" SG_ 614 PEPS_PowerDistributionFaultBit 40;
BA_ "GenSigInvalidValue" SG_ 614 PEPS_PowerDistributionFaultBit "NA";
BA_ "GenSigCycleTime" SG_ 614 PEPS_EngineStartupInhibitFb 40;
BA_ "GenSigInvalidValue" SG_ 614 PEPS_EngineStartupInhibitFb "NA";
BA_ "GenSigCycleTime" SG_ 614 PEPS_ImmoFeedback 40;
BA_ "GenSigInvalidValue" SG_ 614 PEPS_ImmoFeedback "NA";
BA_ "GenSigCycleTime" SG_ 614 PEPS_KeyAuthenticationStatus 40;
BA_ "GenSigInvalidValue" SG_ 614 PEPS_KeyAuthenticationStatus "NA";
BA_ "GenSigCycleTime" SG_ 614 PEPS_EngineStartupInhibitSts 40;
BA_ "GenSigInvalidValue" SG_ 614 PEPS_EngineStartupInhibitSts "NA";
BA_ "GenSigCycleTime" SG_ 614 PEPS_RemoteStartFeedback 40;
BA_ "GenSigInvalidValue" SG_ 614 PEPS_RemoteStartFeedback "NA";
BA_ "GenSigCycleTime" SG_ 614 PEPS_RemoteStartReq 40;
BA_ "GenSigInvalidValue" SG_ 614 PEPS_RemoteStartReq "3";
BA_ "GenSigCycleTime" SG_ 614 PEPS_StartupButtonSignal 40;
BA_ "GenSigInvalidValue" SG_ 614 PEPS_StartupButtonSignal "3";
BA_ "GenSigCycleTime" SG_ 614 PEPS_TrunkRequestSignal 40;
BA_ "GenSigInvalidValue" SG_ 614 PEPS_TrunkRequestSignal "NA";
BA_ "GenSigCycleTime" SG_ 614 PEPS_DoorHandleButtonSignal 40;
BA_ "GenSigInvalidValue" SG_ 614 PEPS_DoorHandleButtonSignal "NA";
BA_ "GenSigCycleTime" SG_ 614 PEPS_PowerDistributionStatus 40;
BA_ "GenSigInvalidValue" SG_ 614 PEPS_PowerDistributionStatus "3";
BA_ "GenSigCycleTime" SG_ 614 PEPS_StartControlsignal 40;
BA_ "GenSigInvalidValue" SG_ 614 PEPS_StartControlsignal "3";
BA_ "GenSigCycleTime" SG_ 614 PEPS_StartIndicatorSignal 40;
BA_ "GenSigInvalidValue" SG_ 614 PEPS_StartIndicatorSignal "NA";
BA_ "GenSigCycleTime" SG_ 614 PEPS_UnallowStart_ESCL_Error 40;
BA_ "GenSigInvalidValue" SG_ 614 PEPS_UnallowStart_ESCL_Error "NA";
BA_ "GenSigCycleTime" SG_ 614 PEPS_UnallowStart_ESCL_LOCK 40;
BA_ "GenSigInvalidValue" SG_ 614 PEPS_UnallowStart_ESCL_LOCK "NA";
BA_ "GenSigCycleTime" SG_ 614 PEPS_IMMOFailedAlarmsignal 40;
BA_ "GenSigInvalidValue" SG_ 614 PEPS_IMMOFailedAlarmsignal "NA";
BA_ "GenSigCycleTime" SG_ 614 PEPS_RemoteFailedAlarmSignal 40;
BA_ "GenSigInvalidValue" SG_ 614 PEPS_RemoteFailedAlarmSignal "NA";
BA_ "GenSigCycleTime" SG_ 614 PEPS_UnallowStartSignal_Not_PN 40;
BA_ "GenSigInvalidValue" SG_ 614 PEPS_UnallowStartSignal_Not_PN "NA";
BA_ "GenSigCycleTime" SG_ 614 PEPS_KeyUndetectedAlarmSignal 40;
BA_ "GenSigInvalidValue" SG_ 614 PEPS_KeyUndetectedAlarmSignal "NA";
BA_ "GenSigCycleTime" SG_ 614 PEPS_KeyInCarAlarmSignal 40;
BA_ "GenSigInvalidValue" SG_ 614 PEPS_KeyInCarAlarmSignal "NA";
BA_ "GenSigCycleTime" SG_ 614 PEPS_UnlockModeTransitionSignal 40;
BA_ "GenSigInvalidValue" SG_ 614 PEPS_UnlockModeTransitionSignal "NA";
BA_ "GenSigCycleTime" SG_ 614 PEPS_LuggageUnlockSignal 40;
BA_ "GenSigInvalidValue" SG_ 614 PEPS_LuggageUnlockSignal "3";
BA_ "GenSigCycleTime" SG_ 614 PEPS_SearchCarSignal 40;
BA_ "GenSigInvalidValue" SG_ 614 PEPS_SearchCarSignal "NA";
BA_ "GenSigCycleTime" SG_ 614 PEPS_RemoteWindowDownSignal 40;
BA_ "GenSigInvalidValue" SG_ 614 PEPS_RemoteWindowDownSignal "NA";
BA_ "GenSigCycleTime" SG_ 614 PEPS_RemoteWindowUpSignal 40;
BA_ "GenSigInvalidValue" SG_ 614 PEPS_RemoteWindowUpSignal "NA";
BA_ "GenSigCycleTime" SG_ 614 PEPS_LockSignal 40;
BA_ "GenSigInvalidValue" SG_ 614 PEPS_LockSignal "3";
BA_ "GenSigCycleTime" SG_ 614 PEPS_UnlockSignal 40;
BA_ "GenSigInvalidValue" SG_ 614 PEPS_UnlockSignal "3";
BA_ "GenSigCycleTime" SG_ 614 PEPS_KeyBatteryStatus 40;
BA_ "GenSigInvalidValue" SG_ 614 PEPS_KeyBatteryStatus "NA";
BA_ "GenSigCycleTime" SG_ 614 PEPS_KeyPositionStatus 40;
BA_ "GenSigInvalidValue" SG_ 614 PEPS_KeyPositionStatus "NA";

BA_ "GenSigCycleTime" SG_ 816 AC_AutowindSet3Status 100;
BA_ "GenSigInvalidValue" SG_ 816 AC_AutowindSet3Status "0";
BA_ "GenSigCycleTime" SG_ 816 AC_AutowindSet2Status 100;
BA_ "GenSigInvalidValue" SG_ 816 AC_AutowindSet2Status "0";
BA_ "GenSigCycleTime" SG_ 816 AC_AutowindSet1Status 100;
BA_ "GenSigInvalidValue" SG_ 816 AC_AutowindSet1Status "0";
BA_ "GenSigCycleTime" SG_ 816 AC_EnvironmentalTemp 100;
BA_ "GenSigStartValue" SG_ 816 AC_EnvironmentalTemp 255.000000;
BA_ "GenSigInvalidValue" SG_ 816 AC_EnvironmentalTemp "255";
BA_ "GenSigCycleTime" SG_ 816 AC_EnvironmentalTempVD 100;
BA_ "GenSigInvalidValue" SG_ 816 AC_EnvironmentalTempVD "1";
BA_ "GenSigCycleTime" SG_ 816 AC_AC_ReqValid 100;
BA_ "GenSigInvalidValue" SG_ 816 AC_AC_ReqValid "1";
BA_ "GenSigCycleTime" SG_ 816 AC_AC_Req 100;
BA_ "GenSigInvalidValue" SG_ 816 AC_AC_Req "NA";
BA_ "GenSigCycleTime" SG_ 816 AC_FrReqWindLevel 100;
BA_ "GenSigInvalidValue" SG_ 816 AC_FrReqWindLevel "15";
BA_ "GenSigCycleTime" SG_ 816 AC_SystemFailureFlag 100;
BA_ "GenSigInvalidValue" SG_ 816 AC_SystemFailureFlag "NA";
BA_ "GenSigCycleTime" SG_ 816 AC_RearDefrosterSwitch 100;
BA_ "GenSigInvalidValue" SG_ 816 AC_RearDefrosterSwitch "NA";

BA_ "GenSigCycleTime" SG_ 832 AC_ACOnOff 100;
BA_ "GenSigInvalidValue" SG_ 832 AC_ACOnOff "3";
BA_ "GenSigCycleTime" SG_ 832 AC_EnvironmentalTemp_RAW 100;
BA_ "GenSigStartValue" SG_ 832 AC_EnvironmentalTemp_RAW 255.000000;
BA_ "GenSigInvalidValue" SG_ 832 AC_EnvironmentalTemp_RAW "255";
BA_ "GenSigCycleTime" SG_ 832 AC_PlasmaSt 100;
BA_ "GenSigInvalidValue" SG_ 832 AC_PlasmaSt "NA";
BA_ "GenSigCycleTime" SG_ 832 AC_AQSSt 100;
BA_ "GenSigInvalidValue" SG_ 832 AC_AQSSt "NA";
BA_ "GenSigCycleTime" SG_ 832 AC_RecycleType 100;
BA_ "GenSigInvalidValue" SG_ 832 AC_RecycleType "4";
BA_ "GenSigCycleTime" SG_ 832 AC_ClimateDisplayReq 100;
BA_ "GenSigInvalidValue" SG_ 832 AC_ClimateDisplayReq "NA";
BA_ "GenSigCycleTime" SG_ 832 AC_PaReqTemp 100;
BA_ "GenSigInvalidValue" SG_ 832 AC_PaReqTemp "31";
BA_ "GenSigCycleTime" SG_ 832 AC_DriverReqTemp 100;
BA_ "GenSigInvalidValue" SG_ 832 AC_DriverReqTemp "31";
BA_ "GenSigCycleTime" SG_ 832 AC_DriverReqTempModel 100;
BA_ "GenSigInvalidValue" SG_ 832 AC_DriverReqTempModel "31";
BA_ "GenSigCycleTime" SG_ 832 AC_AutoWorkStatus 100;
BA_ "GenSigInvalidValue" SG_ 832 AC_AutoWorkStatus "NA";
BA_ "GenSigCycleTime" SG_ 832 AC_FrAutoSts 100;
BA_ "GenSigInvalidValue" SG_ 832 AC_FrAutoSts "3";
BA_ "GenSigCycleTime" SG_ 832 AC_ACSt 100;
BA_ "GenSigInvalidValue" SG_ 832 AC_ACSt "NA";
BA_ "GenSigCycleTime" SG_ 832 AC_FrBlowType 100;
BA_ "GenSigInvalidValue" SG_ 832 AC_FrBlowType "7";

BA_ "GenSigCycleTime" SG_ 896 IP_EngineOffTime 500;
BA_ "GenSigInvalidValue" SG_ 896 IP_EngineOffTime "65535";
BA_ "GenSigCycleTime" SG_ 896 IP_FuelLevel 500;
BA_ "GenSigInvalidValue" SG_ 896 IP_FuelLevel "NA";
BA_ "GenSigCycleTime" SG_ 896 IP_AvgFuelConsumption 500;
BA_ "GenSigInvalidValue" SG_ 896 IP_AvgFuelConsumption "255";
BA_ "GenSigCycleTime" SG_ 896 IP_TotalOdometer 500;
BA_ "GenSigInvalidValue" SG_ 896 IP_TotalOdometer "16777215";
BA_ "GenSigCycleTime" SG_ 896 IP_AfeAfterIgnOn 500;
BA_ "GenSigInvalidValue" SG_ 896 IP_AfeAfterIgnOn "255";
BA_ "GenSigCycleTime" SG_ 896 IP_FuelGageType 500;
BA_ "GenSigInvalidValue" SG_ 896 IP_FuelGageType "NA";

BA_ "GenSigCycleTime" SG_ 688 EMS_SartPrompt 50;
BA_ "GenSigInvalidValue" SG_ 688 EMS_SartPrompt "3";
BA_ "GenSigCycleTime" SG_ 688 EMS_ImmoConfiguration 50;
BA_ "GenSigStartValue" SG_ 688 EMS_ImmoConfiguration 3.000000;
BA_ "GenSigInvalidValue" SG_ 688 EMS_ImmoConfiguration "3";
BA_ "GenSigCycleTime" SG_ 688 EPB_Status 50;
BA_ "GenSigInvalidValue" SG_ 688 EPB_Status "3";
BA_ "GenSigCycleTime" SG_ 688 EPB_BrakeLightOnRequest 50;
BA_ "GenSigStartValue" SG_ 688 EPB_BrakeLightOnRequest 3.000000;
BA_ "GenSigInvalidValue" SG_ 688 EPB_BrakeLightOnRequest "3";
BA_ "GenSigCycleTime" SG_ 688 TCU_GearShiftPositon 50;
BA_ "GenSigStartValue" SG_ 688 TCU_GearShiftPositon 14.000000;
BA_ "GenSigInvalidValue" SG_ 688 TCU_GearShiftPositon "15";
BA_ "GenSigCycleTime" SG_ 688 TCU_ShiftPostionValid 50;
BA_ "GenSigStartValue" SG_ 688 TCU_ShiftPostionValid 1.000000;
BA_ "GenSigInvalidValue" SG_ 688 TCU_ShiftPostionValid "1";
BA_ "GenSigCycleTime" SG_ 688 SAS_SteeringAngle 50;
BA_ "GenSigStartValue" SG_ 688 SAS_SteeringAngle 32767.000000;
BA_ "GenSigInvalidValue" SG_ 688 SAS_SteeringAngle "32767";
BA_ "GenSigCycleTime" SG_ 688 SRS_CrashOutputStatusCheckSum 50;
BA_ "GenSigInvalidValue" SG_ 688 SRS_CrashOutputStatusCheckSum "0";
BA_ "GenSigCycleTime" SG_ 688 SRS_CrashOutputStatus 50;
BA_ "GenSigInvalidValue" SG_ 688 SRS_CrashOutputStatus "0";
BA_ "GenSigCycleTime" SG_ 688 EMS_ImmoFeedback 50;
BA_ "GenSigStartValue" SG_ 688 EMS_ImmoFeedback 3.000000;
BA_ "GenSigInvalidValue" SG_ 688 EMS_ImmoFeedback "3";
BA_ "GenSigCycleTime" SG_ 688 TCU_STLKfailure 50;
BA_ "GenSigInvalidValue" SG_ 688 TCU_STLKfailure "3";
BA_ "GenSigCycleTime" SG_ 688 EMS_EngineStartupEnd 50;
BA_ "GenSigStartValue" SG_ 688 EMS_EngineStartupEnd 3.000000;
BA_ "GenSigInvalidValue" SG_ 688 EMS_EngineStartupEnd "3";
BA_ "GenSigCycleTime" SG_ 688 EMS_CompressorStatus 50;
BA_ "GenSigInvalidValue" SG_ 688 EMS_CompressorStatus "3";
BA_ "GenSigCycleTime" SG_ 688 SAS_SteeringAngleValid 50;
BA_ "GenSigStartValue" SG_ 688 SAS_SteeringAngleValid 1.000000;
BA_ "GenSigInvalidValue" SG_ 688 SAS_SteeringAngleValid "1";
BA_ "GenSigCycleTime" SG_ 688 SAS_Calibrated 50;
BA_ "GenSigInvalidValue" SG_ 688 SAS_Calibrated "LastValue";
BA_ "GenSigCycleTime" SG_ 688 ESP_BrakeLightOnRequest 50;
BA_ "GenSigStartValue" SG_ 688 ESP_BrakeLightOnRequest 3.000000;
BA_ "GenSigInvalidValue" SG_ 688 ESP_BrakeLightOnRequest "3";
BA_ "GenSigCycleTime" SG_ 688 EMS_EngineStatus 50;
BA_ "GenSigStartValue" SG_ 688 EMS_EngineStatus 3.000000;
BA_ "GenSigInvalidValue" SG_ 688 EMS_EngineStatus "3";
BA_ "GenSigCycleTime" SG_ 688 EMS_BrakePedalStatus 50;
BA_ "GenSigStartValue" SG_ 688 EMS_BrakePedalStatus 3.000000;
BA_ "GenSigInvalidValue" SG_ 688 EMS_BrakePedalStatus "3";

BA_ "GenSigCycleTime" SG_ 800 EMS_EngineSpeed 100;
BA_ "GenSigStartValue" SG_ 800 EMS_EngineSpeed 65535.000000;
BA_ "GenSigInvalidValue" SG_ 800 EMS_EngineSpeed "65535";
BA_ "GenSigCycleTime" SG_ 800 EPB_FailureLamp 100;
BA_ "GenSigInvalidValue" SG_ 800 EPB_FailureLamp "3";
BA_ "GenSigCycleTime" SG_ 800 EMS_EngineSpeedError 100;
BA_ "GenSigInvalidValue" SG_ 800 EMS_EngineSpeedError "1";
BA_ "GenSigCycleTime" SG_ 800 SAS_SASFailure 100;
BA_ "GenSigInvalidValue" SG_ 800 SAS_SASFailure "1";
BA_ "GenSigCycleTime" SG_ 800 ESP_ABSFailStatus 100;
BA_ "GenSigStartValue" SG_ 800 ESP_ABSFailStatus 1.000000;
BA_ "GenSigInvalidValue" SG_ 800 ESP_ABSFailStatus "1";
BA_ "GenSigCycleTime" SG_ 800 ESP_TCSFailStatus 100;
BA_ "GenSigStartValue" SG_ 800 ESP_TCSFailStatus 1.000000;
BA_ "GenSigInvalidValue" SG_ 800 ESP_TCSFailStatus "1";
BA_ "GenSigCycleTime" SG_ 800 EMS_CoolanTemperatureError 100;
BA_ "GenSigInvalidValue" SG_ 800 EMS_CoolanTemperatureError "1";
BA_ "GenSigCycleTime" SG_ 800 EMS_MIL 100;
BA_ "GenSigStartValue" SG_ 800 EMS_MIL 1.000000;
BA_ "GenSigInvalidValue" SG_ 800 EMS_MIL "3";
BA_ "GenSigCycleTime" SG_ 800 SRS_WarningLampStatus 100;
BA_ "GenSigStartValue" SG_ 800 SRS_WarningLampStatus 1.000000;
BA_ "GenSigInvalidValue" SG_ 800 SRS_WarningLampStatus "1";
BA_ "GenSigCycleTime" SG_ 800 SRS_PassengerBuckleSwitchStatus 100;
BA_ "GenSigStartValue" SG_ 800 SRS_PassengerBuckleSwitchStatus 3.000000;
BA_ "GenSigInvalidValue" SG_ 800 SRS_PassengerBuckleSwitchStatus "3";
BA_ "GenSigCycleTime" SG_ 800 SRS_DriverBuckleSwitchStatus 100;
BA_ "GenSigStartValue" SG_ 800 SRS_DriverBuckleSwitchStatus 3.000000;
BA_ "GenSigInvalidValue" SG_ 800 SRS_DriverBuckleSwitchStatus "3";
BA_ "GenSigCycleTime" SG_ 800 ESP_VehicleSpeed 100;
BA_ "GenSigStartValue" SG_ 800 ESP_VehicleSpeed 8191.000000;
BA_ "GenSigInvalidValue" SG_ 800 ESP_VehicleSpeed "8191";
BA_ "GenSigCycleTime" SG_ 800 ESP_VehicleSpeedValid 100;
BA_ "GenSigStartValue" SG_ 800 ESP_VehicleSpeedValid 1.000000;
BA_ "GenSigInvalidValue" SG_ 800 ESP_VehicleSpeedValid "1";
BA_ "GenSigCycleTime" SG_ 800 EMS_EngineCoolanTemperature 100;
BA_ "GenSigStartValue" SG_ 800 EMS_EngineCoolanTemperature 255.000000;
BA_ "GenSigInvalidValue" SG_ 800 EMS_EngineCoolanTemperature "255";

BA_ "GenSigCycleTime" SG_ 806 EMS_TargetCruiseSpeed 100;
BA_ "GenSigStartValue" SG_ 806 EMS_TargetCruiseSpeed 255.000000;
BA_ "GenSigInvalidValue" SG_ 806 EMS_TargetCruiseSpeed "255";
BA_ "GenSigCycleTime" SG_ 806 EMS_TotalOdometer 100;
BA_ "GenSigStartValue" SG_ 806 EMS_TotalOdometer 16777215.000000;
BA_ "GenSigInvalidValue" SG_ 806 EMS_TotalOdometer "16777215";
BA_ "GenSigCycleTime" SG_ 806 EMS_BatteryVoltage 100;
BA_ "GenSigStartValue" SG_ 806 EMS_BatteryVoltage 100.000000;
BA_ "GenSigInvalidValue" SG_ 806 EMS_BatteryVoltage "255";
BA_ "GenSigCycleTime" SG_ 806 EMS_FuelConsumption 100;
BA_ "GenSigInvalidValue" SG_ 806 EMS_FuelConsumption "255";
BA_ "GenSigCycleTime" SG_ 806 EMS_SSMWarningLampCtrol 100;
BA_ "GenSigInvalidValue" SG_ 806 EMS_SSMWarningLampCtrol "0";
BA_ "GenSigCycleTime" SG_ 806 EMS_CruiseUnavailDisplay 100;
BA_ "GenSigInvalidValue" SG_ 806 EMS_CruiseUnavailDisplay "0";
BA_ "GenSigCycleTime" SG_ 806 EMS_IdleStopStatus 100;
BA_ "GenSigInvalidValue" SG_ 806 EMS_IdleStopStatus "0";
BA_ "GenSigCycleTime" SG_ 806 EMS_CruiseIndicate 100;
BA_ "GenSigInvalidValue" SG_ 806 EMS_CruiseIndicate "0";
BA_ "GenSigCycleTime" SG_ 806 EMS_CruiseControlStatus 100;
BA_ "GenSigInvalidValue" SG_ 806 EMS_CruiseControlStatus "3";
BA_ "GenSigCycleTime" SG_ 806 EMS_CruiseActiveIndicate 100;
BA_ "GenSigInvalidValue" SG_ 806 EMS_CruiseActiveIndicate "0";

BA_ "GenSigCycleTime" SG_ 810 EMS_RemindGear 100;
BA_ "GenSigInvalidValue" SG_ 810 EMS_RemindGear "7";
BA_ "GenSigCycleTime" SG_ 810 ESP_HBBFunctionStatus 100;
BA_ "GenSigStartValue" SG_ 810 ESP_HBBFunctionStatus 3.000000;
BA_ "GenSigInvalidValue" SG_ 810 ESP_HBBFunctionStatus "3";
BA_ "GenSigCycleTime" SG_ 810 EMS_RemindShiftGear 100;
BA_ "GenSigInvalidValue" SG_ 810 EMS_RemindShiftGear "3";
BA_ "GenSigCycleTime" SG_ 810 ESP_AutoHoldAvailable 100;
BA_ "GenSigInvalidValue" SG_ 810 ESP_AutoHoldAvailable "0";
BA_ "GenSigCycleTime" SG_ 810 ESP_HHC_Active 100;
BA_ "GenSigInvalidValue" SG_ 810 ESP_HHC_Active "0";
BA_ "GenSigCycleTime" SG_ 810 ESP_AutoHoldActive 100;
BA_ "GenSigInvalidValue" SG_ 810 ESP_AutoHoldActive "0";
BA_ "GenSigCycleTime" SG_ 810 ESP_HHC_Available 100;
BA_ "GenSigInvalidValue" SG_ 810 ESP_HHC_Available "0";
BA_ "GenSigCycleTime" SG_ 810 TCU_GearForDisplay 100;
BA_ "GenSigInvalidValue" SG_ 810 TCU_GearForDisplay "15";
BA_ "GenSigCycleTime" SG_ 810 ESP_HDC_STATUS 100;
BA_ "GenSigStartValue" SG_ 810 ESP_HDC_STATUS 3.000000;
BA_ "GenSigInvalidValue" SG_ 810 ESP_HDC_STATUS "3";
BA_ "GenSigCycleTime" SG_ 810 EPB_FunctionLamp 100;
BA_ "GenSigInvalidValue" SG_ 810 EPB_FunctionLamp "3";
BA_ "GenSigCycleTime" SG_ 810 EPB_SwitchPosition 100;
BA_ "GenSigInvalidValue" SG_ 810 EPB_SwitchPosition "3";
BA_ "GenSigCycleTime" SG_ 810 EPB_SwitchPositionValid 100;
BA_ "GenSigStartValue" SG_ 810 EPB_SwitchPositionValid 1.000000;
BA_ "GenSigInvalidValue" SG_ 810 EPB_SwitchPositionValid "1";
BA_ "GenSigCycleTime" SG_ 810 EPB_TextDisplay 100;
BA_ "GenSigInvalidValue" SG_ 810 EPB_TextDisplay "15";
BA_ "GenSigCycleTime" SG_ 810 ESP_ESPActiveStatus 100;
BA_ "GenSigInvalidValue" SG_ 810 ESP_ESPActiveStatus "0";
BA_ "GenSigCycleTime" SG_ 810 EPS_EPSFailed 100;
BA_ "GenSigInvalidValue" SG_ 810 EPS_EPSFailed "1";
BA_ "GenSigCycleTime" SG_ 810 ESP_ESPFunctionStatus 100;
BA_ "GenSigInvalidValue" SG_ 810 ESP_ESPFunctionStatus "1";
BA_ "GenSigCycleTime" SG_ 810 ESP_EBDFailStatus 100;
BA_ "GenSigInvalidValue" SG_ 810 ESP_EBDFailStatus "1";
BA_ "GenSigCycleTime" SG_ 810 ACC_ACCMode 100;
BA_ "GenSigInvalidValue" SG_ 810 ACC_ACCMode "7";
BA_ "GenSigCycleTime" SG_ 810 AT_FailureLamp 100;
BA_ "GenSigInvalidValue" SG_ 810 AT_FailureLamp "0";

BA_ "GenSigCycleTime" SG_ 883 EMS_AccPedal 300;
BA_ "GenSigStartValue" SG_ 883 EMS_AccPedal 255.000000;
BA_ "GenSigInvalidValue" SG_ 883 EMS_AccPedal "255";
BA_ "GenSigCycleTime" SG_ 883 EMS_EngineThrottlePosition 300;
BA_ "GenSigInvalidValue" SG_ 883 EMS_EngineThrottlePosition "255";
BA_ "GenSigCycleTime" SG_ 883 EMS_IndicatedRealEngTorq 300;
BA_ "GenSigInvalidValue" SG_ 883 EMS_IndicatedRealEngTorq "65535";
BA_ "GenSigCycleTime" SG_ 883 EMS_IndicatedDriverReqTorq 300;
BA_ "GenSigInvalidValue" SG_ 883 EMS_IndicatedDriverReqTorq "65535";

BA_ "GenSigCycleTime" SG_ 839 BCM_TirePresureSignalStatus 500;
BA_ "GenSigStartValue" SG_ 839 BCM_TirePresureSignalStatus 1.000000;
BA_ "GenSigInvalidValue" SG_ 839 BCM_TirePresureSignalStatus "NA";
BA_ "GenSigCycleTime" SG_ 839 TPMS_SystemFailureWarning 500;
BA_ "GenSigInvalidValue" SG_ 839 TPMS_SystemFailureWarning "NA";
BA_ "GenSigCycleTime" SG_ 839 TPMS_LRPressureWarning 500;
BA_ "GenSigInvalidValue" SG_ 839 TPMS_LRPressureWarning "NA";
BA_ "GenSigCycleTime" SG_ 839 TPMS_RRPressureWarning 500;
BA_ "GenSigInvalidValue" SG_ 839 TPMS_RRPressureWarning "NA";
BA_ "GenSigCycleTime" SG_ 839 TPMS_RFPressureWarning 500;
BA_ "GenSigInvalidValue" SG_ 839 TPMS_RFPressureWarning "NA";
BA_ "GenSigCycleTime" SG_ 839 TPMS_LFPressureWarning 500;
BA_ "GenSigInvalidValue" SG_ 839 TPMS_LFPressureWarning "NA";
BA_ "GenSigCycleTime" SG_ 839 TPMS_TireTemperature 500;
BA_ "GenSigStartValue" SG_ 839 TPMS_TireTemperature 40.000000;
BA_ "GenSigInvalidValue" SG_ 839 TPMS_TireTemperature "255";
BA_ "GenSigCycleTime" SG_ 839 TPMS_LRTyrePressure 500;
BA_ "GenSigInvalidValue" SG_ 839 TPMS_LRTyrePressure "255";
BA_ "GenSigCycleTime" SG_ 839 TPMS_RRTyrePressure 500;
BA_ "GenSigInvalidValue" SG_ 839 TPMS_RRTyrePressure "255";
BA_ "GenSigCycleTime" SG_ 839 TPMS_RFTyrePressure 500;
BA_ "GenSigInvalidValue" SG_ 839 TPMS_RFTyrePressure "255";
BA_ "GenSigCycleTime" SG_ 839 TPMS_LFTyrePressure 500;
BA_ "GenSigInvalidValue" SG_ 839 TPMS_LFTyrePressure "255";
BA_ "GenSigCycleTime" SG_ 839 TPMS_TirePosition 500;
BA_ "GenSigInvalidValue" SG_ 839 TPMS_TirePosition "NA";
BA_ "GenSigCycleTime" SG_ 839 TPMS_LRTemperatureWarning 500;
BA_ "GenSigInvalidValue" SG_ 839 TPMS_LRTemperatureWarning "NA";
BA_ "GenSigCycleTime" SG_ 839 TPMS_RRTemperatureWarning 500;
BA_ "GenSigInvalidValue" SG_ 839 TPMS_RRTemperatureWarning "NA";
BA_ "GenSigCycleTime" SG_ 839 TPMS_RFTemperatureWarning 500;
BA_ "GenSigInvalidValue" SG_ 839 TPMS_RFTemperatureWarning "NA";
BA_ "GenSigCycleTime" SG_ 839 TPMS_LFTemperatureWarning 500;
BA_ "GenSigInvalidValue" SG_ 839 TPMS_LFTemperatureWarning "NA";
BA_ "GenSigCycleTime" SG_ 839 TPMS_SignalStatus 500;
BA_ "GenSigStartValue" SG_ 839 TPMS_SignalStatus 1.000000;
BA_ "GenSigInvalidValue" SG_ 839 TPMS_SignalStatus "NA";
BA_ "GenSigCycleTime" SG_ 839 BCM_TirePresureSignalStatus 500;
BA_ "GenSigStartValue" SG_ 839 BCM_TirePresureSignalStatus 1.000000;
BA_ "GenSigInvalidValue" SG_ 839 BCM_TirePresureSignalStatus "NA";

BA_ "GenSigCycleTime" SG_ 886 SAS_SteeringAngleSpeed 300;
BA_ "GenSigInvalidValue" SG_ 886 SAS_SteeringAngleSpeed "255";
BA_ "GenSigCycleTime" SG_ 886 EMS_EngineFuelCutOff 300;
BA_ "GenSigInvalidValue" SG_ 886 EMS_EngineFuelCutOff "LastValue";
BA_ "GenSigCycleTime" SG_ 886 EMS_ClutchPedalStatus 300;
BA_ "GenSigInvalidValue" SG_ 886 EMS_ClutchPedalStatus "2";
BA_ "GenSigCycleTime" SG_ 886 EMS_ConditionIdle 300;
BA_ "GenSigInvalidValue" SG_ 886 EMS_ConditionIdle "LastValue";
BA_ "GenSigCycleTime" SG_ 886 EMS_FrictionalTorq 300;
BA_ "GenSigInvalidValue" SG_ 886 EMS_FrictionalTorq "65535";
BA_ "GenSigCycleTime" SG_ 886 EMS_TorqueConstant 300;
BA_ "GenSigInvalidValue" SG_ 886 EMS_TorqueConstant "255";

BA_ "GenSigCycleTime" SG_ 900 BCM_LightSensor 200;
BA_ "GenSigInvalidValue" SG_ 900 BCM_LightSensor "NA";
BA_ "GenSigCycleTime" SG_ 900 BCM_LockSignal 200;
BA_ "GenSigInvalidValue" SG_ 900 BCM_LockSignal "3";
BA_ "GenSigCycleTime" SG_ 900 BCM_UnlockSignal 200;
BA_ "GenSigInvalidValue" SG_ 900 BCM_UnlockSignal "3";
BA_ "GenSigCycleTime" SG_ 900 BCM_RemoteWindowDownSignal 200;
BA_ "GenSigInvalidValue" SG_ 900 BCM_RemoteWindowDownSignal "NA";
BA_ "GenSigCycleTime" SG_ 900 BCM_RmoteUnLockFeedback 200;
BA_ "GenSigInvalidValue" SG_ 900 BCM_RmoteUnLockFeedback "NA";
BA_ "GenSigCycleTime" SG_ 900 BCM_RmoteLockeFeedback 200;
BA_ "GenSigInvalidValue" SG_ 900 BCM_RmoteLockeFeedback "NA";
BA_ "GenSigCycleTime" SG_ 900 BCM_CarRemindFeedback 200;
BA_ "GenSigInvalidValue" SG_ 900 BCM_CarRemindFeedback "3";
BA_ "GenSigCycleTime" SG_ 900 BCM_RightRearWindowStatus 200;
BA_ "GenSigInvalidValue" SG_ 900 BCM_RightRearWindowStatus "0";
BA_ "GenSigCycleTime" SG_ 900 BCM_LeftRearWindowStatus 200;
BA_ "GenSigInvalidValue" SG_ 900 BCM_LeftRearWindowStatus "0";
BA_ "GenSigCycleTime" SG_ 900 BCM_PassengerWindowStatus 200;
BA_ "GenSigInvalidValue" SG_ 900 BCM_PassengerWindowStatus "0";
BA_ "GenSigCycleTime" SG_ 900 BCM_DriverWindowStatus 200;
BA_ "GenSigInvalidValue" SG_ 900 BCM_DriverWindowStatus "0";
BA_ "GenSigCycleTime" SG_ 900 BCM_LockSignal 200;
BA_ "GenSigInvalidValue" SG_ 900 BCM_LockSignal "3";
BA_ "GenSigCycleTime" SG_ 900 BCM_UnlockSignal 200;
BA_ "GenSigInvalidValue" SG_ 900 BCM_UnlockSignal "3";

BA_ "GenSigCycleTime" SG_ 630 ESCL_SteeringLockError 40;
BA_ "GenSigInvalidValue" SG_ 630 ESCL_SteeringLockError "NA";
BA_ "GenSigCycleTime" SG_ 630 ESCL_SteeringLockStuck 40;
BA_ "GenSigInvalidValue" SG_ 630 ESCL_SteeringLockStuck "NA";
BA_ "GenSigCycleTime" SG_ 630 ESCL_SteeringLockWait 40;
BA_ "GenSigInvalidValue" SG_ 630 ESCL_SteeringLockWait "NA";
BA_ "GenSigCycleTime" SG_ 630 ESCL_SteeringLockStatusS301 40;
BA_ "GenSigInvalidValue" SG_ 630 ESCL_SteeringLockStatusS301 "NA";
BA_ "GenSigCycleTime" SG_ 630 ESCL_SteeringLockStatusReserve 40;
BA_ "GenSigInvalidValue" SG_ 630 ESCL_SteeringLockStatusReserve "NA";

BA_ "GenSigCycleTime" SG_ 728 LAS_CheckSum 20;
BA_ "GenSigInvalidValue" SG_ 728 LAS_CheckSum "NA";
BA_ "GenSigCycleTime" SG_ 728 LAS_AliveCounter 20;
BA_ "GenSigInvalidValue" SG_ 728 LAS_AliveCounter "NA";
BA_ "GenSigCycleTime" SG_ 728 LAS_HMALightDistribution 20;
BA_ "GenSigInvalidValue" SG_ 728 LAS_HMALightDistribution "0";
BA_ "GenSigCycleTime" SG_ 728 LAS_HMAStatus 20;
BA_ "GenSigInvalidValue" SG_ 728 LAS_HMAStatus "3";
BA_ "GenSigCycleTime" SG_ 728 LAS_SLASpdLimitUnits 20;
BA_ "GenSigInvalidValue" SG_ 728 LAS_SLASpdLimitUnits "0";
BA_ "GenSigCycleTime" SG_ 728 LAS_SLASpdLimit 20;
BA_ "GenSigInvalidValue" SG_ 728 LAS_SLASpdLimit "254";
BA_ "GenSigCycleTime" SG_ 728 LAS_SLAState 20;
BA_ "GenSigInvalidValue" SG_ 728 LAS_SLAState "7";
BA_ "GenSigCycleTime" SG_ 728 LAS_LKSStatus 20;
BA_ "GenSigInvalidValue" SG_ 728 LAS_LKSStatus "7";
BA_ "GenSigCycleTime" SG_ 728 LAS_CalibrationStatus 20;
BA_ "GenSigInvalidValue" SG_ 728 LAS_CalibrationStatus "3";
BA_ "GenSigCycleTime" SG_ 728 LAS_LDWReminder 20;
BA_ "GenSigInvalidValue" SG_ 728 LAS_LDWReminder "0";
BA_ "GenSigCycleTime" SG_ 728 LAS_LASFailure 20;
BA_ "GenSigInvalidValue" SG_ 728 LAS_LASFailure "3";
BA_ "GenSigCycleTime" SG_ 728 LAS_SteeringTorqueReq 20;
BA_ "GenSigInvalidValue" SG_ 728 LAS_SteeringTorqueReq "2047";
BA_ "GenSigCycleTime" SG_ 728 LAS_TakeoverReq 20;
BA_ "GenSigInvalidValue" SG_ 728 LAS_TakeoverReq "0";
BA_ "GenSigCycleTime" SG_ 728 LAS_LDWStatus 20;
BA_ "GenSigInvalidValue" SG_ 728 LAS_LDWStatus "3";
BA_ "GenSigCycleTime" SG_ 728 LDW_VibrationWarning 20;
BA_ "GenSigInvalidValue" SG_ 728 LDW_VibrationWarning "3";

BA_ "GenSigCycleTime" SG_ 736 RRS_SystemFailureFlag 100;
BA_ "GenSigInvalidValue" SG_ 736 RRS_SystemFailureFlag "NA";
BA_ "GenSigCycleTime" SG_ 736 RRS_WarningFrequency 100;
BA_ "GenSigInvalidValue" SG_ 736 RRS_WarningFrequency "NA";
BA_ "GenSigCycleTime" SG_ 736 RRS_WarningType 100;
BA_ "GenSigInvalidValue" SG_ 736 RRS_WarningType "NA";
BA_ "GenSigCycleTime" SG_ 736 RRS_SwitchIndicatorError 100;
BA_ "GenSigInvalidValue" SG_ 736 RRS_SwitchIndicatorError "NA";
BA_ "GenSigCycleTime" SG_ 736 RRS_SpkErrFlag 100;
BA_ "GenSigInvalidValue" SG_ 736 RRS_SpkErrFlag "NA";
BA_ "GenSigCycleTime" SG_ 736 RRS_ctrlModulErrFlag 100;
BA_ "GenSigInvalidValue" SG_ 736 RRS_ctrlModulErrFlag "NA";
BA_ "GenSigCycleTime" SG_ 736 RRS_BattVoltErrFlag 100;
BA_ "GenSigInvalidValue" SG_ 736 RRS_BattVoltErrFlag "NA";
BA_ "GenSigCycleTime" SG_ 736 RRS_RFMSnsErrFlag 100;
BA_ "GenSigInvalidValue" SG_ 736 RRS_RFMSnsErrFlag "NA";
BA_ "GenSigCycleTime" SG_ 736 RRS_LFMSnsErrFlag 100;
BA_ "GenSigInvalidValue" SG_ 736 RRS_LFMSnsErrFlag "NA";
BA_ "GenSigCycleTime" SG_ 736 RRS_RRMidSnsErrFlag 100;
BA_ "GenSigInvalidValue" SG_ 736 RRS_RRMidSnsErrFlag "NA";
BA_ "GenSigCycleTime" SG_ 736 RRS_LRMidSnsErrFlag 100;
BA_ "GenSigInvalidValue" SG_ 736 RRS_LRMidSnsErrFlag "NA";
BA_ "GenSigCycleTime" SG_ 736 RRS_RRCSnsErrFlag 100;
BA_ "GenSigInvalidValue" SG_ 736 RRS_RRCSnsErrFlag "NA";
BA_ "GenSigCycleTime" SG_ 736 RRS_LRCSnsErrFlag 100;
BA_ "GenSigInvalidValue" SG_ 736 RRS_LRCSnsErrFlag "NA";
BA_ "GenSigCycleTime" SG_ 736 RRS_RFCSnsErrFlag 100;
BA_ "GenSigInvalidValue" SG_ 736 RRS_RFCSnsErrFlag "NA";
BA_ "GenSigCycleTime" SG_ 736 RRS_LFCSnsErrFlag 100;
BA_ "GenSigInvalidValue" SG_ 736 RRS_LFCSnsErrFlag "NA";
BA_ "GenSigCycleTime" SG_ 736 RRS_RFMDistance 100;
BA_ "GenSigInvalidValue" SG_ 736 RRS_RFMDistance "15";
BA_ "GenSigCycleTime" SG_ 736 RRS_LFMDistance 100;
BA_ "GenSigInvalidValue" SG_ 736 RRS_LFMDistance "15";
BA_ "GenSigCycleTime" SG_ 736 RRS_LFCDistance 100;
BA_ "GenSigInvalidValue" SG_ 736 RRS_LFCDistance "15";
BA_ "GenSigCycleTime" SG_ 736 RRS_RFCDistance 100;
BA_ "GenSigInvalidValue" SG_ 736 RRS_RFCDistance "15";
BA_ "GenSigCycleTime" SG_ 736 RRS_LRCDistance 100;
BA_ "GenSigInvalidValue" SG_ 736 RRS_LRCDistance "15";
BA_ "GenSigCycleTime" SG_ 736 RRS_RRCDistance 100;
BA_ "GenSigInvalidValue" SG_ 736 RRS_RRCDistance "15";
BA_ "GenSigCycleTime" SG_ 736 RRS_LRMDistance 100;
BA_ "GenSigInvalidValue" SG_ 736 RRS_LRMDistance "15";
BA_ "GenSigCycleTime" SG_ 736 RRS_RRMDistance 100;
BA_ "GenSigInvalidValue" SG_ 736 RRS_RRMDistance "15";

BA_ "GenSigCycleTime" SG_ 608 IP_DTE 40;
BA_ "GenSigInvalidValue" SG_ 608 IP_DTE "1023";

BA_ "GenSigCycleTime" SG_ 729 LAS_CheckSum_idxxE 100;
BA_ "GenSigInvalidValue" SG_ 729 LAS_CheckSum_idxxE "NA";
BA_ "GenSigCycleTime" SG_ 729 LAS_RollingCounter_idxxE 100;
BA_ "GenSigInvalidValue" SG_ 729 LAS_RollingCounter_idxxE "NA";
BA_ "GenSigCycleTime" SG_ 729 LDW_VoiceWarning 100;
BA_ "GenSigInvalidValue" SG_ 729 LDW_VoiceWarning "3";
BA_ "GenSigCycleTime" SG_ 729 LAS_OverspeedSoundWarning 100;
BA_ "GenSigInvalidValue" SG_ 729 LAS_OverspeedSoundWarning "3";
BA_ "GenSigCycleTime" SG_ 729 LAS_OverspeedVisualWarning 100;
BA_ "GenSigInvalidValue" SG_ 729 LAS_OverspeedVisualWarning "3";
BA_ "GenSigCycleTime" SG_ 729 LAS_OverspeedWarningOffset 100;
BA_ "GenSigStartValue" SG_ 729 LAS_OverspeedWarningOffset 10.000000;
BA_ "GenSigInvalidValue" SG_ 729 LAS_OverspeedWarningOffset "31";
BA_ "GenSigCycleTime" SG_ 729 LAS_OverspeedWarningEnableStatus 100;
BA_ "GenSigStartValue" SG_ 729 LAS_OverspeedWarningEnableStatus 2.000000;
BA_ "GenSigInvalidValue" SG_ 729 LAS_OverspeedWarningEnableStatus "3";
BA_ "GenSigCycleTime" SG_ 729 LAS_RLaneMarkerType 100;
BA_ "GenSigStartValue" SG_ 729 LAS_RLaneMarkerType 1.000000;
BA_ "GenSigInvalidValue" SG_ 729 LAS_RLaneMarkerType "7";
BA_ "GenSigCycleTime" SG_ 729 LAS_LLaneMarkerType 100;
BA_ "GenSigStartValue" SG_ 729 LAS_LLaneMarkerType 1.000000;
BA_ "GenSigInvalidValue" SG_ 729 LAS_LLaneMarkerType "7";
BA_ "GenSigCycleTime" SG_ 729 LAS_HostLaneRightStatus 100;
BA_ "GenSigInvalidValue" SG_ 729 LAS_HostLaneRightStatus "0";
BA_ "GenSigCycleTime" SG_ 729 LAS_HostLaneLeftStatus 100;
BA_ "GenSigInvalidValue" SG_ 729 LAS_HostLaneLeftStatus "0";
BA_ "GenSigCycleTime" SG_ 729 LAS_OverspeedSoundWarnEnaSts 100;
BA_ "GenSigStartValue" SG_ 729 LAS_OverspeedSoundWarnEnaSts 1.000000;
BA_ "GenSigInvalidValue" SG_ 729 LAS_OverspeedSoundWarnEnaSts "0";
BA_ "GenSigCycleTime" SG_ 729 LAS_LDWShakeLevStatus 100;
BA_ "GenSigInvalidValue" SG_ 729 LAS_LDWShakeLevStatus "0";
BA_ "GenSigCycleTime" SG_ 729 LAS_LASWarningModeSelectStas 100;
BA_ "GenSigStartValue" SG_ 729 LAS_LASWarningModeSelectStas 3.000000;
BA_ "GenSigInvalidValue" SG_ 729 LAS_LASWarningModeSelectStas "0";
BA_ "GenSigCycleTime" SG_ 729 LAS_SLASwitchStatus 100;
BA_ "GenSigStartValue" SG_ 729 LAS_SLASwitchStatus 1.000000;
BA_ "GenSigInvalidValue" SG_ 729 LAS_SLASwitchStatus "0";
BA_ "GenSigCycleTime" SG_ 729 LAS_HMAEnableStatus 100;
BA_ "GenSigStartValue" SG_ 729 LAS_HMAEnableStatus 1.000000;
BA_ "GenSigInvalidValue" SG_ 729 LAS_HMAEnableStatus "0";
BA_ "GenSigCycleTime" SG_ 729 LAS_LASModeSelectionStatus 100;
BA_ "GenSigStartValue" SG_ 729 LAS_LASModeSelectionStatus 5.000000;
BA_ "GenSigInvalidValue" SG_ 729 LAS_LASModeSelectionStatus "0";
BA_ "GenSigCycleTime" SG_ 729 LAS_LdwSensitivityStatus 100;
BA_ "GenSigInvalidValue" SG_ 729 LAS_LdwSensitivityStatus "3";

BA_ "GenSigCycleTime" SG_ 862 ACC_CheckSum_id35E 100;
BA_ "GenSigInvalidValue" SG_ 862 ACC_CheckSum_id35E "NA";
BA_ "GenSigCycleTime" SG_ 862 ACC_RollingCounter_id35E 100;
BA_ "GenSigInvalidValue" SG_ 862 ACC_RollingCounter_id35E "NA";
BA_ "GenSigCycleTime" SG_ 862 ACC_CruiseControlSetStatus 100;
BA_ "GenSigStartValue" SG_ 862 ACC_CruiseControlSetStatus 1.000000;
BA_ "GenSigInvalidValue" SG_ 862 ACC_CruiseControlSetStatus "0";
BA_ "GenSigCycleTime" SG_ 862 ACC_DistanceAlertEnableStatus 100;
BA_ "GenSigStartValue" SG_ 862 ACC_DistanceAlertEnableStatus 1.000000;
BA_ "GenSigInvalidValue" SG_ 862 ACC_DistanceAlertEnableStatus "0";
BA_ "GenSigCycleTime" SG_ 862 ACC_ACCObjEnableStatus 100;
BA_ "GenSigInvalidValue" SG_ 862 ACC_ACCObjEnableStatus "0";
BA_ "GenSigCycleTime" SG_ 862 ACC_FCWSensitivityStatus 100;
BA_ "GenSigStartValue" SG_ 862 ACC_FCWSensitivityStatus 1.000000;
BA_ "GenSigInvalidValue" SG_ 862 ACC_FCWSensitivityStatus "1";
BA_ "GenSigCycleTime" SG_ 862 ACC_AutoBrakeEnableStatus 100;
BA_ "GenSigStartValue" SG_ 862 ACC_AutoBrakeEnableStatus 1.000000;
BA_ "GenSigInvalidValue" SG_ 862 ACC_AutoBrakeEnableStatus "0";
BA_ "GenSigCycleTime" SG_ 862 ACC_FCWEnableStatus 100;
BA_ "GenSigStartValue" SG_ 862 ACC_FCWEnableStatus 1.000000;
BA_ "GenSigInvalidValue" SG_ 862 ACC_FCWEnableStatus "0";
BA_ "GenSigCycleTime" SG_ 862 ACC_ACCFailInfo 100;
BA_ "GenSigInvalidValue" SG_ 862 ACC_ACCFailInfo "NA";
BA_ "GenSigCycleTime" SG_ 862 ACC_TakeOverReq 100;
BA_ "GenSigInvalidValue" SG_ 862 ACC_TakeOverReq "NA";
BA_ "GenSigCycleTime" SG_ 862 ACC_ObjValid 100;
BA_ "GenSigInvalidValue" SG_ 862 ACC_ObjValid "NA";
BA_ "GenSigCycleTime" SG_ 862 ACC_TimeGapSet 100;
BA_ "GenSigInvalidValue" SG_ 862 ACC_TimeGapSet "NA";
BA_ "GenSigCycleTime" SG_ 862 ACC_DistanceTarObj 100;
BA_ "GenSigInvalidValue" SG_ 862 ACC_DistanceTarObj "NA";
BA_ "GenSigCycleTime" SG_ 862 ACC_SetSpeedDis 100;
BA_ "GenSigInvalidValue" SG_ 862 ACC_SetSpeedDis "255";

BA_ "GenSigCycleTime" SG_ 992 AVM_OverspeedWarning 50;
BA_ "GenSigInvalidValue" SG_ 992 AVM_OverspeedWarning "0";
BA_ "GenSigCycleTime" SG_ 992 AVM_VisionAngle 50;
BA_ "GenSigInvalidValue" SG_ 992 AVM_VisionAngle "3";
BA_ "GenSigCycleTime" SG_ 992 AVM_DisplayForm 50;
BA_ "GenSigInvalidValue" SG_ 992 AVM_DisplayForm "10";
BA_ "GenSigCycleTime" SG_ 992 AVM_LineOnOff 50;
BA_ "GenSigInvalidValue" SG_ 992 AVM_LineOnOff "3";
BA_ "GenSigCycleTime" SG_ 992 AVM_DisplayReq 50;
BA_ "GenSigInvalidValue" SG_ 992 AVM_DisplayReq "NA";

BA_ "GenSigCycleTime" SG_ 850 DSM_DSMMemoryPosition 100;
BA_ "GenSigInvalidValue" SG_ 850 DSM_DSMMemoryPosition "0";
BA_ "GenSigCycleTime" SG_ 850 DSM_MirrorSetStatus 100;
BA_ "GenSigInvalidValue" SG_ 850 DSM_MirrorSetStatus "NA";
BA_ "GenSigCycleTime" SG_ 850 DSM_KeyMomerySts 100;
BA_ "GenSigInvalidValue" SG_ 850 DSM_KeyMomerySts "NA";
BA_ "GenSigCycleTime" SG_ 850 DSM_MemoryAlarm 100;
BA_ "GenSigInvalidValue" SG_ 850 DSM_MemoryAlarm "NA";
BA_ "GenSigCycleTime" SG_ 850 DSM_MemoryPosition 100;
BA_ "GenSigInvalidValue" SG_ 850 DSM_MemoryPosition "NA";
BA_ "GenSigCycleTime" SG_ 850 DSM_EasyEntrySts 100;
BA_ "GenSigInvalidValue" SG_ 850 DSM_EasyEntrySts "NA";
BA_ "GenSigCycleTime" SG_ 850 DSM_GetMemoryReq 100;
BA_ "GenSigInvalidValue" SG_ 850 DSM_GetMemoryReq "NA";
BA_ "GenSigCycleTime" SG_ 850 DSM_SetMemoryReq 100;
BA_ "GenSigInvalidValue" SG_ 850 DSM_SetMemoryReq "NA";

BA_ "GenSigCycleTime" SG_ 890 GW_IDWarn2_CycletimeInsDet 200;
BA_ "GenSigInvalidValue" SG_ 890 GW_IDWarn2_CycletimeInsDet "NA";
BA_ "GenSigCycleTime" SG_ 890 GW_IDWarn1_WhitelistInsDet 200;
BA_ "GenSigInvalidValue" SG_ 890 GW_IDWarn1_WhitelistInsDet "NA";
BA_ "GenSigCycleTime" SG_ 890 GW_FirewallWarning 200;
BA_ "GenSigInvalidValue" SG_ 890 GW_FirewallWarning "NA";

BA_ "GenSigCycleTime" SG_ 1306 HU_LanguageSync 100;
BA_ "GenSigCycleTime" SG_ 1306 HU_ThemeChange 100;
BA_ "GenSigCycleTime" SG_ 1306 HU_VC_VR 100;
BA_ "GenSigCycleTime" SG_ 1306 HU_Seeoffanimation 100;
BA_ "GenSigInvalidValue" SG_ 1306 HU_Seeoffanimation "0";
BA_ "GenSigCycleTime" SG_ 1306 HU_APAActive 100;
BA_ "GenSigInvalidValue" SG_ 1306 HU_APAActive "NA";
BA_ "GenSigCycleTime" SG_ 1306 HU_SlotUserSelected 100;
BA_ "GenSigInvalidValue" SG_ 1306 HU_SlotUserSelected "15";
BA_ "GenSigCycleTime" SG_ 1306 HU_ScreenPowerOn 100;
BA_ "GenSigInvalidValue" SG_ 1306 HU_ScreenPowerOn "1";

BA_ "GenSigCycleTime" SG_ 808 LCM_LASSwitch 200;
BA_ "GenSigInvalidValue" SG_ 808 LCM_LASSwitch "0";

BA_ "GenSigCycleTime" SG_ 737 RFC_Sector_Dist 100;
BA_ "GenSigInvalidValue" SG_ 737 RFC_Sector_Dist "127";
BA_ "GenSigCycleTime" SG_ 737 LFC_Sector_Dist 100;
BA_ "GenSigInvalidValue" SG_ 737 LFC_Sector_Dist "127";
BA_ "GenSigCycleTime" SG_ 737 RRC_Sector_Dist 100;
BA_ "GenSigInvalidValue" SG_ 737 RRC_Sector_Dist "127";
BA_ "GenSigCycleTime" SG_ 737 LRC_Sector_Dist 100;
BA_ "GenSigInvalidValue" SG_ 737 LRC_Sector_Dist "127";
BA_ "GenSigCycleTime" SG_ 737 RRM_Sector_Dist 100;
BA_ "GenSigInvalidValue" SG_ 737 RRM_Sector_Dist "255";
BA_ "GenSigCycleTime" SG_ 737 LRM_Sector_Dist 100;
BA_ "GenSigInvalidValue" SG_ 737 LRM_Sector_Dist "255";

BA_ "GenSigCycleTime" SG_ 992 AVM_OverspeedWarning 50;
BA_ "GenSigInvalidValue" SG_ 992 AVM_OverspeedWarning "0";
BA_ "GenSigCycleTime" SG_ 992 AVM_VisionAngle 50;
BA_ "GenSigInvalidValue" SG_ 992 AVM_VisionAngle "3";
BA_ "GenSigCycleTime" SG_ 992 AVM_DisplayForm 50;
BA_ "GenSigInvalidValue" SG_ 992 AVM_DisplayForm "10";
BA_ "GenSigCycleTime" SG_ 992 AVM_LineOnOff 50;
BA_ "GenSigInvalidValue" SG_ 992 AVM_LineOnOff "3";
BA_ "GenSigCycleTime" SG_ 992 AVM_DisplayReq 50;
BA_ "GenSigInvalidValue" SG_ 992 AVM_DisplayReq "NA";

BA_ "GenSigCycleTime" SG_ 1299 HU_KeyRelevanceState 100;
BA_ "GenSigInvalidValue" SG_ 1299 HU_KeyRelevanceState "0";
BA_ "GenSigCycleTime" SG_ 1299 HU_UserSet 100;
BA_ "GenSigInvalidValue" SG_ 1299 HU_UserSet "NA";
BA_ "GenSigCycleTime" SG_ 1299 HU_VisionAngleReq 100;
BA_ "GenSigInvalidValue" SG_ 1299 HU_VisionAngleReq "3";
BA_ "GenSigCycleTime" SG_ 1299 HU_Ylevel 100;
BA_ "GenSigInvalidValue" SG_ 1299 HU_Ylevel "NA";
BA_ "GenSigCycleTime" SG_ 1299 HU_Xlevel 100;
BA_ "GenSigInvalidValue" SG_ 1299 HU_Xlevel "NA";

BA_ "GenSigCycleTime" SG_ 610 PEPS_WelcomeLightStaus 40;
BA_ "GenSigInvalidValue" SG_ 610 PEPS_WelcomeLightStaus "0";

BA_ "GenSigCycleTime" SG_ 901 IP_RearSeatbeltWarningEnableFB 50;
BA_ "GenSigInvalidValue" SG_ 901 IP_RearSeatbeltWarningEnableFB "0";
BA_ "GenSigCycleTime" SG_ 901 IP_WarningVolumeSettingFB 50;
BA_ "GenSigInvalidValue" SG_ 901 IP_WarningVolumeSettingFB "0";

BA_ "GenSigCycleTime" SG_ 957 HU_OutWelcomeSoundSet 100;
BA_ "GenSigCycleTime" SG_ 957 HU_ToneLowSet 100;
BA_ "GenSigCycleTime" SG_ 957 HU_ToneMiddleSet 100;
BA_ "GenSigCycleTime" SG_ 957 HU_ToneHighSet 100;
BA_ "GenSigCycleTime" SG_ 957 HU_BalanceYSet 100;
BA_ "GenSigCycleTime" SG_ 957 HU_BalanceXSet 100;
BA_ "GenSigCycleTime" SG_ 957 HU_EQModeSet 100;
BA_ "GenSigCycleTime" SG_ 957 HU_SoundFileTransferStatus 100;

BA_ "GenSigCycleTime" SG_ 958 AMP_MusicPlaySetBackSignal 100;
BA_ "GenSigStartValue" SG_ 958 AMP_MusicPlaySetBackSignal 1.000000;
BA_ "GenSigCycleTime" SG_ 958 HU_OutWelcomeSoundFeedback 100;
BA_ "GenSigCycleTime" SG_ 958 AMP_MuteFeedback 100;
BA_ "GenSigCycleTime" SG_ 958 AMP_EQModeFeedback 100;
BA_ "GenSigCycleTime" SG_ 958 AMP_SoundFileTransferFeedback 100;

VAL_ 839 BCM_TirePresureSignalStatus 0 "reliable signal" 1 "unreliable signal";
VAL_ 839 TPMS_SystemFailureWarning 0 "No any error" 1 "System error";
VAL_ 839 TPMS_LRPressureWarning 0 "No warning" 1 "High pressure warning" 2 "Low pressure warning" 3 "Quik leakage" 4 "Lost Sensor" 5 "Sensor battery low" 6 "Sensor failure" 7 "Reserved";
VAL_ 839 TPMS_RRPressureWarning 0 "No warning" 1 "High pressure warning" 2 "Low pressure warning" 3 "Quik leakage" 4 "Lost Sensor" 5 "Sensor battery low" 6 "Sensor failure" 7 "Reserved";
VAL_ 839 TPMS_RFPressureWarning 0 "No warning" 1 "High pressure warning" 2 "Low pressure warning" 3 "Quik leakage" 4 "Lost Sensor" 5 "Sensor battery low" 6 "Sensor failure" 7 "Reserved";
VAL_ 839 TPMS_LFPressureWarning 0 "No warning" 1 "High pressure warning" 2 "Low pressure warning" 3 "Quik leakage" 4 "Lost Sensor" 5 "Sensor battery low" 6 "Sensor failure" 7 "Reserved";
VAL_ 839 TPMS_TirePosition 0 "No any sensor" 1 "Left Front tire" 2 "Right Front tire" 3 "Right Rear tire" 4 "Left Rear tire" 5 "reseved";
VAL_ 839 TPMS_LRTemperatureWarning 0 "No temperature warning" 1 "Temperature warning";
VAL_ 839 TPMS_RRTemperatureWarning 0 "No temperature warning" 1 "Temperature warning";
VAL_ 839 TPMS_RFTemperatureWarning 0 "No temperature warning" 1 "Temperature warning";
VAL_ 839 TPMS_LFTemperatureWarning 0 "No temperature warning" 1 "Temperature warning";
VAL_ 839 TPMS_SignalStatus 0 "Current Signal" 1 "Last Signal";
VAL_ 839 BCM_TirePresureSignalStatus 0 "reliable signal" 1 "unreliable signal";

VAL_ 896 IP_EngineOffTime 0 "0-65533s" 65534 "65534 or >65534" 65535 "invalid";
VAL_ 896 IP_FuelLevel 0 "FUEIL≤E" 1 "E < FUEIL ≤1/8" 2 "1/8< FUEIL ≤1/4" 3 "1/4< FUEIL ≤3/8" 4 "3/8< FUEIL ≤1/2" 5 "1/2< FUEIL ≤5/8" 6 "5/8< FUEIL ≤3/4" 7 "3/4< FUEIL ≤7/8" 8 "7/8< FUEIL ≤F";
VAL_ 896 IP_FuelGageType 0 "指针式" 1 "段码式" 2 "预留";

VAL_ 614 PEPS_Easy_open 0 "no command" 1 "自动感应信号";
VAL_ 614 PEPS_KeyNumber 0 "invalid" 1 "Key1-Key6" 7 "Reserved";
VAL_ 614 PEPS_PEPSFailStatus 0 "No Error，0x1=Error";
VAL_ 614 PEPS_PowerDistributionFaultBit 0 "No Error" 1 "Error";
VAL_ 614 PEPS_EngineStartupInhibitFb 0 "inactive" 1 "Inhibit succes";
VAL_ 614 PEPS_ImmoFeedback 0 "Inactive非认证状态" 1 "Authenticating认证中" 2 "Success成功" 3 "Failed失败";
VAL_ 614 PEPS_KeyAuthenticationStatus 0 "Inactive非认证状态" 1 "start认证中" 2 "Success成功" 3 "failed失败";
VAL_ 614 PEPS_EngineStartupInhibitSts 0 "Not inhibit" 1 "Inhibit";
VAL_ 614 PEPS_RemoteStartFeedback 0 "无反馈" 1 "启动成功" 2 "连续启动次数过多" 3 "整车电量不足" 4 "车门或引擎盖或行李箱未关闭" 5 "遥控钥匙在车内" 6 "防盗激活" 7 "紧急报警灯光激活" 8 "整车不在P档" 9 "车速不为0" 10 "发动机已经运行" 11 "电子手刹未夹紧" 12 "油量不足" 13 "启动系统故障" 14 "发动机机油压力过低" 15 "发动机冷却液温度过高" 16 "电喷系统故障" 17 "运行10分钟正常熄火" 18 "环境温度过低" 19 "周边防盗未处于设防状态" 20 "远程/遥控熄火成功" 21 " Reserved";
VAL_ 614 PEPS_RemoteStartReq 0 "Not Remote Start" 1 "Remote Start" 2 "Reserved" 3 "invalid";
VAL_ 614 PEPS_StartupButtonSignal 0 "OFF" 1 " N" 2 "Error" 3 "不可用";
VAL_ 614 PEPS_TrunkRequestSignal 0 "OFF" 1 "行李箱按钮被按下";
VAL_ 614 PEPS_DoorHandleButtonSignal 0 "OFF;  0x1=驾驶侧门按钮被按下";
VAL_ 614 PEPS_PowerDistributionStatus 0 "OFF" 1 "ACC" 2 "ON" 3 "Start";
VAL_ 614 PEPS_StartControlsignal 0 "No Request" 1 "Startup Start" 2 "Startup Stop" 3 "Invalid";
VAL_ 614 PEPS_StartIndicatorSignal 0 "Inactive" 1 "请踩下制动踏板提示";
VAL_ 614 PEPS_UnallowStart_ESCL_Error 0 "Inactive" 1 "ESCL故障";
VAL_ 614 PEPS_UnallowStart_ESCL_LOCK 0 "Inactive" 1 "ESCL未解锁";
VAL_ 614 PEPS_IMMOFailedAlarmsignal 0 "Inactive" 1 "IMMO与EMS认证失败";
VAL_ 614 PEPS_RemoteFailedAlarmSignal 0 "Inactive" 1 "钥匙认证失败";
VAL_ 614 PEPS_UnallowStartSignal_Not_PN 0 "Inactive" 1 "未在P/N档";
VAL_ 614 PEPS_KeyUndetectedAlarmSignal 0 "Inactive" 1 "ON";
VAL_ 614 PEPS_KeyInCarAlarmSignal 0 "Inactive" 1 "ON";
VAL_ 614 PEPS_UnlockModeTransitionSignal 0 "Inactive;  0x1=Exchange";
VAL_ 614 PEPS_LuggageUnlockSignal 0 "Inactive;  0x1=遥控行李箱解锁" 2 "PE行李箱解锁" 3 "不可用";
VAL_ 614 PEPS_SearchCarSignal 0 "Inactive" 1 "ON";
VAL_ 614 PEPS_RemoteWindowDownSignal 0 "Inactive" 1 "ON";
VAL_ 614 PEPS_RemoteWindowUpSignal 0 "Inactive" 1 "ON";
VAL_ 614 PEPS_LockSignal 0 "Inactive" 1 "遥控闭锁" 2 "PE闭锁" 3 "不可用";
VAL_ 614 PEPS_UnlockSignal 0 "Inactive" 1 "遥控解锁" 2 "左前PE解锁" 3 "右前PE解锁";
VAL_ 614 PEPS_KeyBatteryStatus 0 "Inactive" 1 "EXchangeKeyBattery";
VAL_ 614 PEPS_KeyPositionStatus 0 "未探测到钥匙" 1 "钥匙在车内" 2 "钥匙在行李箱内" 3 "钥匙在左前门激活区" 4 "钥匙在行李箱激活区" 5 "保留 ";

VAL_ 816 AC_AutowindSet3Status 0 "Invalid" 1 "OFF" 2 "ON" 3 "Reserved";
VAL_ 816 AC_AutowindSet2Status 0 "Invalid" 1 "OFF" 2 "ON" 3 "Reserved";
VAL_ 816 AC_AutowindSet1Status 0 "Invalid" 1 "OFF" 2 "ON" 3 "Reserved";
VAL_ 816 AC_EnvironmentalTemp 0 "-40~87℃" 255 "Invalid";
VAL_ 816 AC_EnvironmentalTempVD 0 "Valid" 1 "Invalid";
VAL_ 816 AC_AC_ReqValid 0 "Valid" 1 "Invalid";
VAL_ 816 AC_AC_Req 0 "OFF" 1 "ON";
VAL_ 816 AC_FrReqWindLevel 0 "OFF" 1 "Level 1" 2 "Level 2" 3 "Level 3" 4 "Level 4" 5 "Level 5" 6 "Level 6" 7 "Level 7" 8 "Level 8" 9 "Level 0(扇叶）" 10 "Reserved" 15 " Invaild";
VAL_ 816 AC_SystemFailureFlag 0 "Not Failure" 1 "Failure";
VAL_ 816 AC_RearDefrosterSwitch 0 "无操作" 1 "操作";

VAL_ 648 BCM_DriverDoorStatus 0 "Close" 1 "Open";
VAL_ 648 BCM_BuzzerWarningMode 0 "OFF" 1 "FollwoMeLight" 2 "LockSpeedSetOFF" 3 "LockSpeedSetON" 4 "KeyLearnSuccess" 5 "DriverDoorUnlockModeSetOFF" 6 "DriverDoorUnlockModeSetON" 7 "Reserved" 16 "LightON" 17 "RoofWinOpen" 18 "KeyInCarAlarm" 19 "KeyUndetectedAlarm" 20 "ExitActiveArm" 21 "DoorOpenLock" 22 "KeyLowBat" 23 "PassengerSeatBeltWarning" 24 "Reserved" 25 "DriverSeatBeltWarning" 26 "Reserved" 27 "DoorOpen" 28 "PowerManagementNotice" 29 "PowerDownWarning" 30 "Reserved";
VAL_ 648 BCM_SystemFailureFlag 0 "No Error" 1 "Error";
VAL_ 648 BCM_LatchOverheatProtect 0 "OFF" 1 "ON";
VAL_ 648 BCM_FollowMeTurnon 0 "OFF" 1 "ON";
VAL_ 648 BCM_ReversePosition 0 "NOT IN Reverse" 1 "IN Reverse";
VAL_ 648 BCM_TurnLightSwitchSts 0 "Not Actived" 1 "Left Actived" 2 "Right Actived" 3 "Invalid";
VAL_ 648 BCM_KeyAlarmStatus 0 "Disarmed" 1 "Prearmed" 2 "Armed" 3 "Activated";
VAL_ 648 BCM_Statusrainsensor 0 "NO error" 1 "Error";
VAL_ 648 BCM_KeyInSignal 0 "KeyOut" 1 "KeyIn ";
VAL_ 648 BCM_DriverDoorLockStatus 0 "Lock" 1 "Unlock" 2 "Not used" 3 "Error";
VAL_ 648 BCM_PowerStatusFeedback 0 "OFF" 1 "ACC" 2 "ON" 3 "Start";
VAL_ 648 BCM_RearWiperStatus 0 "OFF" 1 "ON";
VAL_ 648 BCM_Statuslowbeam 0 "NO error" 1 "Error";
VAL_ 648 BCM_FrontWiperStatus 0 "OFF" 1 "Low" 2 "High" 3 "Error";
VAL_ 648 BCM_RearDefrosterstatus 0 "OFF" 1 "ON" 2 "Not used" 3 "Reserved";
VAL_ 648 BCM_emergencylightstatus 0 "OFF" 1 "ON" 2 "Not used" 3 "Error（故障）";
VAL_ 648 BCM_SunroofMotor 0 "OFF" 1 "Running" 2 "Not used" 3 "Error(Reserved)";
VAL_ 648 BCM_RightRearWinMotor 0 "OFF" 1 "Running" 2 "Not used" 3 "Error(Reserved)";
VAL_ 648 BCM_LeftRearWinMotor 0 "OFF" 1 "Running" 2 "Not used" 3 "Error(Reserved)";
VAL_ 648 BCM_PassengerWinMotor 0 "OFF" 1 "Running" 2 "Not used" 3 "Error(Reserved)";
VAL_ 648 BCM_DriverWinMotor 0 "OFF" 1 "Running" 2 "Not used" 3 "Error(Reserved)";
VAL_ 648 BCM_AutoHeadlightSts 0 "Not Actived" 1 "Actived";
VAL_ 648 BCM_SunroofStatus 0 "Close" 1 "Open";
VAL_ 648 BCM_HoodStatus 0 "Close" 1 "Open";
VAL_ 648 BCM_TrunkDoorStatus 0 "Close" 1 "Open";
VAL_ 648 BCM_RightRearDoorStatus 0 "Close" 1 "Open";
VAL_ 648 BCM_LeftRearDoorStatus 0 "Close" 1 "Open";
VAL_ 648 BCM_PassengerDoorStatus 0 "Close" 1 "Open";
VAL_ 648 BCM_DriverDoorStatus 0 "Close" 1 "Open";
VAL_ 648 BCM_FrontWashStatus 0 "OFF" 1 "ON" 2 "Not used" 3 "Error";
VAL_ 648 BCM_PositionLampStatus 0 "OFF" 1 "ON" 2 "Not used" 3 "Reserved";
VAL_ 648 BCM_TurnIndicatorRight 0 "OFF" 1 "ON" 2 "Not used" 3 "Error";
VAL_ 648 BCM_TurnIndicatorLeft 0 "OFF" 1 "ON" 2 "Not used" 3 "Error";
VAL_ 648 BCM_RearFoglampStatus 0 "OFF" 1 "ON" 2 "Not used" 3 "Erro";
VAL_ 648 BCM_FrontFoglampStatus 0 "OFF" 1 "ON" 2 "Not used" 3 "Reserved";
VAL_ 648 BCM_HighBeamStatus 0 "OFF" 1 "ON" 2 "Not used" 3 "Reserved";
VAL_ 648 BCM_LowBeamStatus 0 "OFF" 1 "ON" 2 "Not used" 3 "Reserved";
VAL_ 648 BCM_BuzzerWarningMode 0 "OFF" 1 "FollwoMeLight" 2 "LockSpeedSetOFF" 3 "LockSpeedSetON" 4 "KeyLearnSuccess" 5 "DriverDoorUnlockModeSetOFF" 6 "DriverDoorUnlockModeSetON" 7 "Reserved" 16 "LightON" 17 "RoofWinOpen" 18 "KeyInCarAlarm" 19 "KeyUndetectedAlarm" 20 "ExitActiveArm" 21 "DoorOpenLock" 22 "KeyLowBat" 23 "PassengerSeatBeltWarning" 24 "Reserved" 25 "DriverSeatBeltWarning" 26 "Reserved" 27 "DoorOpen" 28 "PowerManagementNotice" 29 "PowerDownWarning" 30 "Reserved";
VAL_ 648 BCM_FollowMeTurnon 0 "OFF" 1 "ON";
VAL_ 648 BCM_ReversePosition 0 "NOT IN Reverse" 1 "IN Reverse";
VAL_ 648 BCM_TurnLightSwitchSts 0 "Not Actived" 1 "Left Actived" 2 "Right Actived" 3 "Invalid";
VAL_ 648 BCM_KeyAlarmStatus 0 "Disarmed" 1 "Prearmed" 2 "Armed" 3 "Activated";
VAL_ 648 BCM_Statusrainsensor 0 "NO error" 1 "Error";
VAL_ 648 BCM_KeyInSignal 0 "KeyOut" 1 "KeyIn ";
VAL_ 648 BCM_PowerStatusFeedback 0 "OFF" 1 "ACC" 2 "ON" 3 "Start";
VAL_ 648 BCM_Statuslowbeam 0 "NO error" 1 "Error";
VAL_ 648 BCM_RearWiperStatus 0 "OFF" 2 "ON";
VAL_ 648 BCM_SunroofStatus 0 "Close" 1 "Open";
VAL_ 648 BCM_HoodStatus 0 "Close" 1 "Open";
VAL_ 648 BCM_TrunkDoorStatus 0 "Close" 1 "Open";
VAL_ 648 BCM_RightRearDoorStatus 0 "Close" 1 "Open";
VAL_ 648 BCM_LeftRearDoorStatus 0 "Close" 1 "Open";
VAL_ 648 BCM_PassengerDoorStatus 0 "Close" 1 "Open";
VAL_ 648 BCM_DriverDoorStatus 0 "Close" 1 "Open";
VAL_ 648 BCM_PositionLampStatus 0 "OFF" 1 "ON" 2 "Not used" 3 "Reserved";
VAL_ 648 BCM_TurnIndicatorRight 0 "OFF" 1 "ON" 2 "Not used" 3 "Error";
VAL_ 648 BCM_TurnIndicatorLeft 0 "OFF" 1 "ON" 2 "Not used" 3 "Error";
VAL_ 648 BCM_RearFoglampStatus 0 "OFF" 1 "ON" 2 "Not used" 3 "Error";
VAL_ 648 BCM_FrontFoglampStatus 0 "OFF" 1 "ON" 2 "Not used" 3 "Reserved";
VAL_ 648 BCM_HighBeamStatus 0 "OFF" 1 "ON" 2 "Not used" 3 "Reserved";
VAL_ 648 BCM_LowBeamStatus 0 "OFF" 1 "ON" 2 "Not used" 3 "Reserved";

VAL_ 841 BCM_CarMode 0 "车辆处于用户模式" 1 "车辆处于工厂模式" 2 "车辆处于运输模式" 3 "Reserved";
VAL_ 841 BCM_PMSErrorFlag 0 "normal" 1 "Error 1" 2 "Erro 2" 3 "Error 3";
VAL_ 841 BCM_LowPowerWarning 0 "无动作" 1 "即将关闭电源" 2 "关闭电源" 3 "预留Reserved";
VAL_ 841 BCM_PMSLevel 0 "电量正常" 1 "低电量" 2 "Reserved";
VAL_ 841 BCM_CarMode 0 "车辆处于用户模式" 1 "车辆处于工厂模式" 2 "车辆处于运输模式" 3 "Reserved";
VAL_ 841 BCM_LowPowerWarning 0 "无动作" 1 "即将关闭电源" 2 "关闭电源" 3 "预留Reserved";
VAL_ 841 BCM_PMSLevel 0 "电量正常" 1 "低电量" 2 "Reserved";

VAL_ 640 IP_FuelLowVoiceAlarm 0 "no alarm" 1 "alarm";
VAL_ 640 IP_WelcomeSoundAlarm 0 "no alarm" 1 "alarm";
VAL_ 640 IP_SteeringReturnVoiceAlarm 0 "no alarm" 1 "alarm";
VAL_ 640 IP_120kmVoiceAlarm 0 "no alarm" 1 "alarm";
VAL_ 640 IP_MaintainReset 0 "Not Reset" 1 "Rest";
VAL_ 640 IP_FuelLow 0 "normal ;0x1=low";
VAL_ 640 IP_ModeSeting 0 "normal" 1 "light" 2 "heavy" 3 "norequest";
VAL_ 640 IP_PassengerLCDALEDSts 0 "No Error" 1 "Error";
VAL_ 640 IP_DriverLCDALEDSts 0 "No Error" 1 "Error";
VAL_ 640 EngineCoolanTemperatureHigh 0 "normal" 1 "high";
VAL_ 640 IP_EngineOilPressureLowSts 0 "normal" 1 "low";
VAL_ 640 IP_AirBagSysWarningLampSts 0 "Lamp off-no failure" 1 "Lamp on-no failure" 2 "Lamp flashing-no failure" 3 "Failure-failure present";
VAL_ 640 IP_DISFail 0 "no error" 1 "error";
VAL_ 640 IP_QDashACCFail 0 "no error" 1 "error" 2 "reserved" 3 "reserved";

VAL_ 901 IP_RearSeatbeltWarningEnableFB 0 "inactive" 1 "Off" 2 "On" 3 "Reserved";
VAL_ 901 IP_WarningVolumeSettingFB 0 "Invalid" 1 "Low" 2 "Middle" 3 "High" 4 "Reserved";

VAL_ 1288 HU_IMS_LegalDriverFeedback 0 "Inactive非认证状态" 1 "start认证中" 2 "Success成功" 3 "failed失败";
VAL_ 1288 HU_IMS_DrowsinessStatus 0 " Awake;清醒。
0x1= Slightly Drowsy;轻度疲劳
0x2= Drowsy;重度疲劳                            
0x3-0x5 = Reserved.预留          0x6=Unknown                  0x7= Invalid";
VAL_ 1288 HU_IMS_DistractionStatus 0 " Not Distracted;未分散。
0x1 = Distracted;分散
0x2 = Reserved.预留
0x3 = Invalid";
VAL_ 1288 HU_IMS_DriverID 0 "";

VAL_ 1537 HU_AutoLeaveLockSet 0 "Inactive" 1 "Close" 2 "30s" 3 "60s" 4 "120s" 5 "180s" 6 "240s" 7 "300s";
VAL_ 1537 HU_AtmoLightAAEnable 0 "inactive" 1 "On" 2 "Off" 3 "Reserved";
VAL_ 1537 HU_DayLightSet 0 "inactive" 1 "On" 2 "Off" 3 "Reserved";
VAL_ 1537 HU_WelcomeLightSet 0 "inactive" 1 "On" 2 "Off" 3 "Reserved";
VAL_ 1537 HU_AtmoLightAutoAdjust 0 "invalid" 1 "darkle" 2 " close" 3 "Reserved";
VAL_ 1537 HU_TwiceLockDoorSet 0 "inactive" 1 "On" 2 "Off" 3 "Reserved";
VAL_ 1537 HU_FollowMeHomeLightSet 0 "inactive" 1 "Off" 2 "10s" 3 "30s" 4 "60s" 5 "120s" 6 "Reserved";
VAL_ 1537 HU_LaneChangeTurnLightSet 0 "inactive" 1 "Off" 2 "three times" 3 "five times" 4 "seven times" 5 "Reserved";
VAL_ 1537 HU_RKEUnlockDoorTypeSet 0 "inactive" 1 "Unlock four door" 2 "Unlock Driver door" 3 "Reserved";
VAL_ 1537 HU_AutoIGNOFFUnlockSet 0 "inactive" 1 "off" 2 "on" 3 "Reserved";
VAL_ 1537 HU_AutoSpeedLockSet 0 "inactive" 1 "off" 2 "on" 3 "Reserved";

VAL_ 760 HU_360AVMdetectionRequest 0 "No Request" 1 "All+Left" 2 "All+Right" 3 "All+ Front" 4 "All+Rear" 5 "180° Front" 6 "Left+Right" 7 "180°Rear";
VAL_ 760 HU_BcallReq 0 "no request" 1 "call up(拨电话）" 2 "hang up(挂电话）" 3 "Reserved";
VAL_ 760 HU_SurrondingMonitorDone 0 "No Feedback" 1 "Finished";
VAL_ 760 HU_APAModeSelect 0 "Parallel Mode（平行）" 1 "Cross Mode（垂直）" 2 "POC Mode （泊出）" 3 "Invalid" 4 "Echelon Mode（斜列式）" 5 "function  off" 6 "Reserved";
VAL_ 760 HU_RegisterStatus 0 "NoRegister" 1 "RegisterSucceed" 2 "RegisterUnsuccessful" 3 "Registered";
VAL_ 760 HU_TUIDReq 0 "NoRequest" 1 "Request" 2 "Reserved" 3 "Invalid";
VAL_ 760 HU_AVMswitch 0 "no request" 1 "request";
VAL_ 760 HU_PACModeSelect 0 "普通模式" 1 "平行模式" 2 "关闭辅助线" 3 "invalid";

VAL_ 761 HU_ACControlMode 0 "No Req" 1 "Touch Control" 2 "Voice Control" 3 "Invalid";
VAL_ 761 HU_SunroofControlReq 0 "NoReq" 1 "RoofClose" 2 "RoofOpen" 3 "Invalid";
VAL_ 761 HU_CirculationModeReq 0 "No Req" 1 "REC" 2 "FRS" 3 "AUTO R/F" 4 "REC/FRS" 5 "Reserved";
VAL_ 761 HU_ACreq 0 "No Req" 1 "Req" 2 "reserved" 3 "invalid";
VAL_ 761 HU_SyncReq 0 "No Req" 1 "Req" 2 "reserved" 3 "invalid";
VAL_ 761 HU_ACLRTempAdjustValueReq 0 "No Req" 1 "UP Req" 2 "DOWN Req" 3 "Reserved";
VAL_ 761 HU_ACFanAdjustValueReq 0 "No Req" 1 "Level1-8" 9 "UP Req" 10 "DOWN Req" 11 "reserve";
VAL_ 761 HU_ACFrontModeAdjustReq 0 "No Req" 1 "FACE" 2 "B/L" 3 "FOOT" 4 "F/D" 5 "MODE" 6 "reserve";
VAL_ 761 HU_ACLFTempAdjustValueReq 0 "No Req" 1 "LO" 2 "18~32℃" 31 "HI" 32 "UP Req" 33 "Down Req" 34 "Reserved";
VAL_ 761 HU_ACDEFAdjustReq 0 "No Req" 1 "OFF" 2 "ON" 3 "DEF";
VAL_ 761 HU_FrontACOffReq 0 "No Req" 1 "Req" 2 "reserved" 3 "invalid";
VAL_ 761 HU_FrontAUTOACOnReq 0 "No Req" 1 "Req" 2 "reserved" 3 "invalid";
VAL_ 761 HU_ACRDEFAdjustReq 0 "No Req" 1 "OFF" 2 "ON" 3 "DEF";

VAL_ 762 HU_navStatus 0 "normal" 1 "error";
VAL_ 762 HU_navSpeedLimitUnits 0 "unknown" 1 "unit kph" 2 "unit mph" 3 "reserved";
VAL_ 762 HU_navSpeedLimitStatus 0 "valid" 1 "invalid" 2 "reserved" 3 "reserved";
VAL_ 762 HU_navCurrentRoadType 6 "Reserved" 5 "road type class5:highway,national road ,speed road" 4 "road type class4:province road ,mainly road " 3 "road type class3:mainly road in city,normal province road,mainly street " 2 "road type class2:mainly road in city " 1 "road type class1:Secondary roads " 0 "road type unknown:small road,walking Street";

VAL_ 1280 HU_CurrentLocationValid 0 "Valid" 1 "Not Valid";

VAL_ 1281 HU_LocalTimeSystem 0 "24h" 1 "12h" 2 "Reserved" 3 "Invalid";
VAL_ 1281 HU_LocalTimeValid 0 "Valid" 1 "Not Valid";

VAL_ 1536 HU_AutowindSet3 0 "未设置" 1 "钥匙闭锁出风设置开启" 2 "钥匙闭锁出风设置关闭" 3 "Reserved";
VAL_ 1536 HU_AutowindSet2 0 "未设置" 1 "钥匙长按出风设置开启" 2 "钥匙长按出风设置关闭" 3 "Reserved";
VAL_ 1536 HU_AutowindSet1 0 "未设置" 1 "钥匙开锁出风设置开启" 2 "钥匙开锁出风设置关闭" 3 "Reserved";
VAL_ 1536 HU_RearWiperSet 0 "invalid" 1 "off" 2 "on0x3=Reserved";
VAL_ 1536 HU_EasyEntrySet 0 "inactive" 1 "off" 2 "on" 3 "Reserved";
VAL_ 1536 HU_MirrorSetStatus 0 "inactive" 1 "off" 2 "on" 3 "Reserved";
VAL_ 1536 HU_AtmosphereLightColorSet 0 "inactive" 1 "color1~color7";
VAL_ 1536 HU_AtmosphereLightBrightnessSet 0 "inactive" 1 "OFF" 2 "Level1~Level6";
VAL_ 1536 HU_SunroofRainDetectClostSet 0 "Inactive" 1 "Off" 2 "On" 3 "Reserved";
VAL_ 1536 HU_MirrorAutoFoldSet 0 "inactive" 1 "off" 2 "on" 3 "Reserved";

VAL_ 1408 HU_MaintainRemindReq 0 "无请求" 1 "保养预警请求" 2 "保养到期提示请求" 3 "Invalid";
VAL_ 1408 HU_LeaveMaintainDay 0 "0~3100天" 3101 "Reserved" 4095 "Invalid";
VAL_ 1408 HU_LeaveMaintainMileage 0 "0~100000" 100001 "Reserved" 1048575 "Invalid";

VAL_ 662 TBOX_BCallStatus 0 "IDLE" 1 "On the phone" 2 "Calling" 3 "being Called(somebody call)" 4 "Call Ended" 5 "Reserved" 7 "Invalid";
VAL_ 662 TBOX_RmoteRoof 0 "No Request" 1 "Close" 2 "Open" 3 "Reserved";
VAL_ 662 TBOX_SearchCarReq 0 "No Request" 1 "Light" 2 "Horn" 3 "Light And Horn";
VAL_ 662 TBOX_ACTempValueReq 0 "No Req" 1 "LO" 2 "18~32℃" 31 "HI";
VAL_ 662 TBOX_RemoteStartRunTime 0 "NoReq" 1 "10min" 2 "15min" 3 "20min" 4 "25min" 5 "30min" 6 "Reserved" 7 "Invalid";
VAL_ 662 TBOX_VINMatchStatus 0 "Not matched" 1 "matched" 2 "matched unsuccess" 3 "Reserved";
VAL_ 662 TBOX_VINReq 0 "No Request" 1 "Request" 2 "Reserved" 3 "Invalid";
VAL_ 662 TBOX_CallStatus 0 "IDLE" 1 "On the phone" 2 "Calling" 3 "being Called(somebody call)" 4 "Call Ended" 5 "Reserved";
VAL_ 662 TBOX_AudioRequest 0 "No Request" 1 "Request type 1" 2 "Reserved" 3 "Reserved";
VAL_ 662 TBOX_VehicleVedioDetectReq 0 "No Request" 1 "Request" 2 "Reserved" 3 "Invalid";
VAL_ 662 TBOX_LockCommand 0 "No Request" 1 "Remote Lock" 2 "Remote Unlock" 3 "Invalid";
VAL_ 662 TBOX_EngineStartupInhibit 0 "No Inhibit" 1 " Inhibit Engine Start" 2 "Reserved" 3 "Invalid";
VAL_ 662 TBOX_RemoteEngineStartupReq 0 "No Request" 1 "Engine Start" 2 "Engine Stop" 3 "Invalid";

VAL_ 1365 TBOX_CheckSum 0 " (Byte1 +Byte2 …+ Byte7) XOR 0xFF
注：Byte1指本报文第0字节，Byte2指本报文第1字节，以此类推。校验和包含本报文第0至第6字节。";

VAL_ 992 AVM_OverspeedWarning 0 "No Request" 1 "Request";
VAL_ 992 AVM_VisionAngle 0 "No Request" 1 "120°" 2 "180°" 3 "Invalid";
VAL_ 992 AVM_DisplayForm 0 "No Request" 1 "All+Front" 2 "All+Left" 3 "All+Right" 4 "All+rear" 5 "120°Front" 6 "180° Front" 7 "Left+Right" 8 "120°Rear" 9 "180°Rear" 10 "Invalid" 11 "Reserved";
VAL_ 992 AVM_LineOnOff 0 "Not Active" 1 "Open" 2 "Close" 3 "Invalid";
VAL_ 992 AVM_DisplayReq 0 "No Request" 1 "Request" 2 "Reserved" 3 "not used";

VAL_ 1535 BCM_MusicPlayRequestSignal 0 "inactive ; 0x1=start ; 0x2=end ; 0x3= illegal";
VAL_ 1535 BCM_Musiclightfeedback 0 "inactive" 1 "enter" 2 "exit" 3 "Reserved";
VAL_ 1535 BCM_MusicPlayRequestSignal 0 "OFF ; 0x1=On";
VAL_ 1535 BCM_OutWelcomeSoundFeedback 0 "No Feedback" 1 "Sound1" 2 "Sound2" 3 "Sound3" 4 "Sound4" 5 "Sound5" 6 "Reserved";
VAL_ 1535 BCM_AutoLeaveLockSetStatus 0 "Inactive" 1 "Close" 2 "30s" 3 "60s" 4 "120s" 5 "180s" 6 "240s" 7 "300s";
VAL_ 1535 BCM_AutoLockFeedback 0 "inactive" 1 "success" 2 "fail" 3 "Reserved";
VAL_ 1535 BCM_WinOpenWarn 0 "inactive" 1 "warning";
VAL_ 1535 BCM_TwiceLockDoorSetStatus 0 "inactive" 1 "On" 2 "Off" 3 "Reserved";
VAL_ 1535 BCM_RearWiperSetStatus 0 "invalid" 1 "off" 2 "on" 3 "Reserved";
VAL_ 1535 BCM_RemoteWindowDownSetStaus 0 "inactive" 1 "off" 2 "open" 3 "Reserved";
VAL_ 1535 BCM_SunroofRainSetStatus 0 "inactive;0x1=off;
0x2=on;0x3=Reserved;";
VAL_ 1535 BCM_MirrorAutoFoldSetStatus 0 "invalid" 1 "off" 2 "on" 3 "Reserved";
VAL_ 1535 BCM_FollowMeHomeLightSetStatus 0 "invalid" 1 "Off" 2 "10S" 3 "30S" 4 "60S" 5 "120S" 6 "Reserved";
VAL_ 1535 BCM_LaneChangeTurnLightSetStatus 0 "invalid" 1 "off" 2 "three times" 3 "five times" 4 "seven times" 5 "Reserved";
VAL_ 1535 BCM_RKEUnlockDoorTypeSetStatus 0 "invalid" 1 "Unlock four door" 2 "Unlock Driver door" 3 "Reserved";
VAL_ 1535 BCM_AutoIGNOFFUnlockSetStatus 0 "invalid" 1 "off" 2 "on" 3 "Reserved";
VAL_ 1535 BCM_AutoSpeedLockSetStatus 0 "invalid" 1 "off" 2 "on" 3 "Reserved";

VAL_ 1520 LCM_AtmoLightAutoAdjustSts 0 "invalid" 1 "darkle" 2 " close" 3 "Reserved";
VAL_ 1520 LCM_AtmoLightAAEnableSts 0 "inactive" 1 "On" 2 "Off" 3 "Reserved";
VAL_ 1520 LCM_DRLSetFB 0 "invalid" 1 "off" 2 "on" 3 "Reserved";
VAL_ 1520 LCM_Dimmerlevel 0 "白天模式" 1 "Level1~Level21" 31 "invalid";
VAL_ 1520 LCM_AmbientLightColorSetStas 0 "invalid" 1 "color1~color7";
VAL_ 1520 LCM_AmbientLightBrightSetStas 0 "invalid" 1 "off" 2 "Level1~Level6";

VAL_ 614 PEPS_Easy_open 0 "no command" 1 "自动感应信号";
VAL_ 614 PEPS_KeyNumber 0 "invalid" 1 "Key1-Key6" 7 "Reserved";
VAL_ 614 PEPS_PEPSFailStatus 0 "No Error，0x1=Error";
VAL_ 614 PEPS_PowerDistributionFaultBit 0 "No Error" 1 "Error";
VAL_ 614 PEPS_EngineStartupInhibitFb 0 "inactive" 1 "Inhibit succes";
VAL_ 614 PEPS_ImmoFeedback 0 "Inactive非认证状态" 1 "Authenticating认证中" 2 "Success成功" 3 "Failed失败";
VAL_ 614 PEPS_KeyAuthenticationStatus 0 "Inactive非认证状态" 1 "start认证中" 2 "Success成功" 3 "failed失败";
VAL_ 614 PEPS_EngineStartupInhibitSts 0 "Not inhibit" 1 "Inhibit";
VAL_ 614 PEPS_RemoteStartFeedback 0 "无反馈" 1 "启动成功" 2 "连续启动次数过多" 3 "整车电量不足" 4 "车门或引擎盖或行李箱未关闭" 5 "遥控钥匙在车内" 6 "防盗激活" 7 "紧急报警灯光激活" 8 "整车不在P档" 9 "车速不为0" 10 "发动机已经运行" 11 "电子手刹未夹紧" 12 "油量不足" 13 "启动系统故障" 14 "发动机机油压力过低" 15 "发动机冷却液温度过高" 16 "电喷系统故障" 17 "运行10分钟正常熄火" 18 "环境温度过低" 19 "周边防盗未处于设防状态" 20 "远程/遥控熄火成功" 21 " Reserved";
VAL_ 614 PEPS_RemoteStartReq 0 "Not Remote Start" 1 "Remote Start" 2 "Reserved" 3 "invalid";
VAL_ 614 PEPS_StartupButtonSignal 0 "OFF" 1 " N" 2 "Error" 3 "不可用";
VAL_ 614 PEPS_TrunkRequestSignal 0 "OFF" 1 "行李箱按钮被按下";
VAL_ 614 PEPS_DoorHandleButtonSignal 0 "OFF;  0x1=驾驶侧门按钮被按下";
VAL_ 614 PEPS_PowerDistributionStatus 0 "OFF" 1 "ACC" 2 "ON" 3 "Start";
VAL_ 614 PEPS_StartControlsignal 0 "No Request" 1 "Startup Start" 2 "Startup Stop" 3 "Invalid";
VAL_ 614 PEPS_StartIndicatorSignal 0 "Inactive" 1 "请踩下制动踏板提示";
VAL_ 614 PEPS_UnallowStart_ESCL_Error 0 "Inactive" 1 "ESCL故障";
VAL_ 614 PEPS_UnallowStart_ESCL_LOCK 0 "Inactive" 1 "ESCL未解锁";
VAL_ 614 PEPS_IMMOFailedAlarmsignal 0 "Inactive" 1 "IMMO与EMS认证失败";
VAL_ 614 PEPS_RemoteFailedAlarmSignal 0 "Inactive" 1 "钥匙认证失败";
VAL_ 614 PEPS_UnallowStartSignal_Not_PN 0 "Inactive" 1 "未在P/N档";
VAL_ 614 PEPS_KeyUndetectedAlarmSignal 0 "Inactive" 1 "ON";
VAL_ 614 PEPS_KeyInCarAlarmSignal 0 "Inactive" 1 "ON";
VAL_ 614 PEPS_UnlockModeTransitionSignal 0 "Inactive;  0x1=Exchange";
VAL_ 614 PEPS_LuggageUnlockSignal 0 "Inactive;  0x1=遥控行李箱解锁" 2 "PE行李箱解锁" 3 "不可用";
VAL_ 614 PEPS_SearchCarSignal 0 "Inactive" 1 "ON";
VAL_ 614 PEPS_RemoteWindowDownSignal 0 "Inactive" 1 "ON";
VAL_ 614 PEPS_RemoteWindowUpSignal 0 "Inactive" 1 "ON";
VAL_ 614 PEPS_LockSignal 0 "Inactive" 1 "遥控闭锁" 2 "PE闭锁" 3 "不可用";
VAL_ 614 PEPS_UnlockSignal 0 "Inactive" 1 "遥控解锁" 2 "左前PE解锁" 3 "右前PE解锁";
VAL_ 614 PEPS_KeyBatteryStatus 0 "Inactive" 1 "EXchangeKeyBattery";
VAL_ 614 PEPS_KeyPositionStatus 0 "未探测到钥匙" 1 "钥匙在车内" 2 "钥匙在行李箱内" 3 "钥匙在左前门激活区" 4 "钥匙在行李箱激活区" 5 "保留 ";

VAL_ 816 AC_AutowindSet3Status 0 "Invalid" 1 "OFF" 2 "ON" 3 "Reserved";
VAL_ 816 AC_AutowindSet2Status 0 "Invalid" 1 "OFF" 2 "ON" 3 "Reserved";
VAL_ 816 AC_AutowindSet1Status 0 "Invalid" 1 "OFF" 2 "ON" 3 "Reserved";
VAL_ 816 AC_EnvironmentalTemp 0 "-40~87℃" 255 "Invalid";
VAL_ 816 AC_EnvironmentalTempVD 0 "Valid" 1 "Invalid";
VAL_ 816 AC_AC_ReqValid 0 "Valid" 1 "Invalid";
VAL_ 816 AC_AC_Req 0 "OFF" 1 "ON";
VAL_ 816 AC_FrReqWindLevel 0 "OFF" 1 "Level 1" 2 "Level 2" 3 "Level 3" 4 "Level 4" 5 "Level 5" 6 "Level 6" 7 "Level 7" 8 "Level 8" 9 "Level 0(扇叶）" 10 "Reserved" 15 " Invaild";
VAL_ 816 AC_SystemFailureFlag 0 "Not Failure" 1 "Failure";
VAL_ 816 AC_RearDefrosterSwitch 0 "无操作" 1 "操作";

VAL_ 832 AC_ACOnOff 0 "OFF" 1 "ON" 2 "not used" 3 "invalid";
VAL_ 832 AC_EnvironmentalTemp_RAW 0 "-40~87℃" 255 "Invalid";
VAL_ 832 AC_PlasmaSt 0 "inactive" 1 "active";
VAL_ 832 AC_AQSSt 0 "inactive" 1 "active";
VAL_ 832 AC_RecycleType 0 "recycle" 1 "fresh " 2 "auto recycle" 3 "auto fresh" 4 "invalid" 5 "Reserved";
VAL_ 832 AC_ClimateDisplayReq 0 "inactive" 1 "active";
VAL_ 832 AC_PaReqTemp 0 "LO;
0x01-0x1D=18~32℃" 30 "HI;
0x1F=Invalid";
VAL_ 832 AC_DriverReqTemp 0 "LO;
0x01-0x1D=18~32℃" 30 "HI;
0x1F=Invalid";
VAL_ 832 AC_DriverReqTempModel 0 "Level 1" 1 "Level 2" 2 "Level 3" 3 "Level 4" 4 "Level 5" 5 "Level 6" 6 "Level 7" 7 "Level 8" 8 "Level 9" 9 "Level 10" 10 "Level 11" 11 "Level 12" 12 "Level 13" 13 "Level 14" 14 "Level 15" 15 "Level 16" 16 "reserved" 31 "invalid";
VAL_ 832 AC_AutoWorkStatus 0 "Singel mode" 1 "Dual mode" 2 "Triple mode" 3 "Quadruple mode";
VAL_ 832 AC_FrAutoSts 0 "灭灯" 1 "点灯" 2 "reserved" 3 "invalid";
VAL_ 832 AC_ACSt 0 "inactive" 1 "active";
VAL_ 832 AC_FrBlowType 0 "blow face" 1 "blow face/blow feet" 2 "blow feet" 3 "blow fee/defroster" 4 "defroster" 5 "Reserved" 7 "Invalid";

VAL_ 896 IP_EngineOffTime 0 "0-65533s" 65534 "65534 or >65534" 65535 "invalid";
VAL_ 896 IP_FuelLevel 0 "FUEIL≤E" 1 "E < FUEIL ≤1/8" 2 "1/8< FUEIL ≤1/4" 3 "1/4< FUEIL ≤3/8" 4 "3/8< FUEIL ≤1/2" 5 "1/2< FUEIL ≤5/8" 6 "5/8< FUEIL ≤3/4" 7 "3/4< FUEIL ≤7/8" 8 "7/8< FUEIL ≤F";
VAL_ 896 IP_FuelGageType 0 "指针式" 1 "段码式" 2 "预留";

VAL_ 688 EMS_SartPrompt 0 "无提示" 1 "踩离合和制动踏板启动" 2 "踩离合启动" 3 "预留";
VAL_ 688 EMS_ImmoConfiguration 0 "No IMMO" 1 "IMMO" 2 "Reserved;  0x3=Unreliable";
VAL_ 688 EPB_Status 0 "both brakes released" 1 "both brakes applied" 2 "both brakes in operation (applying/releasing)" 3 "unknown";
VAL_ 688 EPB_BrakeLightOnRequest 0 "brake light OFF" 1 "" 2 "not used" 3 "signal not available";
VAL_ 688 TCU_GearShiftPositon 0 "Parking; 0x1=Reverse" 2 "Neutral" 3 "D" 4 "D3" 5 "D2" 6 "L" 7 "M/S" 8 "G position" 9 "+ position" 10 "- position";
VAL_ 688 TCU_ShiftPostionValid 0 "Valid; 0x1=Invalid";
VAL_ 688 SRS_CrashOutputStatusCheckSum 0 "(SRS_CrashOutputStatus) XOR 0xF";
VAL_ 688 SRS_CrashOutputStatus 0 "No Crash" 1 "crash" 2 "Not Used";
VAL_ 688 EMS_ImmoFeedback 0 "Inactive" 1 "Authenticating" 2 "Success" 3 "Failed";
VAL_ 688 TCU_STLKfailure 0 "normal" 1 "error" 2 "Reserved" 3 "Unreliable";
VAL_ 688 EMS_EngineStartupEnd 0 "NO;  0x1=YES" 2 "Reserved;  0x3=Unreliable";
VAL_ 688 EMS_CompressorStatus 0 "OFF;  0x1=ON;
0x2=Reserved;  0x3=Invalid";
VAL_ 688 SAS_SteeringAngleValid 0 "valid" 1 "invalid";
VAL_ 688 SAS_Calibrated 0 "calibrated" 1 "not calibrated";
VAL_ 688 ESP_BrakeLightOnRequest 0 "brake light OFF;  0x1=brake light ON" 2 "not used" 3 "signal not available";
VAL_ 688 EMS_EngineStatus 0 "Stop" 1 "Crank" 2 "Running" 3 "Invalid";
VAL_ 688 EMS_BrakePedalStatus 0 "NotPressed" 1 "Pressed" 2 "Reserved" 3 "Error/Invalid";

VAL_ 800 EPB_FailureLamp 0 "Lamp OFF" 1 "Lamp ON" 2 "not used" 3 "Invalid";
VAL_ 800 EMS_EngineSpeedError 0 "No error" 1 "Error";
VAL_ 800 SAS_SASFailure 0 "no Failure" 1 "Failure";
VAL_ 800 ESP_ABSFailStatus 0 "No error" 1 "Error";
VAL_ 800 ESP_TCSFailStatus 0 "No error" 1 "Error";
VAL_ 800 EMS_CoolanTemperatureError 0 "No error" 1 "Error";
VAL_ 800 EMS_MIL 0 "Off" 1 "ON" 2 "Reserved" 3 "Error";
VAL_ 800 SRS_WarningLampStatus 0 "Lamp off" 1 "Lamp on" 2 "Lamp Flashing" 3 "Not Used";
VAL_ 800 SRS_PassengerBuckleSwitchStatus 0 "Buckled" 1 "Unbuckle" 2 "Lamp Flashing (Not Used)" 3 "Invalid" 0 "0x0";
VAL_ 800 SRS_DriverBuckleSwitchStatus 0 "Buckled" 1 "Unbuckle" 2 "Lamp Flashing Not Used)" 3 "Invalid" 0 "0x0";
VAL_ 800 ESP_VehicleSpeed 0 "0~360km/h" 6401 "Reserved" 8191 "Invalid";
VAL_ 800 ESP_VehicleSpeedValid 0 "Valid" 1 "Invalid";

VAL_ 806 EMS_SSMWarningLampCtrol 0 "OFF" 1 "ON";
VAL_ 806 EMS_CruiseUnavailDisplay 0 "NO Display" 1 "Display";
VAL_ 806 EMS_IdleStopStatus 0 "Not Idle stop" 1 "Idle stop";
VAL_ 806 EMS_CruiseIndicate 0 "OFF" 1 "ON";
VAL_ 806 EMS_CruiseControlStatus 0 "Off" 1 "Active" 2 "Stand by" 3 "Error";
VAL_ 806 EMS_CruiseActiveIndicate 0 "OFF" 1 "ON";

VAL_ 810 EMS_RemindGear 0 "Not Used" 2 "2nd gear" 3 "3rd gear" 4 "4th gear" 5 "5th gear" 6 "6th gear" 7 "invalid";
VAL_ 810 ESP_HBBFunctionStatus 0 "HBB Standby" 1 "HBB Vacuum Boost Failure" 2 "HBB Failure" 3 "Reserved";
VAL_ 810 EMS_RemindShiftGear 0 "no prompt" 1 "up gear" 2 "down gear" 3 "invalid";
VAL_ 810 ESP_AutoHoldAvailable 0 "Valid" 1 "Invalid";
VAL_ 810 ESP_HHC_Active 0 "function is not in active" 1 "function is in active";
VAL_ 810 ESP_AutoHoldActive 0 "NotActive" 1 "Active";
VAL_ 810 ESP_HHC_Available 0 "Available" 1 "Not Available";
VAL_ 810 TCU_GearForDisplay 0 "Reserved" 1 "1st gear" 2 "2nd gear" 3 "3rd gear" 4 "4th gear" 5 "5th gear" 6 "6th gear" 7 "Parking" 8 "Reverse" 9 "Neutral" 10 "D range" 11 "S range" 12 "2 range" 13 "L range" 14 "Unreliable" 15 "Invalid";
VAL_ 810 ESP_HDC_STATUS 0 "off" 1 "ON" 2 "Stand by" 3 "Error";
VAL_ 810 EPB_FunctionLamp 0 "Lamp OFF" 1 "Lamp ON" 2 "not used" 3 "Invalid";
VAL_ 810 EPB_SwitchPosition 0 "no request" 1 "Release request" 2 "Apply request" 3 "Error";
VAL_ 810 EPB_SwitchPositionValid 0 "valid (full function)" 1 "error, init or substitute value (no function)";
VAL_ 810 EPB_TextDisplay 0 "No text message" 1 "Gradient too high" 2 "Clampforce not enough" 3 "Fasten seatbelt" 4 "Open park brake by switch" 5 "Press brake pedal" 6 "reserved" 15 "Invalid";
VAL_ 810 ESP_ESPActiveStatus 0 "NotActive" 1 "Active";
VAL_ 810 EPS_EPSFailed 0 "No Fail" 1 "Fail";
VAL_ 810 ESP_ESPFunctionStatus 0 "OFF" 1 "ON";
VAL_ 810 ESP_EBDFailStatus 0 "No error" 1 "Error";
VAL_ 810 ACC_ACCMode 0 "OFF mode" 1 "Passive mode" 2 "Stand-By mode" 3 "Active-Control mode" 4 "Brake-Only mode" 5 "Override" 6 "Stand Wait mode" 7 "Failure mode";
VAL_ 810 AT_FailureLamp 0 "OFF" 1 "ON";

VAL_ 839 BCM_TirePresureSignalStatus 0 "reliable signal" 1 "unreliable signal";
VAL_ 839 TPMS_SystemFailureWarning 0 "No any error" 1 "System error";
VAL_ 839 TPMS_LRPressureWarning 0 "No warning" 1 "High pressure warning" 2 "Low pressure warning" 3 "Quik leakage" 4 "Lost Sensor" 5 "Sensor battery low" 6 "Sensor failure" 7 "Reserved";
VAL_ 839 TPMS_RRPressureWarning 0 "No warning" 1 "High pressure warning" 2 "Low pressure warning" 3 "Quik leakage" 4 "Lost Sensor" 5 "Sensor battery low" 6 "Sensor failure" 7 "Reserved";
VAL_ 839 TPMS_RFPressureWarning 0 "No warning" 1 "High pressure warning" 2 "Low pressure warning" 3 "Quik leakage" 4 "Lost Sensor" 5 "Sensor battery low" 6 "Sensor failure" 7 "Reserved";
VAL_ 839 TPMS_LFPressureWarning 0 "No warning" 1 "High pressure warning" 2 "Low pressure warning" 3 "Quik leakage" 4 "Lost Sensor" 5 "Sensor battery low" 6 "Sensor failure" 7 "Reserved";
VAL_ 839 TPMS_TirePosition 0 "No any sensor" 1 "Left Front tire" 2 "Right Front tire" 3 "Right Rear tire" 4 "Left Rear tire" 5 "reseved";
VAL_ 839 TPMS_LRTemperatureWarning 0 "No temperature warning" 1 "Temperature warning";
VAL_ 839 TPMS_RRTemperatureWarning 0 "No temperature warning" 1 "Temperature warning";
VAL_ 839 TPMS_RFTemperatureWarning 0 "No temperature warning" 1 "Temperature warning";
VAL_ 839 TPMS_LFTemperatureWarning 0 "No temperature warning" 1 "Temperature warning";
VAL_ 839 TPMS_SignalStatus 0 "Current Signal" 1 "Last Signal";
VAL_ 839 BCM_TirePresureSignalStatus 0 "reliable signal" 1 "unreliable signal";

VAL_ 886 EMS_EngineFuelCutOff 0 "False" 1 "True";
VAL_ 886 EMS_ClutchPedalStatus 0 "NotPressed" 1 "Pressed" 2 "Reserved" 3 "Error";
VAL_ 886 EMS_ConditionIdle 0 "False" 1 "True";

VAL_ 900 BCM_LightSensor 0 "Day" 1 "Night";
VAL_ 900 BCM_LockSignal 0 "Inactive" 1 "遥控闭锁" 2 "PE闭锁" 3 "不可用";
VAL_ 900 BCM_UnlockSignal 0 "Inactive" 1 "遥控解锁" 2 "左前PE解锁" 3 "右前PE解锁";
VAL_ 900 BCM_RemoteWindowDownSignal 0 "Inactive" 1 "ON";
VAL_ 900 BCM_RmoteUnLockFeedback 0 "NoFeedback" 1 "成功" 2 "热 保 护" 3 "非OFF档";
VAL_ 900 BCM_RmoteLockeFeedback 0 "NoFeedback" 1 "成功" 2 "车门未关" 3 "行李箱未关" 4 "非OFF档" 5 "热 保 护" 6 "预留" 7 "Invalid";
VAL_ 900 BCM_CarRemindFeedback 0 "NoFeedback" 1 "成功" 2 "失败" 3 "Invalid";
VAL_ 900 BCM_LockSignal 0 "Inactive" 1 "遥控闭锁" 2 "PE闭锁" 3 "不可用";
VAL_ 900 BCM_UnlockSignal 0 "Inactive" 1 "遥控解锁" 2 "左前PE解锁" 3 "右前PE解锁";

VAL_ 630 ESCL_SteeringLockError 0 "" 1 "";
VAL_ 630 ESCL_SteeringLockStuck 0 "Natural，0x1＝Stuck Error";
VAL_ 630 ESCL_SteeringLockWait 0 "Natural" 1 "Waiting Error";
VAL_ 630 ESCL_SteeringLockStatusS301 0 "Transition between unlock and lock" 1 "Reserved" 3 "lock" 4 "Reserved" 6 "unlock" 7 "Reserved";
VAL_ 630 ESCL_SteeringLockStatusReserve 7 "";

VAL_ 728 LAS_CheckSum 0 " (Byte1 +Byte2 …+ Byte7) XOR 0xFF
注：Byte1指本报文第0字节，Byte2指本报文第1字节，以此类推。校验和包含本报文第0至第6字节。";
VAL_ 728 LAS_HMALightDistribution 0 "High beam not recommended" 1 "High beam recommended";
VAL_ 728 LAS_HMAStatus 0 "Off" 1 "Standby" 2 "Active" 3 "Failure";
VAL_ 728 LAS_SLASpdLimitUnits 3 "reserved" 2 "" 1 "unit kph" 0 "unknown";
VAL_ 728 LAS_SLASpdLimit 0 "no speed limit detected";
VAL_ 728 LAS_SLAState 0 "off" 1 "fusion mode" 2 "vision only mode" 3 "navigation only mode" 4 "reserved" 5 "reserved" 6 "reserved" 7 "defect";
VAL_ 728 LAS_LKSStatus 0 "Off" 1 "Ready" 2 "On" 3 "reserved" 7 "Failure";
VAL_ 728 LAS_CalibrationStatus 0 "Calibration Success" 1 "Calibration In Process" 2 "Calibration Failed" 3 "reserved";
VAL_ 728 LAS_LDWReminder 0 "no Reminder" 1 "LDWLeftReminder" 2 "LDWRightReminer" 3 "reserved";
VAL_ 728 LAS_LASFailure 0 "No Error" 1 "camera blocked" 2 "temporary failure" 3 "permanent failure";
VAL_ 728 LAS_TakeoverReq 0 "Not Req" 1 "";
VAL_ 728 LAS_LDWStatus 0 "Off" 1 "Ready" 2 "On" 3 "Failure";
VAL_ 728 LDW_VibrationWarning 0 " No Warning不报警" 1 " Left Warning左报警" 2 "Right Warning右报警" 3 " Invalid.无效";

VAL_ 736 RRS_SystemFailureFlag 0 "Not Failure" 1 "Failure";
VAL_ 736 RRS_WarningFrequency 0 "不报警" 1 "前角（940Hz）" 2 "后角（750Hz）" 3 "错误报警（1500Hz）";
VAL_ 736 RRS_WarningType 0 "不报警" 1 "长鸣区报警" 2 "间歇音1报警（报警75ms，不报警175ms）" 3 "间歇音2报警（报警75ms，不报警425ms）" 4 "间歇音3报警（预留）" 5 "长鸣区前后同时报警（前角报警0.5s，后角报警0.5s）" 6 "错误3S报警（长鸣3s）" 7 "系统无错误提示（鸣叫0.5s）（预留）" 8 "Not Used";
VAL_ 736 RRS_SwitchIndicatorError 0 "No Error" 1 "Error";
VAL_ 736 RRS_SpkErrFlag 0 "Not Fault" 1 "Fault";
VAL_ 736 RRS_ctrlModulErrFlag 0 "Not Fault" 1 "Fault";
VAL_ 736 RRS_BattVoltErrFlag 0 "Not Fault" 1 "Fault";
VAL_ 736 RRS_RFMSnsErrFlag 0 "Not Fault" 1 "Fault";
VAL_ 736 RRS_LFMSnsErrFlag 0 "Not Fault" 1 "Fault";
VAL_ 736 RRS_RRMidSnsErrFlag 0 "Not Fault" 1 "Fault";
VAL_ 736 RRS_LRMidSnsErrFlag 0 "Not Fault" 1 "Fault";
VAL_ 736 RRS_RRCSnsErrFlag 0 "Not Fault" 1 "Fault";
VAL_ 736 RRS_LRCSnsErrFlag 0 "Not Fault" 1 "Fault";
VAL_ 736 RRS_RFCSnsErrFlag 0 "Not Fault" 1 "Fault";
VAL_ 736 RRS_LFCSnsErrFlag 0 "Not Fault" 1 "Fault";
VAL_ 736 RRS_RFMDistance 0 "No Obstacle Detected" 1 "distance of RRM is less than 40cm" 2 "distance range of RRM is from 40cm to 80cm" 3 "distance range of RRM is from 80cm to 100cm" 4 "reserved";
VAL_ 736 RRS_LFMDistance 0 "No Obstacle Detected" 1 "distance of RRM is less than 40cm" 2 "distance range of RRM is from 40cm to 80cm" 3 "distance range of RRM is from 80cm to 100cm" 4 "reserved";
VAL_ 736 RRS_LFCDistance 0 "No Obstacle Detected" 1 "distance of RRC is less than 40cm" 2 "distance range of RRC is from40cm to60cm" 3 "invalid";
VAL_ 736 RRS_RFCDistance 0 "No Obstacle Detected" 1 "distance of RRC is less than 40cm" 2 "distance range of RRC is from40cm to60cm" 3 "invalid";
VAL_ 736 RRS_LRCDistance 0 "No Obstacle Detected" 1 "distance of RRC is less than 40cm" 2 "distance range of RRC is from40cm to60cm" 3 "invalid";
VAL_ 736 RRS_RRCDistance 0 "No Obstacle Detected" 1 "distance of RRC is less than 40cm" 2 "distance range of RRC is from40cm to60cm" 3 "invalid";
VAL_ 736 RRS_LRMDistance 0 "No Obstacle Detected" 1 "distance of RRM is less than 40cm" 2 "distance range of RRM is from 40cm to 100cm" 3 "distance range of RRM is from 100cm to 150cm" 4 "reserved";
VAL_ 736 RRS_RRMDistance 0 "No Obstacle Detected" 1 "distance of RRM is less than 40cm" 2 "distance range of RRM is from 40cm to 100cm" 3 "distance range of RRM is from 100cm to 150cm " 4 "reserved";

VAL_ 1300 HU_DSMMemoryPositionFeedback 0 "Invalid" 1 "Yes" 2 "No" 3 "Reserved";
VAL_ 1300 HU_OverspeedWarningOffset 0 "-10~10km/h" 21 "Reserved" 31 "Invalid";
VAL_ 1300 HU_OverspeedWarningEnable 0 "Invalid" 1 "OFF" 2 "ON" 3 "Reserved";
VAL_ 1300 HU_OverspeedSoundWarningEnable 0 "Invalid" 1 "Off" 2 "On" 3 "Reserved";
VAL_ 1300 HU_SEWEnable 0 "Invalid" 1 "Off" 2 "On" 3 "Reserved";
VAL_ 1300 HU_RCWSoundEnable 0 "Invalid" 1 "Off" 2 "On" 3 "Reserved";
VAL_ 1300 HU_LDWShakeLev 0 "Invalid" 1 "low" 2 "normal" 3 "high";
VAL_ 1300 HU_LASWarningModeSelection 0 "Invalid" 1 "visual" 2 "sound" 3 "vibration" 4 "sound and vibration" 5 "Reserved";
VAL_ 1300 HU_SLASwitch 0 "off" 1 "on";
VAL_ 1300 HU_HMAEnable 0 "off" 1 "on";
VAL_ 1300 HU_RCWEnable 0 "Invalid" 1 "Off" 2 "On" 3 "Reserved";
VAL_ 1300 HU_CTAEnable 0 "Invalid;0x1 =Off;
0x2=On;  0x3= Reserved;";
VAL_ 1300 HU_BSDLCAEnable 0 "Invalid" 1 "Off" 2 "On" 3 "Reserved";
VAL_ 1300 HU_LASModeSelection 0 "Invalid" 1 "LDW" 2 "LKA" 3 "LCS" 4 "ASC" 5 "LDW+LKA" 6 "LDW+LCS" 7 "Reserved";
VAL_ 1300 HU_LdwSensitivity 0 "early_early_aktiv; 高灵敏;
0x1=early_late_aktiv正常灵敏;
0x2=late_late_aktiv预留暂不使用;
0x3=Fault;";

VAL_ 1301 HU_DistanceAlertEnable 0 "Invalid;0x1 =Off;
0x2=On;  0x3= Reserved;";
VAL_ 1301 HU_ACCObjEnable 0 "no voice;
0x1 = detection voice" 2 " no detection voice" 3 " both voice;";
VAL_ 1301 HU_FCWSensitivity 0 "high;
0x1=normal;
0x2=low;
0x3= Reserved;";
VAL_ 1301 HU_AutoBrakeEnable 0 "off" 1 "on;";
VAL_ 1301 HU_FCWEnable 0 "off" 1 "on;";
VAL_ 1301 HU_CruiseControlSet 0 "inactive;
0x1=Adaptive;
0x2=Constant speed;
0x3-0x7=Reserved;";

VAL_ 729 LAS_CheckSum_idxxE 0 " (Byte1 +Byte2 …+ Byte7) XOR 0xFF
注= Byte1指本报文第0字节，Byte2指本报文第1字节，以此类推。校验和包含本报文第0至第6字节。";
VAL_ 729 LDW_VoiceWarning 0 " No Warning不报警" 1 " Left Warning左报警" 2 "Right Warning右报警" 3 " Invalid.无效";
VAL_ 729 LAS_OverspeedSoundWarning 0 "No Warning" 1 "Warning" 2 "Reserved" 3 "Invalid";
VAL_ 729 LAS_OverspeedVisualWarning 0 "No Warning" 1 "Warning" 2 "Reserved" 3 "Invalid";
VAL_ 729 LAS_OverspeedWarningOffset 0 "-10~10km/h" 21 "Reserved" 31 "Invalid";
VAL_ 729 LAS_OverspeedWarningEnableStatus 0 "Invalid" 1 "OFF" 2 "ON" 3 "Reserved";
VAL_ 729 LAS_RLaneMarkerType 0 "dashed" 1 "solid" 2 "road edge" 3 "double lane mark" 4 "Botts' dots" 5 "other" 6 "reserved" 7 "invalid";
VAL_ 729 LAS_LLaneMarkerType 0 "dashed" 1 "solid" 2 "road edge" 3 "double lane mark" 4 "Botts' dots" 5 "other" 6 "reserved" 7 "invalid";
VAL_ 729 LAS_HostLaneRightStatus 0 "No display" 1 "Tracking" 2 "Intervention" 3 "Warning" 4 "keeping" 5 "crossing" 6 "reserved" 7 "invalid";
VAL_ 729 LAS_HostLaneLeftStatus 0 "No display" 1 "Tracking" 2 "Intervention" 3 "Warning" 4 "keeping" 5 "crossing" 6 "reserved" 7 "invalid";
VAL_ 729 LAS_OverspeedSoundWarnEnaSts 0 "Invalid" 1 "Off" 2 "On" 3 "Reserved";
VAL_ 729 LAS_LDWShakeLevStatus 0 "Invalid" 1 "low" 2 "normal" 3 "high";
VAL_ 729 LAS_LASWarningModeSelectStas 0 "Invalid" 1 "visual" 2 "sound" 3 "vibration" 4 "sound and vibration" 5 "Reserved";
VAL_ 729 LAS_SLASwitchStatus 0 "off" 1 "on";
VAL_ 729 LAS_HMAEnableStatus 0 "off" 1 "on";
VAL_ 729 LAS_LASModeSelectionStatus 0 "Invalid" 1 "LDW" 2 "LKA" 3 "LCS" 4 "ASC" 5 "LDW+LKA" 6 "LDW+LCS" 7 "Reserved";
VAL_ 729 LAS_LdwSensitivityStatus 0 "early_early_aktiv; 高灵敏" 1 "early_late_aktiv正常灵敏" 2 "late_late_aktiv预留暂不使用" 3 "Fault";

VAL_ 862 ACC_CheckSum_id35E 0 " (Byte1 +Byte2 …+ Byte7) XOR 0xFF
注: Byte1指本报文第0字节，Byte2指本报文第1字节，以此类推。校验和包含本报文第0至第6字节。";
VAL_ 862 ACC_CruiseControlSetStatus 0 "inactive" 1 "Adaptive" 2 "Constant speed" 3 "Reserved";
VAL_ 862 ACC_DistanceAlertEnableStatus 0 "Invalid" 1 "Off" 2 "On" 3 "Reserved";
VAL_ 862 ACC_ACCObjEnableStatus 0 "no voice" 1 "detection voice" 2 "no detection voice" 3 "both voice";
VAL_ 862 ACC_FCWSensitivityStatus 0 "high" 1 "normal" 2 "low" 3 " Reserved";
VAL_ 862 ACC_AutoBrakeEnableStatus 0 "off" 1 "on";
VAL_ 862 ACC_FCWEnableStatus 0 "off" 1 "on";
VAL_ 862 ACC_ACCFailInfo 0 "no error" 1 "error";
VAL_ 862 ACC_TakeOverReq 0 "no TakeOver request" 1 "valid TakeOver request";
VAL_ 862 ACC_ObjValid 0 "no object" 1 "target object detected";
VAL_ 862 ACC_TimeGapSet 0 "no display" 1 "1.0S" 2 "1.4S" 3 "1.8S" 4 "2.4S" 5 "Distance_5" 6 "Distance_6" 7 "Distance_7";
VAL_ 862 ACC_DistanceTarObj 0 "no display" 1 "distance_1 one bar" 2 "distance-2 two bars" 3 "distance-3 three bars" 4 "reverved";

VAL_ 992 AVM_OverspeedWarning 0 "No Request" 1 "Request";
VAL_ 992 AVM_VisionAngle 0 "No Request" 1 "120°" 2 "180°" 3 "Invalid";
VAL_ 992 AVM_DisplayForm 0 "No Request" 1 "All+Front" 2 "All+Left" 3 "All+Right" 4 "All+rear" 5 "120°Front" 6 "180° Front" 7 "Left+Right" 8 "120°Rear" 9 "180°Rear" 10 "Invalid" 11 "Reserved";
VAL_ 992 AVM_LineOnOff 0 "Not Active" 1 "Open" 2 "Close" 3 "Invalid";
VAL_ 992 AVM_DisplayReq 0 "No Request" 1 "Request" 2 "Reserved" 3 "not used";

VAL_ 850 DSM_DSMMemoryPosition 0 "No Request" 1 "Request" 2 "Reserved" 3 "Reserved";
VAL_ 850 DSM_MirrorSetStatus 0 "inactive" 1 "off" 2 "on" 3 "Reserved";
VAL_ 850 DSM_KeyMomerySts 0 "inactive" 1 "off" 2 "on" 3 "Reserved";
VAL_ 850 DSM_MemoryAlarm 0 "invalid" 1 "failed ;
0x2=successed" 3 "Reserved";
VAL_ 850 DSM_MemoryPosition 0 "Not_MemoryPosition" 1 "1 Position" 2 "2 Position" 3 "3 Position" 4 "4 Position" 5 "5 Position" 6 "Last position" 7 "Reserved";
VAL_ 850 DSM_EasyEntrySts 0 "inactive" 1 "off" 2 "on" 3 "Reserved";
VAL_ 850 DSM_GetMemoryReq 0 "No request" 1 "1 Position" 2 "2 Position" 3 "3 Position" 4 "4 Position" 5 "5 Position" 6 "Last position " 7 "reserved";
VAL_ 850 DSM_SetMemoryReq 0 "No request" 1 "1 Position" 2 "2 Position" 3 "3 Position" 4 "4 Position" 5 "5 Position" 6 "reserved";

VAL_ 890 GW_IDWarn2_CycletimeInsDet 0 "NO Warning" 1 "Warning";
VAL_ 890 GW_IDWarn1_WhitelistInsDet 0 "NO Warning" 1 "Warning";
VAL_ 890 GW_FirewallWarning 0 "NO Warning" 1 "Warning";

VAL_ 1306 HU_LanguageSync 0 "Chinese" 1 "English" 2 "Russian" 3 "Arabic 其他位预留";
VAL_ 1306 HU_ThemeChange 0 "theme1" 1 "theme1" 2 "theme2" 3 "其他位预留";
VAL_ 1306 HU_VC_VR 0 "Recording" 1 "Recognizing" 2 "Display" 3 "Reserved";
VAL_ 1306 HU_Seeoffanimation 0 "notactive";
VAL_ 1306 HU_APAActive 0 "disactive" 1 "active";
VAL_ 1306 HU_SlotUserSelected 0 "No selected" 1 "Left Slot 1" 2 "Left Slot 2" 3 "Right Slot 1" 4 "Right Slot 2" 5 "Reserved" 15 "Invalid";
VAL_ 1306 HU_ScreenPowerOn 0 "Off" 1 "On";

VAL_ 808 LCM_LASSwitch 0 "Not Push 未按下" 1 "Push 按下" 2 "Reserved 预留" 3 "Fault";

VAL_ 737 RFC_Sector_Dist 0 "0" 1 "1-126" 127 "invalid";
VAL_ 737 LFC_Sector_Dist 0 "0" 1 "1-126" 127 "invalid";
VAL_ 737 RRC_Sector_Dist 0 "0" 1 "1-126" 127 "invalid";
VAL_ 737 LRC_Sector_Dist 0 "0" 1 "1-126" 127 "invalid";
VAL_ 737 RRM_Sector_Dist 0 "0" 1 "1-254" 255 "invalid";
VAL_ 737 LRM_Sector_Dist 0 "0" 1 "1-254" 255 "invalid";

VAL_ 992 AVM_OverspeedWarning 0 "No Request" 1 "Request";
VAL_ 992 AVM_VisionAngle 0 "No Request" 1 "120°" 2 "180°" 3 "Invalid";
VAL_ 992 AVM_DisplayForm 0 "No Request" 1 "All+Front" 2 "All+Left" 3 "All+Right" 4 "All+rear" 5 "120°Front" 6 "180° Front" 7 "Left+Right" 8 "120°Rear" 9 "180°Rear" 10 "Invalid" 11 "Reserved";
VAL_ 992 AVM_LineOnOff 0 "Not Active" 1 "Open" 2 "Close" 3 "Invalid";
VAL_ 992 AVM_DisplayReq 0 "No Request" 1 "Request" 2 "Reserved" 3 "not used";

VAL_ 1299 HU_KeyRelevanceState 0 "Invalid" 1 "No key memorized" 2 "Key 1" 3 "Key 2" 4 "Key1 and Key2" 5 "Reserved";
VAL_ 1299 HU_UserSet 0 "Inactive" 1 "User1" 2 "User2" 3 "User3" 4 "User4" 5 "Reserved";
VAL_ 1299 HU_VisionAngleReq 0 "No Request" 1 "120°请求" 2 "180°请求" 3 "Invalid";

VAL_ 610 PEPS_WelcomeLightStaus 0 "inactive" 1 "On" 2 "Off" 3 "Reserved";

VAL_ 1319 HU_RearSeatbeltWarningEnable 0 "No Req" 1 "Off" 2 "On" 3 "Reserved";
VAL_ 1319 HU_IPWarningVolumeSetting 0 "No Req" 1 "Low" 2 "Middle" 3 "High" 4 "Reserved";
VAL_ 1319 HU_VC_AtmosphereLightReq 0 "Invalid" 1 "Off" 2 "On" 3 "Reserved";
VAL_ 1319 HU_VC_ShadingCurtainReq 0 "Invalid" 1 "Off" 2 "On" 3 "Reserved";

VAL_ 901 IP_RearSeatbeltWarningEnableFB 0 "inactive" 1 "Off" 2 "On" 3 "Reserved";
VAL_ 901 IP_WarningVolumeSettingFB 0 "Invalid" 1 "Low" 2 "Middle" 3 "High" 4 "Reserved";

VAL_ 1338 HU_MusicLightRequest 0 "inactive" 1 "enter" 2 "exit" 3 "Reserved";
VAL_ 1338 HU_MusicPlaySetBackSignal 0 "inactive" 1 "start" 2 "end;
0x3=Reserved";
VAL_ 1338 HU_WelcomeLightSetStatus 0 "Inactive" 1 "Off" 2 "NormalMode" 3 "Mode1" 4 "Mode2" 5 "Reserved";

VAL_ 957 HU_OutWelcomeSoundSet 0 "No Req" 1 "Sound1" 2 "Sound2" 3 "Sound3" 4 "Sound4" 5 "Sound5" 6 "Reserved";
VAL_ 957 HU_ToneLowSet 0 "No Req" 1 "-7~+7" 16 "Reserved";
VAL_ 957 HU_ToneMiddleSet 0 "No Req" 1 "-7~+7" 16 "Reserved";
VAL_ 957 HU_ToneHighSet 0 "No Req" 1 "-7~+7" 16 "Reserved";
VAL_ 957 HU_BalanceYSet 0 "No Req" 1 "-7~+7" 16 "Reserved";
VAL_ 957 HU_BalanceXSet 0 "No Req" 1 "-7~+7" 16 "Reserved";
VAL_ 957 HU_EQModeSet 0 "No Req" 1 "EQ1" 2 "EQ2" 3 "EQ3" 4 "EQ4" 5 "EQ5" 6 "EQ6" 7 "Reserved";
VAL_ 957 HU_SoundFileTransferStatus 0 "No Req
0x1=Off" 2 "On" 3 "Reserved";

VAL_ 958 AMP_MusicPlaySetBackSignal 0 "Inactive" 1 "Start" 2 "End" 3 "Reserved";
VAL_ 958 HU_OutWelcomeSoundFeedback 0 "No Feedback" 1 "Sound1" 2 "Sound2" 3 "Sound3" 4 "Sound4" 5 "Sound5" 6 "Reserved";
VAL_ 958 AMP_MuteFeedback 0 "No Feedback
0x1=Not Mute" 2 "Mute" 3 "Reserved";
VAL_ 958 AMP_EQModeFeedback 0 "No Feedback" 1 "EQ1" 2 "EQ2" 3 "EQ3" 4 "EQ4" 5 "EQ5" 6 "EQ6" 7 "Reserved";
VAL_ 958 AMP_SoundFileTransferFeedback 0 "No Feedback
0x1=Off" 2 "On" 3 "Reserved";
